VERSION "created by canmatrix"

NS_ :

BS_:

BU_:

BO_ 2164146432 LC: 8 Vector__XXX
 SG_ Running_Light_Command : 0|2@1+ (1,0) [0|3] "" Vector__XXX
 SG_ Alternate_Beam_Head_Light_Comman : 2|2@1+ (1,0) [0|3] "" Vector__XXX
 SG_ Low_Beam_Head_Light_Command : 4|2@1+ (1,0) [0|3] "" Vector__XXX
 SG_ High_Beam_Head_Light_Command : 6|2@1+ (1,0) [0|3] "" Vector__XXX
 SG_ Tractor_Front_Fog_Lights_Command : 8|2@1+ (1,0) [0|3] "" Vector__XXX
 SG_ Rotating_Beacon_Light_Command : 10|2@1+ (1,0) [0|3] "" Vector__XXX
 SG_ Right_Turn_Signal_Lights_Command : 12|2@1+ (1,0) [0|3] "" Vector__XXX
 SG_ Left_Turn_Signal_Lights_Command : 14|2@1+ (1,0) [0|3] "" Vector__XXX
 SG_ Back_Up_Light_and_Alarm_Horn_Com : 16|2@1+ (1,0) [0|3] "" Vector__XXX
 SG_ Center_Stop_Light_Command : 18|2@1+ (1,0) [0|3] "" Vector__XXX
 SG_ Right_Stop_Light_Command : 20|2@1+ (1,0) [0|3] "" Vector__XXX
 SG_ Left_Stop_Light_Command : 22|2@1+ (1,0) [0|3] "" Vector__XXX
 SG_ Implement_Clearance_Light_Comman : 24|2@1+ (1,0) [0|3] "" Vector__XXX
 SG_ Tractor_Clearance_Light_Command : 26|2@1+ (1,0) [0|3] "" Vector__XXX
 SG_ Implement_Marker_Light_Command : 28|2@1+ (1,0) [0|3] "" Vector__XXX
 SG_ Tractor_Marker_Light_Command : 30|2@1+ (1,0) [0|3] "" Vector__XXX
 SG_ Rear_Fog_Light_Command : 32|2@1+ (1,0) [0|3] "" Vector__XXX
 SG_ Tractor_Underside_Mounted_Work_L : 34|2@1+ (1,0) [0|3] "" Vector__XXX
 SG_ Tractor_Rear_Low_Mounted_Work_Li : 36|2@1+ (1,0) [0|3] "" Vector__XXX
 SG_ Tractor_Rear_High_Mounted_Work_L : 38|2@1+ (1,0) [0|3] "" Vector__XXX
 SG_ Tractor_Side_Low_Mounted_Work_Li : 40|2@1+ (1,0) [0|3] "" Vector__XXX
 SG_ Tractor_Side_High_Mounted_Work_L : 42|2@1+ (1,0) [0|3] "" Vector__XXX
 SG_ Tractor_Front_Low_Mounted_Work_L : 44|2@1+ (1,0) [0|3] "" Vector__XXX
 SG_ Tractor_Front_High_Mounted_Work_ : 46|2@1+ (1,0) [0|3] "" Vector__XXX
 SG_ Implement_OEM_Option_2_Light_Com : 48|2@1+ (1,0) [0|3] "" Vector__XXX
 SG_ Implement_OEM_Option_1_Light_Com : 50|2@1+ (1,0) [0|3] "" Vector__XXX
 SG_ Implement_Right_Facing_Work_Ligh : 52|2@1+ (1,0) [0|3] "" Vector__XXX
 SG_ Implement_Left_Facing_Work_Light : 54|2@1+ (1,0) [0|3] "" Vector__XXX
 SG_ Lighting_Data_Request_Command : 56|2@1+ (1,0) [0|3] "" Vector__XXX
 SG_ Implement_Right_Forward_Work_Lig : 58|2@1+ (1,0) [0|3] "" Vector__XXX
 SG_ Implement_Left_Forward_Work_Ligh : 60|2@1+ (1,0) [0|3] "" Vector__XXX
 SG_ Implement_Rear_Work_Light_Comman : 62|2@1+ (1,0) [0|3] "" Vector__XXX

BO_ 2164148736 ETC7: 8 Vector__XXX
 SG_ Transmission_Current_Range_Displ : 0|2@1+ (1,0) [0|3] "" Vector__XXX
 SG_ Transmission_Service_Indicator : 2|2@1+ (1,0) [0|3] "" Vector__XXX
 SG_ Transmission_Requested_Range_Dis0 : 4|2@1+ (1,0) [0|3] "" Vector__XXX
 SG_ Transmission_Requested_Range_Dis1 : 6|2@1+ (1,0) [0|3] "" Vector__XXX
 SG_ Transmission_Ready_for_Brake_Rel : 8|2@1+ (1,0) [0|3] "" Vector__XXX
 SG_ Active_Shift_Console_Indicator : 10|2@1+ (1,0) [0|3] "" Vector__XXX
 SG_ Transmission_Engine_Crank_Enable : 12|2@1+ (1,0) [0|3] "" Vector__XXX
 SG_ Transmission_Shift_Inhibit_Indic : 14|2@1+ (1,0) [0|3] "" Vector__XXX
 SG_ Transmission_Mode_4_Indicator : 16|2@1+ (1,0) [0|3] "" Vector__XXX
 SG_ Transmission_Mode_3_Indicator : 18|2@1+ (1,0) [0|3] "" Vector__XXX
 SG_ Transmission_Mode_2_Indicator : 20|2@1+ (1,0) [0|3] "" Vector__XXX
 SG_ Transmission_Mode_1_Indicator : 22|2@1+ (1,0) [0|3] "" Vector__XXX
 SG_ Transmission_Requested_Gear_Feed : 24|8@1+ (1,0) [0|255] "" Vector__XXX
 SG_ Transmission_Mode_5_Indicator : 32|2@1+ (1,0) [0|3] "" Vector__XXX
 SG_ Transmission_Mode_6_Indicator : 34|2@1+ (1,0) [0|3] "" Vector__XXX
 SG_ Transmission_Mode_7_Indicator : 36|2@1+ (1,0) [0|3] "" Vector__XXX
 SG_ Transmission_Mode_8_Indicator : 38|2@1+ (1,0) [0|3] "" Vector__XXX
 SG_ Transmission_Reverse_Gear_Shift_ : 40|2@1+ (1,0) [0|3] "" Vector__XXX

BO_ 2164148992 TCFG2: 8 Vector__XXX
 SG_ Transmission_Torque_Limit : 0|16@1+ (1,0) [0|65535] "" Vector__XXX

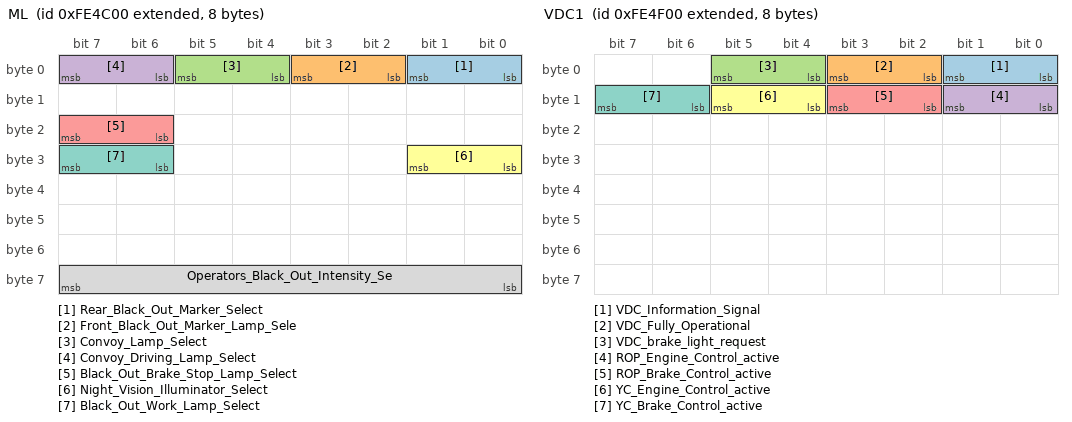
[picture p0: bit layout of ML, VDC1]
BO_ 2164149248 ML: 8 Vector__XXX
 SG_ Rear_Black_Out_Marker_Select : 0|2@1+ (1,0) [0|3] "" Vector__XXX
 SG_ Front_Black_Out_Marker_Lamp_Sele : 2|2@1+ (1,0) [0|3] "" Vector__XXX
 SG_ Convoy_Lamp_Select : 4|2@1+ (1,0) [0|3] "" Vector__XXX
 SG_ Convoy_Driving_Lamp_Select : 6|2@1+ (1,0) [0|3] "" Vector__XXX
 SG_ Black_Out_Brake_Stop_Lamp_Select : 22|2@1+ (1,0) [0|3] "" Vector__XXX
 SG_ Night_Vision_Illuminator_Select : 24|2@1+ (1,0) [0|3] "" Vector__XXX
 SG_ Black_Out_Work_Lamp_Select : 30|2@1+ (1,0) [0|3] "" Vector__XXX
 SG_ Operators_Black_Out_Intensity_Se : 56|8@1+ (1,0) [0|255] "" Vector__XXX

BO_ 2164149504 TAVG: 8 Vector__XXX
 SG_ Engine_Total_Average_Fuel_Rate : 0|16@1+ (1,0) [0|65535] "" Vector__XXX
 SG_ Engine_Total_Average_Fuel_Econom : 16|16@1+ (1,0) [0|65535] "" Vector__XXX

BO_ 2164149760 DC1: 8 Vector__XXX
 SG_ Position_of_doors : 0|4@1+ (1,0) [0|15] "" Vector__XXX
 SG_ Ramp___Wheel_Chair_Lift_Position : 4|2@1+ (1,0) [0|3] "" Vector__XXX
 SG_ Status_2_of_doors : 6|2@1+ (1,0) [0|3] "" Vector__XXX

BO_ 2164150016 VDC1: 8 Vector__XXX
 SG_ VDC_Information_Signal : 0|2@1+ (1,0) [0|3] "" Vector__XXX
 SG_ VDC_Fully_Operational : 2|2@1+ (1,0) [0|3] "" Vector__XXX
 SG_ VDC_brake_light_request : 4|2@1+ (1,0) [0|3] "" Vector__XXX
 SG_ ROP_Engine_Control_active : 8|2@1+ (1,0) [0|3] "" Vector__XXX
 SG_ ROP_Brake_Control_active : 10|2@1+ (1,0) [0|3] "" Vector__XXX
 SG_ YC_Engine_Control_active : 12|2@1+ (1,0) [0|3] "" Vector__XXX
 SG_ YC_Brake_Control_active : 14|2@1+ (1,0) [0|3] "" Vector__XXX

BO_ 2164150272 BT1: 8 Vector__XXX
 SG_ Battery_1_Temperature : 0|8@1+ (1,0) [0|255] "" Vector__XXX
 SG_ Battery_2_Temperature : 8|8@1+ (1,0) [0|255] "" Vector__XXX

BO_ 2164150528 ACC2: 8 Vector__XXX
 SG_ Requested_ACC_Distance_Mode : 5|3@1+ (1,0) [0|7] "" Vector__XXX

BO_ 2164150784 VEP3: 8 Vector__XXX
 SG_ Alternator_Current__High_Range_R : 0|16@1+ (1,0) [0|65535] "" Vector__XXX
 SG_ Net_Battery_Current__High_Range_ : 16|16@1+ (1,0) [0|65535] "" Vector__XXX

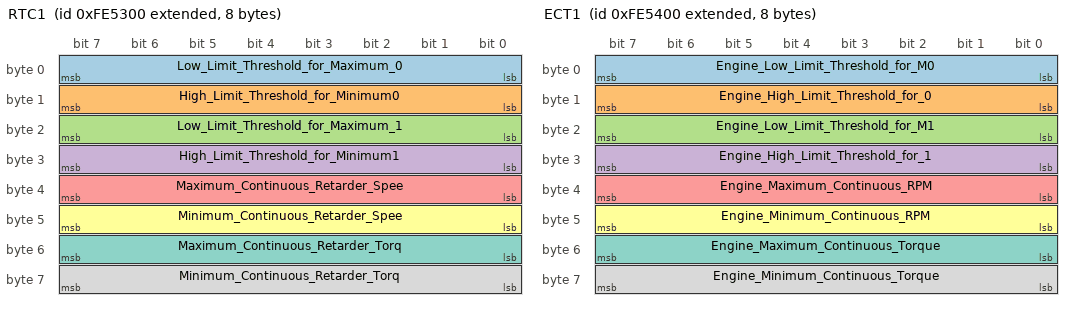
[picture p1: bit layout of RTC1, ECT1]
BO_ 2164151040 RTC1: 8 Vector__XXX
 SG_ Low_Limit_Threshold_for_Maximum_0 : 0|8@1+ (1,0) [0|255] "" Vector__XXX
 SG_ High_Limit_Threshold_for_Minimum0 : 8|8@1+ (1,0) [0|255] "" Vector__XXX
 SG_ Low_Limit_Threshold_for_Maximum_1 : 16|8@1+ (1,0) [0|255] "" Vector__XXX
 SG_ High_Limit_Threshold_for_Minimum1 : 24|8@1+ (1,0) [0|255] "" Vector__XXX
 SG_ Maximum_Continuous_Retarder_Spee : 32|8@1+ (1,0) [0|255] "" Vector__XXX
 SG_ Minimum_Continuous_Retarder_Spee : 40|8@1+ (1,0) [0|255] "" Vector__XXX
 SG_ Maximum_Continuous_Retarder_Torq : 48|8@1+ (1,0) [0|255] "" Vector__XXX
 SG_ Minimum_Continuous_Retarder_Torq : 56|8@1+ (1,0) [0|255] "" Vector__XXX

BO_ 2164151296 ECT1: 8 Vector__XXX
 SG_ Engine_Low_Limit_Threshold_for_M0 : 0|8@1+ (1,0) [0|255] "" Vector__XXX
 SG_ Engine_High_Limit_Threshold_for_0 : 8|8@1+ (1,0) [0|255] "" Vector__XXX
 SG_ Engine_Low_Limit_Threshold_for_M1 : 16|8@1+ (1,0) [0|255] "" Vector__XXX
 SG_ Engine_High_Limit_Threshold_for_1 : 24|8@1+ (1,0) [0|255] "" Vector__XXX
 SG_ Engine_Maximum_Continuous_RPM : 32|8@1+ (1,0) [0|255] "" Vector__XXX
 SG_ Engine_Minimum_Continuous_RPM : 40|8@1+ (1,0) [0|255] "" Vector__XXX
 SG_ Engine_Maximum_Continuous_Torque : 48|8@1+ (1,0) [0|255] "" Vector__XXX
 SG_ Engine_Minimum_Continuous_Torque : 56|8@1+ (1,0) [0|255] "" Vector__XXX

BO_ 2164151552 GFD: 8 Vector__XXX
 SG_ Specific_Heat_Ratio : 0|16@1+ (1,0) [0|65535] "" Vector__XXX

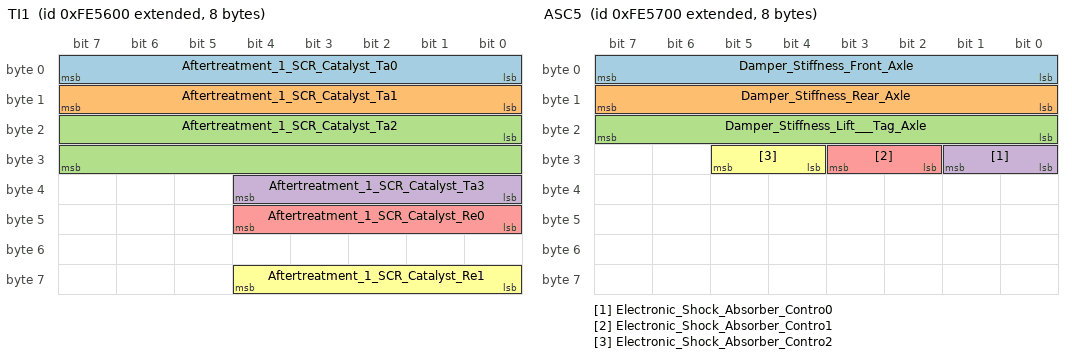
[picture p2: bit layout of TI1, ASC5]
BO_ 2164151808 TI1: 8 Vector__XXX
 SG_ Aftertreatment_1_SCR_Catalyst_Ta0 : 0|8@1+ (1,0) [0|255] "" Vector__XXX
 SG_ Aftertreatment_1_SCR_Catalyst_Ta1 : 8|8@1+ (1,0) [0|255] "" Vector__XXX
 SG_ Aftertreatment_1_SCR_Catalyst_Ta2 : 16|16@1+ (1,0) [0|65535] "" Vector__XXX
 SG_ Aftertreatment_1_SCR_Catalyst_Ta3 : 32|5@1+ (1,0) [0|31] "" Vector__XXX
 SG_ Aftertreatment_1_SCR_Catalyst_Re0 : 40|5@1+ (1,0) [0|31] "" Vector__XXX
 SG_ Aftertreatment_1_SCR_Catalyst_Re1 : 56|5@1+ (1,0) [0|31] "" Vector__XXX

BO_ 2164152064 ASC5: 8 Vector__XXX
 SG_ Damper_Stiffness_Front_Axle : 0|8@1+ (1,0) [0|255] "" Vector__XXX
 SG_ Damper_Stiffness_Rear_Axle : 8|8@1+ (1,0) [0|255] "" Vector__XXX
 SG_ Damper_Stiffness_Lift___Tag_Axle : 16|8@1+ (1,0) [0|255] "" Vector__XXX
 SG_ Electronic_Shock_Absorber_Contro0 : 24|2@1+ (1,0) [0|3] "" Vector__XXX
 SG_ Electronic_Shock_Absorber_Contro1 : 26|2@1+ (1,0) [0|3] "" Vector__XXX
 SG_ Electronic_Shock_Absorber_Contro2 : 28|2@1+ (1,0) [0|3] "" Vector__XXX

BO_ 2164152320 ASC4: 8 Vector__XXX
 SG_ Bellow_Pressure_Front_Axle_Left : 0|16@1+ (1,0) [0|65535] "" Vector__XXX
 SG_ Bellow_Pressure_Front_Axle_Right : 16|16@1+ (1,0) [0|65535] "" Vector__XXX
 SG_ Bellow_Pressure_Rear_Axle_Left : 32|16@1+ (1,0) [0|65535] "" Vector__XXX
 SG_ Bellow_Pressure_Rear_Axle_Right : 48|16@1+ (1,0) [0|65535] "" Vector__XXX

BO_ 2164152576 ASC3: 8 Vector__XXX
 SG_ Relative_Level_Front_Axle_Left : 0|16@1+ (1,0) [0|65535] "" Vector__XXX
 SG_ Relative_Level_Front_Axle_Right : 16|16@1+ (1,0) [0|65535] "" Vector__XXX
 SG_ Relative_Level_Rear_Axle_Left : 32|16@1+ (1,0) [0|65535] "" Vector__XXX
 SG_ Relative_Level_Rear_Axle_Right : 48|16@1+ (1,0) [0|65535] "" Vector__XXX

BO_ 2164152832 ASC1: 8 Vector__XXX
 SG_ Nominal_Level_Front_Axle : 0|4@1+ (1,0) [0|15] "" Vector__XXX
 SG_ Nominal_Level_Rear_Axle : 4|4@1+ (1,0) [0|15] "" Vector__XXX
 SG_ Below_Nominal_Level_Front_Axle : 8|2@1+ (1,0) [0|3] "" Vector__XXX
 SG_ Below_Nominal_Level_Rear_Axle : 10|2@1+ (1,0) [0|3] "" Vector__XXX
 SG_ Above_Nominal_Level_Front_Axle : 12|2@1+ (1,0) [0|3] "" Vector__XXX
 SG_ Above_Nominal_Level_Rear_Axle : 14|2@1+ (1,0) [0|3] "" Vector__XXX
 SG_ Lowering_Control_Mode_Front_Axle : 16|2@1+ (1,0) [0|3] "" Vector__XXX
 SG_ Lowering_Control_Mode_Rear_Axle : 18|2@1+ (1,0) [0|3] "" Vector__XXX
 SG_ Lifting_Control_Mode_Front_Axle : 20|2@1+ (1,0) [0|3] "" Vector__XXX
 SG_ Lifting_Control_Mode_Rear_Axle : 22|2@1+ (1,0) [0|3] "" Vector__XXX
 SG_ Kneeling_Information : 24|4@1+ (1,0) [0|15] "" Vector__XXX
 SG_ Level_Control_Mode : 28|4@1+ (1,0) [0|15] "" Vector__XXX
 SG_ Security_Device : 32|2@1+ (1,0) [0|3] "" Vector__XXX
 SG_ Vehicle_Motion_Inhibit : 34|2@1+ (1,0) [0|3] "" Vector__XXX
 SG_ Door_Release : 36|2@1+ (1,0) [0|3] "" Vector__XXX
 SG_ Lift_Axle_1_Position : 38|2@1+ (1,0) [0|3] "" Vector__XXX
 SG_ Front_Axle_in_Bumper_Range : 40|2@1+ (1,0) [0|3] "" Vector__XXX
 SG_ Rear_Axle_in_Bumper_Range : 42|2@1+ (1,0) [0|3] "" Vector__XXX
 SG_ Lift_Axle_2_Position : 46|2@1+ (1,0) [0|3] "" Vector__XXX
 SG_ Suspension_Remote_Control_1 : 48|2@1+ (1,0) [0|3] "" Vector__XXX
 SG_ Suspension_Remote_control_2 : 50|2@1+ (1,0) [0|3] "" Vector__XXX
 SG_ Suspension_Control_Refusal_Infor : 56|4@1+ (1,0) [0|15] "" Vector__XXX

BO_ 2164153088 FLI2: 8 Vector__XXX
 SG_ Lane_Tracking_Status_Right_Side : 2|2@1+ (1,0) [0|3] "" Vector__XXX
 SG_ Lane_Tracking_Status_Left_Side : 4|2@1+ (1,0) [0|3] "" Vector__XXX
 SG_ Lane_Departure_Indication_Enable : 6|2@1+ (1,0) [0|3] "" Vector__XXX

BO_ 2164155904 BM: 8 Vector__XXX
 SG_ Battery_Main_Switch_Hold_State : 0|2@1+ (1,0) [0|3] "" Vector__XXX

BO_ 2164156160 CCC: 8 Vector__XXX
 SG_ Auxiliary_Heater_Maximum_Output_ : 0|16@1+ (1,0) [0|65535] "" Vector__XXX

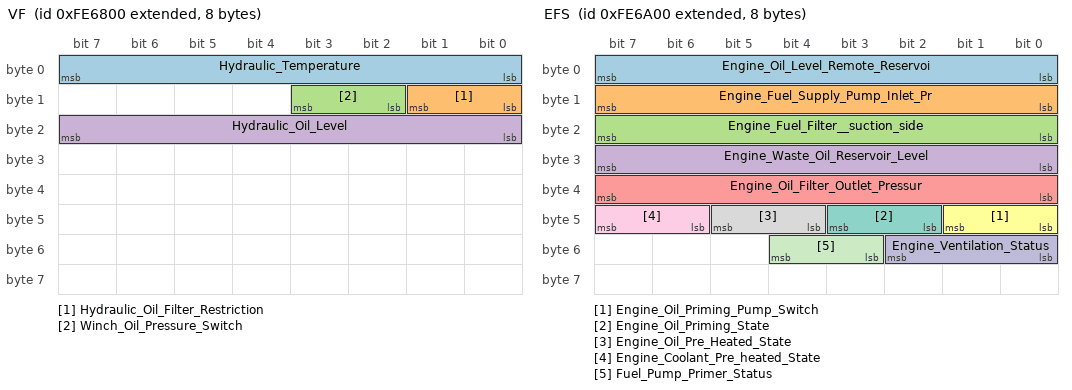
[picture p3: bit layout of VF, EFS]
BO_ 2164156416 VF: 8 Vector__XXX
 SG_ Hydraulic_Temperature : 0|8@1+ (1,0) [0|255] "" Vector__XXX
 SG_ Hydraulic_Oil_Filter_Restriction : 8|2@1+ (1,0) [0|3] "" Vector__XXX
 SG_ Winch_Oil_Pressure_Switch : 10|2@1+ (1,0) [0|3] "" Vector__XXX
 SG_ Hydraulic_Oil_Level : 16|8@1+ (1,0) [0|255] "" Vector__XXX

BO_ 2164156672 ET3: 8 Vector__XXX
 SG_ Engine_Intake_Manifold_1_Air_Tem : 0|16@1+ (1,0) [0|65535] "" Vector__XXX
 SG_ Engine_Coolant_Temperature__High : 16|16@1+ (1,0) [0|65535] "" Vector__XXX
 SG_ Engine_Intake_Valve_Actuation_Sy : 32|16@1+ (1,0) [0|65535] "" Vector__XXX
 SG_ Engine_Charge_Air_Cooler_Outlet_ : 48|16@1+ (1,0) [0|65535] "" Vector__XXX

BO_ 2164156928 EFS: 8 Vector__XXX
 SG_ Engine_Oil_Level_Remote_Reservoi : 0|8@1+ (1,0) [0|255] "" Vector__XXX
 SG_ Engine_Fuel_Supply_Pump_Inlet_Pr : 8|8@1+ (1,0) [0|255] "" Vector__XXX
 SG_ Engine_Fuel_Filter__suction_side : 16|8@1+ (1,0) [0|255] "" Vector__XXX
 SG_ Engine_Waste_Oil_Reservoir_Level : 24|8@1+ (1,0) [0|255] "" Vector__XXX
 SG_ Engine_Oil_Filter_Outlet_Pressur : 32|8@1+ (1,0) [0|255] "" Vector__XXX
 SG_ Engine_Oil_Priming_Pump_Switch : 40|2@1+ (1,0) [0|3] "" Vector__XXX
 SG_ Engine_Oil_Priming_State : 42|2@1+ (1,0) [0|3] "" Vector__XXX
 SG_ Engine_Oil_Pre_Heated_State : 44|2@1+ (1,0) [0|3] "" Vector__XXX
 SG_ Engine_Coolant_Pre_heated_State : 46|2@1+ (1,0) [0|3] "" Vector__XXX
 SG_ Engine_Ventilation_Status : 48|3@1+ (1,0) [0|7] "" Vector__XXX
 SG_ Fuel_Pump_Primer_Status : 51|2@1+ (1,0) [0|3] "" Vector__XXX

BO_ 2164157184 DI: 8 Vector__XXX
 SG_ Driver_1_identification : 0|13824@1+ (1,0) [0|2.745744098767810851571364370E+4161] "" Vector__XXX
 SG_ Driver_2_identification : 16|13824@1+ (1,0) [0|2.745744098767810851571364370E+4161] "" Vector__XXX

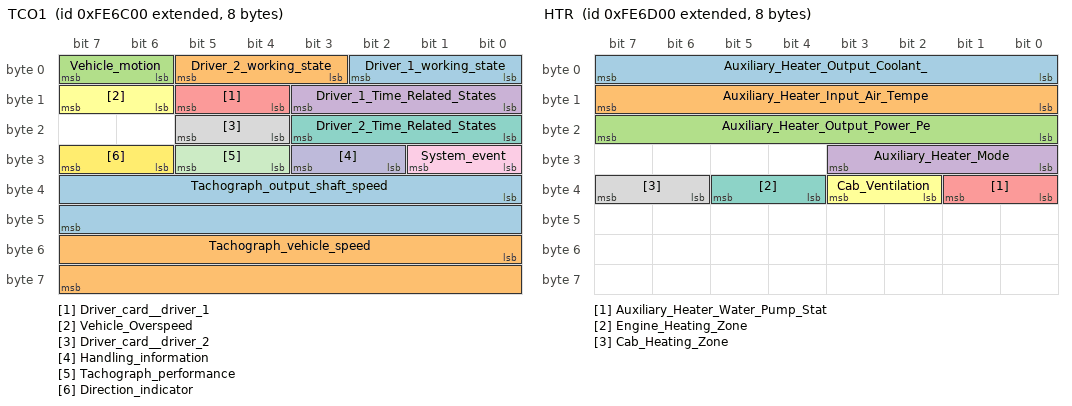
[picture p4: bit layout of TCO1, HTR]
BO_ 2164157440 TCO1: 8 Vector__XXX
 SG_ Driver_1_working_state : 0|3@1+ (1,0) [0|7] "" Vector__XXX
 SG_ Driver_2_working_state : 3|3@1+ (1,0) [0|7] "" Vector__XXX
 SG_ Vehicle_motion : 6|2@1+ (1,0) [0|3] "" Vector__XXX
 SG_ Driver_1_Time_Related_States : 8|4@1+ (1,0) [0|15] "" Vector__XXX
 SG_ Driver_card__driver_1 : 12|2@1+ (1,0) [0|3] "" Vector__XXX
 SG_ Vehicle_Overspeed : 14|2@1+ (1,0) [0|3] "" Vector__XXX
 SG_ Driver_2_Time_Related_States : 16|4@1+ (1,0) [0|15] "" Vector__XXX
 SG_ Driver_card__driver_2 : 20|2@1+ (1,0) [0|3] "" Vector__XXX
 SG_ System_event : 24|2@1+ (1,0) [0|3] "" Vector__XXX
 SG_ Handling_information : 26|2@1+ (1,0) [0|3] "" Vector__XXX
 SG_ Tachograph_performance : 28|2@1+ (1,0) [0|3] "" Vector__XXX
 SG_ Direction_indicator : 30|2@1+ (1,0) [0|3] "" Vector__XXX
 SG_ Tachograph_output_shaft_speed : 32|16@1+ (1,0) [0|65535] "" Vector__XXX
 SG_ Tachograph_vehicle_speed : 48|16@1+ (1,0) [0|65535] "" Vector__XXX

BO_ 2164157696 HTR: 8 Vector__XXX
 SG_ Auxiliary_Heater_Output_Coolant_ : 0|8@1+ (1,0) [0|255] "" Vector__XXX
 SG_ Auxiliary_Heater_Input_Air_Tempe : 8|8@1+ (1,0) [0|255] "" Vector__XXX
 SG_ Auxiliary_Heater_Output_Power_Pe : 16|8@1+ (1,0) [0|255] "" Vector__XXX
 SG_ Auxiliary_Heater_Mode : 24|4@1+ (1,0) [0|15] "" Vector__XXX
 SG_ Auxiliary_Heater_Water_Pump_Stat : 32|2@1+ (1,0) [0|3] "" Vector__XXX
 SG_ Cab_Ventilation : 34|2@1+ (1,0) [0|3] "" Vector__XXX
 SG_ Engine_Heating_Zone : 36|2@1+ (1,0) [0|3] "" Vector__XXX
 SG_ Cab_Heating_Zone : 38|2@1+ (1,0) [0|3] "" Vector__XXX

BO_ 2164157952 HRW: 8 Vector__XXX
 SG_ Front_Axle__Left_Wheel_Speed : 0|16@1+ (1,0) [0|65535] "" Vector__XXX
 SG_ Front_axle__right_wheel_speed : 16|16@1+ (1,0) [0|65535] "" Vector__XXX
 SG_ Rear_axle__left_wheel_speed : 32|16@1+ (1,0) [0|65535] "" Vector__XXX
 SG_ Rear_axle__right_wheel_speed : 48|16@1+ (1,0) [0|65535] "" Vector__XXX

BO_ 2164158208 ACC1: 8 Vector__XXX
 SG_ Speed_of_forward_vehicle : 0|8@1+ (1,0) [0|255] "" Vector__XXX
 SG_ Distance_to_forward_vehicle : 8|8@1+ (1,0) [0|255] "" Vector__XXX
 SG_ Adaptive_Cruise_Control_Set_Spee : 16|8@1+ (1,0) [0|255] "" Vector__XXX
 SG_ Adaptive_Cruise_Control_Mode : 24|3@1+ (1,0) [0|7] "" Vector__XXX
 SG_ Adaptive_cruise_control_set_dist : 27|3@1+ (1,0) [0|7] "" Vector__XXX
 SG_ Road_curvature : 32|16@1+ (1,0) [0|65535] "" Vector__XXX
 SG_ ACC_Target_Detected : 48|2@1+ (1,0) [0|3] "" Vector__XXX
 SG_ ACC_System_Shutoff_Warning : 50|2@1+ (1,0) [0|3] "" Vector__XXX
 SG_ ACC_Distance_Alert_Signal : 52|2@1+ (1,0) [0|3] "" Vector__XXX

BO_ 2164158464 CVW: 8 Vector__XXX
 SG_ Powered_Vehicle_Weight : 0|16@1+ (1,0) [0|65535] "" Vector__XXX
 SG_ Gross_Combination_Vehicle_Weight : 16|16@1+ (1,0) [0|65535] "" Vector__XXX

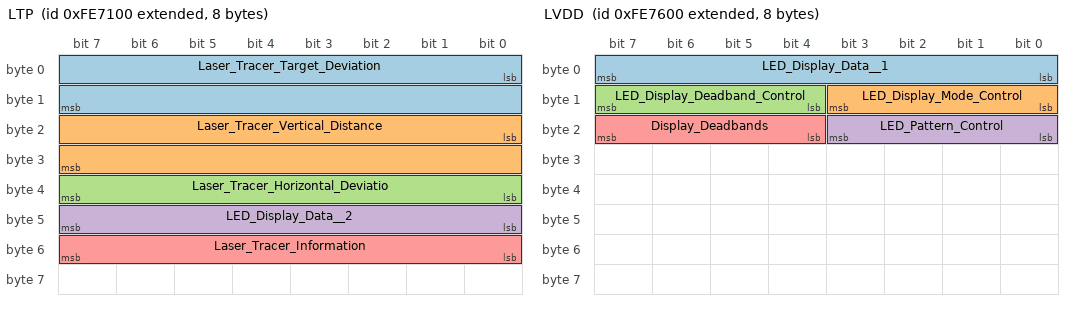
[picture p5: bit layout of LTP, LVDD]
BO_ 2164158720 LTP: 8 Vector__XXX
 SG_ Laser_Tracer_Target_Deviation : 0|16@1+ (1,0) [0|65535] "" Vector__XXX
 SG_ Laser_Tracer_Vertical_Distance : 16|16@1+ (1,0) [0|65535] "" Vector__XXX
 SG_ Laser_Tracer_Horizontal_Deviatio : 32|8@1+ (1,0) [0|255] "" Vector__XXX
 SG_ LED_Display_Data__2 : 40|8@1+ (1,0) [0|255] "" Vector__XXX
 SG_ Laser_Tracer_Information : 48|8@1+ (1,0) [0|255] "" Vector__XXX

BO_ 2164158976 LBC: 8 Vector__XXX
 SG_ Blade_Duration_and_Direction : 0|16@1+ (1,0) [0|65535] "" Vector__XXX
 SG_ Blade_Control_Mode : 16|8@1+ (1,0) [0|255] "" Vector__XXX

BO_ 2164159232 LMP: 8 Vector__XXX
 SG_ Mast_Position : 0|16@1+ (1,0) [0|65535] "" Vector__XXX

BO_ 2164159488 LSP: 8 Vector__XXX
 SG_ Modify_Leveling_System_Set_Point : 0|16@1+ (1,0) [0|65535] "" Vector__XXX
 SG_ Blade_Height_Set_Point___High_Re : 16|32@1+ (1,0) [0|4294967295] "" Vector__XXX

BO_ 2164159744 LVD: 8 Vector__XXX
 SG_ Laser_Strike_Vertical_Deviation : 0|16@1+ (1,0) [0|65535] "" Vector__XXX
 SG_ Laser_Receiver_Type : 16|8@1+ (1,0) [0|255] "" Vector__XXX
 SG_ Laser_Strike_Data_Latency : 24|16@1+ (1,0) [0|65535] "" Vector__XXX
 SG_ Absolute_Laser_Strike_Position : 40|16@1+ (1,0) [0|65535] "" Vector__XXX

BO_ 2164160000 LVDD: 8 Vector__XXX
 SG_ LED_Display_Data__1 : 0|8@1+ (1,0) [0|255] "" Vector__XXX
 SG_ LED_Display_Mode_Control : 8|4@1+ (1,0) [0|15] "" Vector__XXX
 SG_ LED_Display_Deadband_Control : 12|4@1+ (1,0) [0|15] "" Vector__XXX
 SG_ LED_Pattern_Control : 16|4@1+ (1,0) [0|15] "" Vector__XXX
 SG_ Display_Deadbands : 20|4@1+ (1,0) [0|15] "" Vector__XXX

BO_ 2164160256 AP: 8 Vector__XXX
 SG_ Auxiliary_Vacuum_Pressure_Readin : 0|16@1+ (1,0) [0|65535] "" Vector__XXX
 SG_ Auxiliary_Gage_Pressure_Reading_ : 16|16@1+ (1,0) [0|65535] "" Vector__XXX
 SG_ Auxiliary_Absolute_Pressure_Read : 32|16@1+ (1,0) [0|65535] "" Vector__XXX

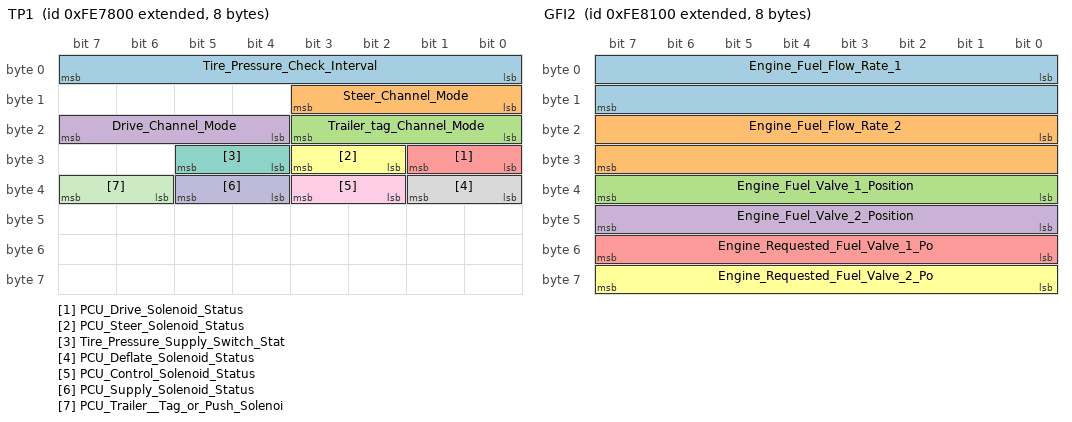
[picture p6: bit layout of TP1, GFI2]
BO_ 2164160512 TP1: 8 Vector__XXX
 SG_ Tire_Pressure_Check_Interval : 0|8@1+ (1,0) [0|255] "" Vector__XXX
 SG_ Steer_Channel_Mode : 8|4@1+ (1,0) [0|15] "" Vector__XXX
 SG_ Trailer_tag_Channel_Mode : 16|4@1+ (1,0) [0|15] "" Vector__XXX
 SG_ Drive_Channel_Mode : 20|4@1+ (1,0) [0|15] "" Vector__XXX
 SG_ PCU_Drive_Solenoid_Status : 24|2@1+ (1,0) [0|3] "" Vector__XXX
 SG_ PCU_Steer_Solenoid_Status : 26|2@1+ (1,0) [0|3] "" Vector__XXX
 SG_ Tire_Pressure_Supply_Switch_Stat : 28|2@1+ (1,0) [0|3] "" Vector__XXX
 SG_ PCU_Deflate_Solenoid_Status : 32|2@1+ (1,0) [0|3] "" Vector__XXX
 SG_ PCU_Control_Solenoid_Status : 34|2@1+ (1,0) [0|3] "" Vector__XXX
 SG_ PCU_Supply_Solenoid_Status : 36|2@1+ (1,0) [0|3] "" Vector__XXX
 SG_ PCU_Trailer__Tag_or_Push_Solenoi : 38|2@1+ (1,0) [0|3] "" Vector__XXX

BO_ 2164160768 TP2: 8 Vector__XXX
 SG_ Trailer__Tag_Or_Push_Channel_Tir : 0|16@1+ (1,0) [0|65535] "" Vector__XXX
 SG_ Drive_Channel_Tire_Pressure_Targ : 16|16@1+ (1,0) [0|65535] "" Vector__XXX
 SG_ Steer_Channel_Tire_Pressure_Targ : 32|16@1+ (1,0) [0|65535] "" Vector__XXX

BO_ 2164161024 TP3: 8 Vector__XXX
 SG_ Trailer__Tag_Or_Push_Channel_Tir : 0|16@1+ (1,0) [0|65535] "" Vector__XXX
 SG_ Drive_Channel_Tire_Pressure : 16|16@1+ (1,0) [0|65535] "" Vector__XXX
 SG_ Steer_Channel_Tire_Pressure : 32|16@1+ (1,0) [0|65535] "" Vector__XXX

BO_ 2164161280 CT1: 8 Vector__XXX
 SG_ Engine_Cylinder__1_Combustion_Ti : 0|16@1+ (1,0) [0|65535] "" Vector__XXX
 SG_ Engine_Cylinder__2_Combustion_Ti : 16|16@1+ (1,0) [0|65535] "" Vector__XXX
 SG_ Engine_Cylinder__3_Combustion_Ti : 32|16@1+ (1,0) [0|65535] "" Vector__XXX
 SG_ Engine_Cylinder__4_Combustion_Ti : 48|16@1+ (1,0) [0|65535] "" Vector__XXX

BO_ 2164161536 CT2: 8 Vector__XXX
 SG_ Engine_Cylinder__5_Combustion_Ti : 0|16@1+ (1,0) [0|65535] "" Vector__XXX
 SG_ Engine_Cylinder__6_Combustion_Ti : 16|16@1+ (1,0) [0|65535] "" Vector__XXX
 SG_ Engine_Cylinder__7_Combustion_Ti : 32|16@1+ (1,0) [0|65535] "" Vector__XXX
 SG_ Engine_Cylinder__8_Combustion_Ti : 48|16@1+ (1,0) [0|65535] "" Vector__XXX

BO_ 2164161792 CT3: 8 Vector__XXX
 SG_ Engine_Cylinder__9_Combustion_Ti : 0|16@1+ (1,0) [0|65535] "" Vector__XXX
 SG_ Engine_Cylinder__10_Combustion_T : 16|16@1+ (1,0) [0|65535] "" Vector__XXX
 SG_ Engine_Cylinder__11_Combustion_T : 32|16@1+ (1,0) [0|65535] "" Vector__XXX
 SG_ Engine_Cylinder__12_Combustion_T : 48|16@1+ (1,0) [0|65535] "" Vector__XXX

BO_ 2164162048 CT4: 8 Vector__XXX
 SG_ Engine_Cylinder__13_Combustion_T : 0|16@1+ (1,0) [0|65535] "" Vector__XXX
 SG_ Engine_Cylinder__14_Combustion_T : 16|16@1+ (1,0) [0|65535] "" Vector__XXX
 SG_ Engine_Cylinder__15_Combustion_T : 32|16@1+ (1,0) [0|65535] "" Vector__XXX
 SG_ Engine_Cylinder__16_Combustion_T : 48|16@1+ (1,0) [0|65535] "" Vector__XXX

BO_ 2164162304 CT5: 8 Vector__XXX
 SG_ Engine_Cylinder__17_Combustion_T : 0|16@1+ (1,0) [0|65535] "" Vector__XXX
 SG_ Engine_Cylinder__18_Combustion_T : 16|16@1+ (1,0) [0|65535] "" Vector__XXX
 SG_ Engine_Cylinder__19_Combustion_T : 32|16@1+ (1,0) [0|65535] "" Vector__XXX
 SG_ Engine_Cylinder__20_Combustion_T : 48|16@1+ (1,0) [0|65535] "" Vector__XXX

BO_ 2164162560 CT6: 8 Vector__XXX
 SG_ Engine_Desired_Combustion_Time : 0|16@1+ (1,0) [0|65535] "" Vector__XXX
 SG_ Engine_Average_Combustion_Time : 16|16@1+ (1,0) [0|65535] "" Vector__XXX

BO_ 2164162816 GFI2: 8 Vector__XXX
 SG_ Engine_Fuel_Flow_Rate_1 : 0|16@1+ (1,0) [0|65535] "" Vector__XXX
 SG_ Engine_Fuel_Flow_Rate_2 : 16|16@1+ (1,0) [0|65535] "" Vector__XXX
 SG_ Engine_Fuel_Valve_1_Position : 32|8@1+ (1,0) [0|255] "" Vector__XXX
 SG_ Engine_Fuel_Valve_2_Position : 40|8@1+ (1,0) [0|255] "" Vector__XXX
 SG_ Engine_Requested_Fuel_Valve_1_Po : 48|8@1+ (1,0) [0|255] "" Vector__XXX
 SG_ Engine_Requested_Fuel_Valve_2_Po : 56|8@1+ (1,0) [0|255] "" Vector__XXX

BO_ 2164163072 IT1: 8 Vector__XXX
 SG_ Engine_Cylinder__1_Ignition_Timi : 0|16@1+ (1,0) [0|65535] "" Vector__XXX
 SG_ Engine_Cylinder__2_Ignition_Timi : 16|16@1+ (1,0) [0|65535] "" Vector__XXX
 SG_ Engine_Cylinder__3_Ignition_Timi : 32|16@1+ (1,0) [0|65535] "" Vector__XXX
 SG_ Engine_Cylinder__4_Ignition_Timi : 48|16@1+ (1,0) [0|65535] "" Vector__XXX

BO_ 2164163328 IT2: 8 Vector__XXX
 SG_ Engine_Cylinder__5_Ignition_Timi : 0|16@1+ (1,0) [0|65535] "" Vector__XXX
 SG_ Engine_Cylinder__6_Ignition_Timi : 16|16@1+ (1,0) [0|65535] "" Vector__XXX
 SG_ Engine_Cylinder__7_Ignition_Timi : 32|16@1+ (1,0) [0|65535] "" Vector__XXX
 SG_ Engine_Cylinder__8_Ignition_Timi : 48|16@1+ (1,0) [0|65535] "" Vector__XXX

BO_ 2164163584 IT3: 8 Vector__XXX
 SG_ Engine_Cylinder__9_Ignition_Timi : 0|16@1+ (1,0) [0|65535] "" Vector__XXX
 SG_ Engine_Cylinder__10_Ignition_Tim : 16|16@1+ (1,0) [0|65535] "" Vector__XXX
 SG_ Engine_Cylinder__11_Ignition_Tim : 32|16@1+ (1,0) [0|65535] "" Vector__XXX
 SG_ Engine_Cylinder__12_Ignition_Tim : 48|16@1+ (1,0) [0|65535] "" Vector__XXX

BO_ 2164163840 IT4: 8 Vector__XXX
 SG_ Engine_Cylinder__13_Ignition_Tim : 0|16@1+ (1,0) [0|65535] "" Vector__XXX
 SG_ Engine_Cylinder__14_Ignition_Tim : 16|16@1+ (1,0) [0|65535] "" Vector__XXX
 SG_ Engine_Cylinder__15_Ignition_Tim : 32|16@1+ (1,0) [0|65535] "" Vector__XXX
 SG_ Engine_Cylinder__16_Ignition_Tim : 48|16@1+ (1,0) [0|65535] "" Vector__XXX

BO_ 2164164096 IT5: 8 Vector__XXX
 SG_ Engine_Cylinder__17_Ignition_Tim : 0|16@1+ (1,0) [0|65535] "" Vector__XXX
 SG_ Engine_Cylinder__18_Ignition_Tim : 16|16@1+ (1,0) [0|65535] "" Vector__XXX
 SG_ Engine_Cylinder__19_Ignition_Tim : 32|16@1+ (1,0) [0|65535] "" Vector__XXX
 SG_ Engine_Cylinder__20_Ignition_Tim : 48|16@1+ (1,0) [0|65535] "" Vector__XXX

BO_ 2164164352 IT6: 8 Vector__XXX
 SG_ Engine_Desired_Ignition_Timing__0 : 0|16@1+ (1,0) [0|65535] "" Vector__XXX
 SG_ Engine_Desired_Ignition_Timing__1 : 16|16@1+ (1,0) [0|65535] "" Vector__XXX
 SG_ Engine_Desired_Ignition_Timing__2 : 32|16@1+ (1,0) [0|65535] "" Vector__XXX
 SG_ Engine_Actual_Ignition_Timing : 48|16@1+ (1,0) [0|65535] "" Vector__XXX

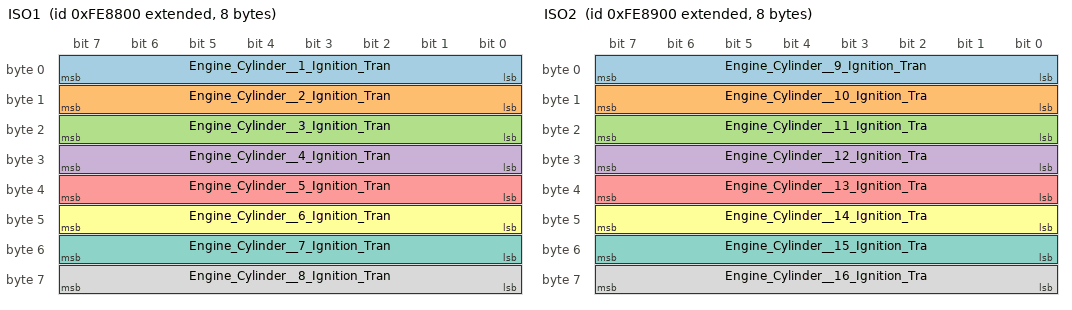
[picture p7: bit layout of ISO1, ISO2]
BO_ 2164164608 ISO1: 8 Vector__XXX
 SG_ Engine_Cylinder__1_Ignition_Tran : 0|8@1+ (1,0) [0|255] "" Vector__XXX
 SG_ Engine_Cylinder__2_Ignition_Tran : 8|8@1+ (1,0) [0|255] "" Vector__XXX
 SG_ Engine_Cylinder__3_Ignition_Tran : 16|8@1+ (1,0) [0|255] "" Vector__XXX
 SG_ Engine_Cylinder__4_Ignition_Tran : 24|8@1+ (1,0) [0|255] "" Vector__XXX
 SG_ Engine_Cylinder__5_Ignition_Tran : 32|8@1+ (1,0) [0|255] "" Vector__XXX
 SG_ Engine_Cylinder__6_Ignition_Tran : 40|8@1+ (1,0) [0|255] "" Vector__XXX
 SG_ Engine_Cylinder__7_Ignition_Tran : 48|8@1+ (1,0) [0|255] "" Vector__XXX
 SG_ Engine_Cylinder__8_Ignition_Tran : 56|8@1+ (1,0) [0|255] "" Vector__XXX

BO_ 2164164864 ISO2: 8 Vector__XXX
 SG_ Engine_Cylinder__9_Ignition_Tran : 0|8@1+ (1,0) [0|255] "" Vector__XXX
 SG_ Engine_Cylinder__10_Ignition_Tra : 8|8@1+ (1,0) [0|255] "" Vector__XXX
 SG_ Engine_Cylinder__11_Ignition_Tra : 16|8@1+ (1,0) [0|255] "" Vector__XXX
 SG_ Engine_Cylinder__12_Ignition_Tra : 24|8@1+ (1,0) [0|255] "" Vector__XXX
 SG_ Engine_Cylinder__13_Ignition_Tra : 32|8@1+ (1,0) [0|255] "" Vector__XXX
 SG_ Engine_Cylinder__14_Ignition_Tra : 40|8@1+ (1,0) [0|255] "" Vector__XXX
 SG_ Engine_Cylinder__15_Ignition_Tra : 48|8@1+ (1,0) [0|255] "" Vector__XXX
 SG_ Engine_Cylinder__16_Ignition_Tra : 56|8@1+ (1,0) [0|255] "" Vector__XXX

BO_ 2164165120 ISO3: 8 Vector__XXX
 SG_ Engine_Cylinder__17_Ignition_Tra : 0|8@1+ (1,0) [0|255] "" Vector__XXX
 SG_ Engine_Cylinder__18_Ignition_Tra : 8|8@1+ (1,0) [0|255] "" Vector__XXX
 SG_ Engine_Cylinder__19_Ignition_Tra : 16|8@1+ (1,0) [0|255] "" Vector__XXX
 SG_ Engine_Cylinder__20_Ignition_Tra : 24|8@1+ (1,0) [0|255] "" Vector__XXX

BO_ 2164165376 GFP: 8 Vector__XXX
 SG_ Engine_Fuel_Valve_1_Inlet_Absolu : 0|16@1+ (1,0) [0|65535] "" Vector__XXX
 SG_ Engine_Fuel_Valve_Differential_P : 16|16@1+ (1,0) [0|65535] "" Vector__XXX
 SG_ Engine_Air_to_Fuel_Differential_ : 32|16@1+ (1,0) [0|65535] "" Vector__XXX
 SG_ Engine_Fuel_Valve_1_Outlet_Abso : 48|16@1+ (1,0) [0|65535] "" Vector__XXX

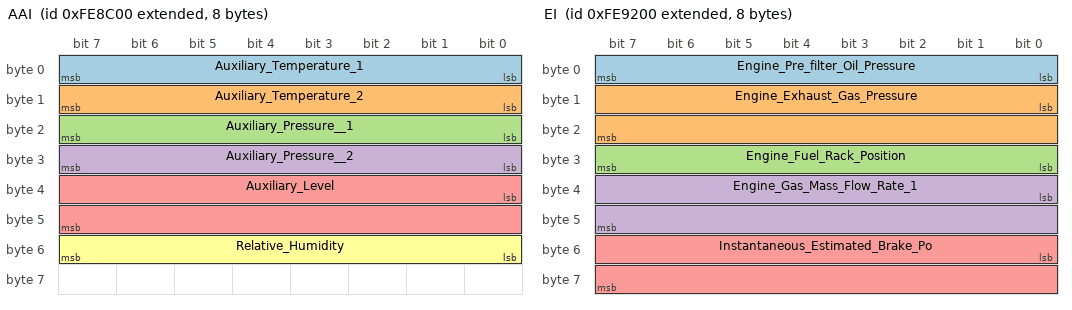
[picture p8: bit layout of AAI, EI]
BO_ 2164165632 AAI: 8 Vector__XXX
 SG_ Auxiliary_Temperature_1 : 0|8@1+ (1,0) [0|255] "" Vector__XXX
 SG_ Auxiliary_Temperature_2 : 8|8@1+ (1,0) [0|255] "" Vector__XXX
 SG_ Auxiliary_Pressure__1 : 16|8@1+ (1,0) [0|255] "" Vector__XXX
 SG_ Auxiliary_Pressure__2 : 24|8@1+ (1,0) [0|255] "" Vector__XXX
 SG_ Auxiliary_Level : 32|16@1+ (1,0) [0|65535] "" Vector__XXX
 SG_ Relative_Humidity : 48|8@1+ (1,0) [0|255] "" Vector__XXX

BO_ 2164165888 VEP2: 8 Vector__XXX
 SG_ Battery_Potential___Power_Input_ : 0|16@1+ (1,0) [0|65535] "" Vector__XXX
 SG_ ECU_Power_Output_Supply_Voltage_0 : 16|16@1+ (1,0) [0|65535] "" Vector__XXX
 SG_ ECU_Power_Output_Supply_Voltage_1 : 32|16@1+ (1,0) [0|65535] "" Vector__XXX
 SG_ ECU_Power_Output_Supply_Voltage_2 : 48|16@1+ (1,0) [0|65535] "" Vector__XXX

BO_ 2164166144 S2: 8 Vector__XXX
 SG_ Service_Component_Identification : 0|8@1+ (1,0) [0|255] "" Vector__XXX
 SG_ Time_Since_Last_Service : 8|16@1+ (1,0) [0|65535] "" Vector__XXX

BO_ 2164166400 SP2: 8 Vector__XXX
 SG_ Engine_External_Shutdown_Air_Sup : 0|16@1+ (1,0) [0|65535] "" Vector__XXX

BO_ 2164166656 ETH: 8 Vector__XXX
 SG_ Number_of_Engine_Torque_History_ : 0|8@1+ (1,0) [0|255] "" Vector__XXX
 SG_ Engine_Power : 8|16@1+ (1,0) [0|65535] "" Vector__XXX
 SG_ Engine_Peak_Torque_1 : 24|16@1+ (1,0) [0|65535] "" Vector__XXX
 SG_ Engine_Peak_Torque_2 : 40|16@1+ (1,0) [0|65535] "" Vector__XXX
 SG_ Calibration_Record_Start_Month : 56|8@1+ (1,0) [0|255] "" Vector__XXX
 SG_ Calibration_Record_Start_Day : 64|8@1+ (1,0) [0|255] "" Vector__XXX
 SG_ Calibration_Record_Start_Year : 72|8@1+ (1,0) [0|255] "" Vector__XXX
 SG_ Calibration_Record_Duration_Time : 80|32@1+ (1,0) [0|4294967295] "" Vector__XXX
 SG_ Torque_Limiting_Feature_Status : 112|2@1+ (1,0) [0|3] "" Vector__XXX
 SG_ Engine_Torque_Limit_Feature : 114|3@1+ (1,0) [0|7] "" Vector__XXX
 SG_ Transmission_Gear_Ratio_1 : 120|16@1+ (1,0) [0|65535] "" Vector__XXX
 SG_ Engine_Torque_Limit_1__Transmiss : 136|16@1+ (1,0) [0|65535] "" Vector__XXX
 SG_ Transmission_Gear_Ratio_2 : 152|16@1+ (1,0) [0|65535] "" Vector__XXX
 SG_ Engine_Torque_Limit_2__Transmiss : 168|16@1+ (1,0) [0|65535] "" Vector__XXX
 SG_ Transmission_Gear_Ratio_3 : 184|16@1+ (1,0) [0|65535] "" Vector__XXX
 SG_ Engine_Torque_Limit_3__Transmiss : 200|16@1+ (1,0) [0|65535] "" Vector__XXX
 SG_ Engine_Torque_Limit_4__Transmiss : 216|16@1+ (1,0) [0|65535] "" Vector__XXX
 SG_ Engine_Torque_Limit_5__Switch : 232|16@1+ (1,0) [0|65535] "" Vector__XXX
 SG_ Engine_Torque_Limit_6__Axle_Inpu : 248|16@1+ (1,0) [0|65535] "" Vector__XXX

BO_ 2164166912 FL: 8 Vector__XXX
 SG_ Engine_Fuel_Leakage_1 : 0|2@1+ (1,0) [0|3] "" Vector__XXX
 SG_ Engine_Fuel_Leakage_2 : 2|2@1+ (1,0) [0|3] "" Vector__XXX

BO_ 2164167168 EI: 8 Vector__XXX
 SG_ Engine_Pre_filter_Oil_Pressure : 0|8@1+ (1,0) [0|255] "" Vector__XXX
 SG_ Engine_Exhaust_Gas_Pressure : 8|16@1+ (1,0) [0|65535] "" Vector__XXX
 SG_ Engine_Fuel_Rack_Position : 24|8@1+ (1,0) [0|255] "" Vector__XXX
 SG_ Engine_Gas_Mass_Flow_Rate_1 : 32|16@1+ (1,0) [0|65535] "" Vector__XXX
 SG_ Instantaneous_Estimated_Brake_Po : 48|16@1+ (1,0) [0|65535] "" Vector__XXX

BO_ 2164167424 EES: 8 Vector__XXX
 SG_ Electrical_Load : 0|16@1+ (1,0) [0|65535] "" Vector__XXX
 SG_ Safety_Wire_Status : 16|2@1+ (1,0) [0|3] "" Vector__XXX

BO_ 2164167680 EAC: 8 Vector__XXX
 SG_ Engine_Auxiliary_Coolant_Pressur : 0|8@1+ (1,0) [0|255] "" Vector__XXX
 SG_ Engine_Auxiliary_Coolant_Tempera : 8|8@1+ (1,0) [0|255] "" Vector__XXX
 SG_ Sea_Water_Pump_Outlet_Pressure : 16|8@1+ (1,0) [0|255] "" Vector__XXX

BO_ 2164167936 RBI: 8 Vector__XXX
 SG_ Engine_Operation_Time_Since_Rebu : 0|32@1+ (1,0) [0|4294967295] "" Vector__XXX

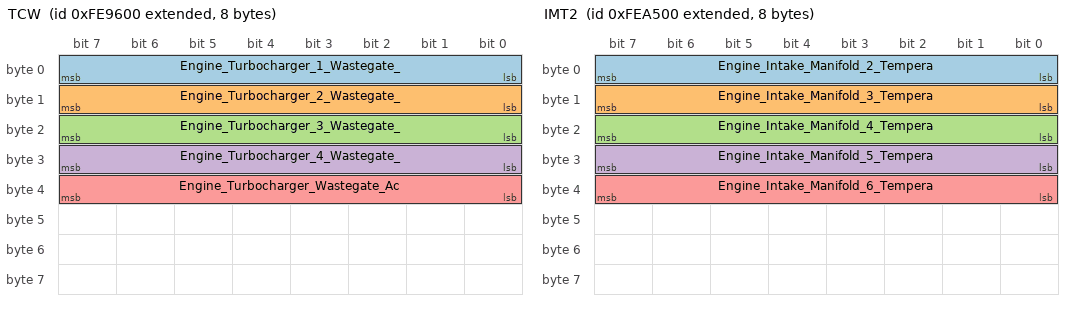
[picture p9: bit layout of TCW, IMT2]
BO_ 2164168192 TCW: 8 Vector__XXX
 SG_ Engine_Turbocharger_1_Wastegate_ : 0|8@1+ (1,0) [0|255] "" Vector__XXX
 SG_ Engine_Turbocharger_2_Wastegate_ : 8|8@1+ (1,0) [0|255] "" Vector__XXX
 SG_ Engine_Turbocharger_3_Wastegate_ : 16|8@1+ (1,0) [0|255] "" Vector__XXX
 SG_ Engine_Turbocharger_4_Wastegate_ : 24|8@1+ (1,0) [0|255] "" Vector__XXX
 SG_ Engine_Turbocharger_Wastegate_Ac : 32|8@1+ (1,0) [0|255] "" Vector__XXX

BO_ 2164168448 TCI5: 8 Vector__XXX
 SG_ Engine_Turbocharger_1_Turbine_Ou : 0|16@1+ (1,0) [0|65535] "" Vector__XXX
 SG_ Engine_Turbocharger_2_Turbine_Ou : 16|16@1+ (1,0) [0|65535] "" Vector__XXX
 SG_ Engine_Turbocharger_3_Turbine_Ou : 32|16@1+ (1,0) [0|65535] "" Vector__XXX
 SG_ Engine_Turbocharger_4_Turbine_Ou : 48|16@1+ (1,0) [0|65535] "" Vector__XXX

BO_ 2164168704 TCI4: 8 Vector__XXX
 SG_ Engine_Turbocharger_1_Turbine_In : 0|16@1+ (1,0) [0|65535] "" Vector__XXX
 SG_ Engine_Turbocharger_2_Turbine_In : 16|16@1+ (1,0) [0|65535] "" Vector__XXX
 SG_ Engine_Turbocharger_3_Turbine_In : 32|16@1+ (1,0) [0|65535] "" Vector__XXX
 SG_ Engine_Turbocharger_4_Turbine_In : 48|16@1+ (1,0) [0|65535] "" Vector__XXX

BO_ 2164168960 TCI3: 8 Vector__XXX
 SG_ Engine_Turbocharger_1_Compressor : 0|16@1+ (1,0) [0|65535] "" Vector__XXX
 SG_ Engine_Turbocharger_2_Compressor : 16|16@1+ (1,0) [0|65535] "" Vector__XXX
 SG_ Engine_Turbocharger_3_Compressor : 32|16@1+ (1,0) [0|65535] "" Vector__XXX
 SG_ Engine_Turbocharger_4_Compressor : 48|16@1+ (1,0) [0|65535] "" Vector__XXX

BO_ 2164169216 TCI2: 8 Vector__XXX
 SG_ Engine_Turbocharger_1_Compressor : 0|16@1+ (1,0) [0|65535] "" Vector__XXX
 SG_ Engine_Turbocharger_2_Compressor : 16|16@1+ (1,0) [0|65535] "" Vector__XXX
 SG_ Engine_Turbocharger_3_Compressor : 32|16@1+ (1,0) [0|65535] "" Vector__XXX
 SG_ Engine_Turbocharger_4_Compressor : 48|16@1+ (1,0) [0|65535] "" Vector__XXX

BO_ 2164169472 TCI1: 8 Vector__XXX
 SG_ Engine_Turbocharger_Lube_Oil_Pre : 0|8@1+ (1,0) [0|255] "" Vector__XXX
 SG_ Engine_Turbocharger_2_Speed : 8|16@1+ (1,0) [0|65535] "" Vector__XXX
 SG_ Engine_Turbocharger_3_Speed : 24|16@1+ (1,0) [0|65535] "" Vector__XXX
 SG_ Engine_Turbocharger_4_Speed : 40|16@1+ (1,0) [0|65535] "" Vector__XXX

BO_ 2164169728 MBT3: 8 Vector__XXX
 SG_ Engine_Main_Bearing_9_Temperatur : 0|16@1+ (1,0) [0|65535] "" Vector__XXX
 SG_ Engine_Main_Bearing_10_Temperatu : 16|16@1+ (1,0) [0|65535] "" Vector__XXX
 SG_ Engine_Main_Bearing_11_Temperatu : 32|16@1+ (1,0) [0|65535] "" Vector__XXX

BO_ 2164169984 MBT2: 8 Vector__XXX
 SG_ Engine_Main_Bearing_5_Temperatur : 0|16@1+ (1,0) [0|65535] "" Vector__XXX
 SG_ Engine_Main_Bearing_6_Temperatur : 16|16@1+ (1,0) [0|65535] "" Vector__XXX
 SG_ Engine_Main_Bearing_7_Temperatur : 32|16@1+ (1,0) [0|65535] "" Vector__XXX
 SG_ Engine_Main_Bearing_8_Temperatur : 48|16@1+ (1,0) [0|65535] "" Vector__XXX

BO_ 2164170240 MBT1: 8 Vector__XXX
 SG_ Engine_Main_Bearing_1_Temperatur : 0|16@1+ (1,0) [0|65535] "" Vector__XXX
 SG_ Engine_Main_Bearing_2_Temperatur : 16|16@1+ (1,0) [0|65535] "" Vector__XXX
 SG_ Engine_Main_Bearing_3_Temperatur : 32|16@1+ (1,0) [0|65535] "" Vector__XXX
 SG_ Engine_Main_Bearing_4_Temperatur : 48|16@1+ (1,0) [0|65535] "" Vector__XXX

BO_ 2164170496 EPT5: 8 Vector__XXX
 SG_ Engine_Exhaust_Gas_Port_17_Tempe : 0|16@1+ (1,0) [0|65535] "" Vector__XXX
 SG_ Engine_Exhaust_Gas_Port_18_Tempe : 16|16@1+ (1,0) [0|65535] "" Vector__XXX
 SG_ Engine_Exhaust_Gas_Port_19_Tempe : 32|16@1+ (1,0) [0|65535] "" Vector__XXX
 SG_ Engine_Exhaust_Gas_Port_20_Tempe : 48|16@1+ (1,0) [0|65535] "" Vector__XXX

BO_ 2164170752 EPT4: 8 Vector__XXX
 SG_ Engine_Exhaust_Gas_Port_13_Tempe : 0|16@1+ (1,0) [0|65535] "" Vector__XXX
 SG_ Engine_Exhaust_Gas_Port_14_Tempe : 16|16@1+ (1,0) [0|65535] "" Vector__XXX
 SG_ Engine_Exhaust_Gas_Port_15_Tempe : 32|16@1+ (1,0) [0|65535] "" Vector__XXX
 SG_ Engine_Exhaust_Gas_Port_16_Tempe : 48|16@1+ (1,0) [0|65535] "" Vector__XXX

BO_ 2164171008 EPT3: 8 Vector__XXX
 SG_ Engine_Exhaust_Gas_Port_9_Temper : 0|16@1+ (1,0) [0|65535] "" Vector__XXX
 SG_ Engine_Exhaust_Gas_Port_10_Tempe : 16|16@1+ (1,0) [0|65535] "" Vector__XXX
 SG_ Engine_Exhaust_Gas_Port_11_Tempe : 32|16@1+ (1,0) [0|65535] "" Vector__XXX
 SG_ Engine_Exhaust_Gas_Port_12_Tempe : 48|16@1+ (1,0) [0|65535] "" Vector__XXX

BO_ 2164171264 EPT2: 8 Vector__XXX
 SG_ Engine_Exhaust_Gas_Port_5_Temper : 0|16@1+ (1,0) [0|65535] "" Vector__XXX
 SG_ Engine_Exhaust_Gas_Port_6_Temper : 16|16@1+ (1,0) [0|65535] "" Vector__XXX
 SG_ Engine_Exhaust_Gas_Port_7_Temper : 32|16@1+ (1,0) [0|65535] "" Vector__XXX
 SG_ Engine_Exhaust_Gas_Port_8_Temper : 48|16@1+ (1,0) [0|65535] "" Vector__XXX

BO_ 2164171520 EPT1: 8 Vector__XXX
 SG_ Engine_Exhaust_Gas_Port_1_Temper : 0|16@1+ (1,0) [0|65535] "" Vector__XXX
 SG_ Engine_Exhaust_Gas_Port_2_Temper : 16|16@1+ (1,0) [0|65535] "" Vector__XXX
 SG_ Engine_Exhaust_Gas_Port_3_Temper : 32|16@1+ (1,0) [0|65535] "" Vector__XXX
 SG_ Engine_Exhaust_Gas_Port_4_Temper : 48|16@1+ (1,0) [0|65535] "" Vector__XXX

BO_ 2164171776 ET2: 8 Vector__XXX
 SG_ Engine_Oil_Temperature_2 : 0|16@1+ (1,0) [0|65535] "" Vector__XXX
 SG_ Engine_ECU_Temperature : 16|16@1+ (1,0) [0|65535] "" Vector__XXX
 SG_ Engine_Exhaust_Gas_Recirculation0 : 32|16@1+ (1,0) [0|65535] "" Vector__XXX
 SG_ Engine_Exhaust_Gas_Recirculation1 : 48|16@1+ (1,0) [0|65535] "" Vector__XXX

BO_ 2164172032 IMT2: 8 Vector__XXX
 SG_ Engine_Intake_Manifold_2_Tempera : 0|8@1+ (1,0) [0|255] "" Vector__XXX
 SG_ Engine_Intake_Manifold_3_Tempera : 8|8@1+ (1,0) [0|255] "" Vector__XXX
 SG_ Engine_Intake_Manifold_4_Tempera : 16|8@1+ (1,0) [0|255] "" Vector__XXX
 SG_ Engine_Intake_Manifold_5_Tempera : 24|8@1+ (1,0) [0|255] "" Vector__XXX
 SG_ Engine_Intake_Manifold_6_Tempera : 32|8@1+ (1,0) [0|255] "" Vector__XXX

BO_ 2164172288 IMT1: 8 Vector__XXX
 SG_ Engine_Turbocharger_1_Boost_Pres : 0|16@1+ (1,0) [0|65535] "" Vector__XXX
 SG_ Engine_Turbocharger_2_Boost_Pres : 16|16@1+ (1,0) [0|65535] "" Vector__XXX
 SG_ Engine_Turbocharger_3_Boost_Pres : 32|16@1+ (1,0) [0|65535] "" Vector__XXX
 SG_ Engine_Turbocharger_4_Boost_Pres : 48|16@1+ (1,0) [0|65535] "" Vector__XXX

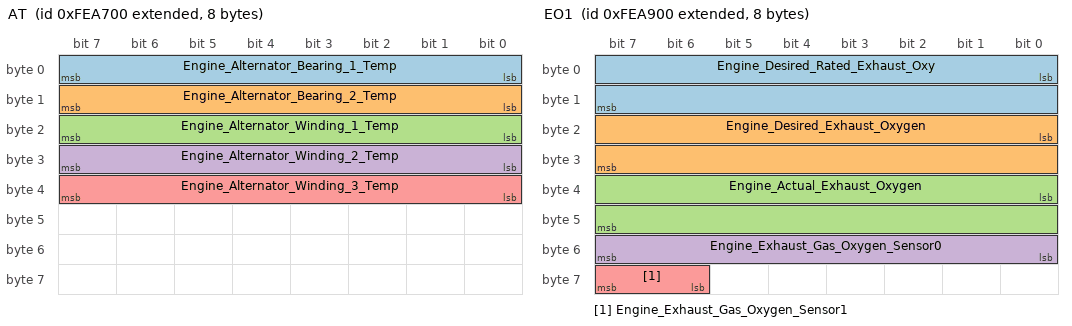
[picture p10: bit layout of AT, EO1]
BO_ 2164172544 AT: 8 Vector__XXX
 SG_ Engine_Alternator_Bearing_1_Temp : 0|8@1+ (1,0) [0|255] "" Vector__XXX
 SG_ Engine_Alternator_Bearing_2_Temp : 8|8@1+ (1,0) [0|255] "" Vector__XXX
 SG_ Engine_Alternator_Winding_1_Temp : 16|8@1+ (1,0) [0|255] "" Vector__XXX
 SG_ Engine_Alternator_Winding_2_Temp : 24|8@1+ (1,0) [0|255] "" Vector__XXX
 SG_ Engine_Alternator_Winding_3_Temp : 32|8@1+ (1,0) [0|255] "" Vector__XXX

BO_ 2164172800 AC: 8 Vector__XXX
 SG_ Articulation_Angle : 0|8@1+ (1,0) [0|255] "" Vector__XXX

BO_ 2164173056 EO1: 8 Vector__XXX
 SG_ Engine_Desired_Rated_Exhaust_Oxy : 0|16@1+ (1,0) [0|65535] "" Vector__XXX
 SG_ Engine_Desired_Exhaust_Oxygen : 16|16@1+ (1,0) [0|65535] "" Vector__XXX
 SG_ Engine_Actual_Exhaust_Oxygen : 32|16@1+ (1,0) [0|65535] "" Vector__XXX
 SG_ Engine_Exhaust_Gas_Oxygen_Sensor0 : 48|8@1+ (1,0) [0|255] "" Vector__XXX
 SG_ Engine_Exhaust_Gas_Oxygen_Sensor1 : 62|2@1+ (1,0) [0|3] "" Vector__XXX

BO_ 2164173312 AF2: 8 Vector__XXX
 SG_ Engine_Gaseous_Fuel_Correction_F : 0|8@1+ (1,0) [0|255] "" Vector__XXX
 SG_ Engine_Desired_Absolute_Intake_M : 8|16@1+ (1,0) [0|65535] "" Vector__XXX
 SG_ Engine_Turbocharger_Wastegate_Va : 24|8@1+ (1,0) [0|255] "" Vector__XXX
 SG_ Engine_Gas_Mass_Flow_Sensor_Fuel : 32|8@1+ (1,0) [0|255] "" Vector__XXX

BO_ 2164173568 ETC6: 8 Vector__XXX
 SG_ Recommended_Gear : 0|8@1+ (1,0) [0|255] "" Vector__XXX
 SG_ Highest_Possible_Gear : 8|8@1+ (1,0) [0|255] "" Vector__XXX
 SG_ Lowest_Possible_Gear : 16|8@1+ (1,0) [0|255] "" Vector__XXX
 SG_ Clutch_Life_Remaining : 24|8@1+ (1,0) [0|255] "" Vector__XXX

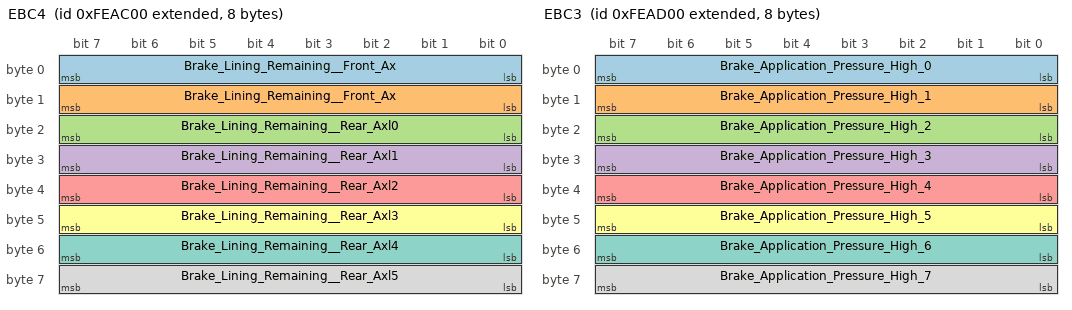
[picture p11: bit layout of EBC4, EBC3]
BO_ 2164173824 EBC4: 8 Vector__XXX
 SG_ Brake_Lining_Remaining__Front_Ax : 0|8@1+ (1,0) [0|255] "" Vector__XXX
 SG_ Brake_Lining_Remaining__Front_Ax : 8|8@1+ (1,0) [0|255] "" Vector__XXX
 SG_ Brake_Lining_Remaining__Rear_Axl0 : 16|8@1+ (1,0) [0|255] "" Vector__XXX
 SG_ Brake_Lining_Remaining__Rear_Axl1 : 24|8@1+ (1,0) [0|255] "" Vector__XXX
 SG_ Brake_Lining_Remaining__Rear_Axl2 : 32|8@1+ (1,0) [0|255] "" Vector__XXX
 SG_ Brake_Lining_Remaining__Rear_Axl3 : 40|8@1+ (1,0) [0|255] "" Vector__XXX
 SG_ Brake_Lining_Remaining__Rear_Axl4 : 48|8@1+ (1,0) [0|255] "" Vector__XXX
 SG_ Brake_Lining_Remaining__Rear_Axl5 : 56|8@1+ (1,0) [0|255] "" Vector__XXX

BO_ 2164174080 EBC3: 8 Vector__XXX
 SG_ Brake_Application_Pressure_High_0 : 0|8@1+ (1,0) [0|255] "" Vector__XXX
 SG_ Brake_Application_Pressure_High_1 : 8|8@1+ (1,0) [0|255] "" Vector__XXX
 SG_ Brake_Application_Pressure_High_2 : 16|8@1+ (1,0) [0|255] "" Vector__XXX
 SG_ Brake_Application_Pressure_High_3 : 24|8@1+ (1,0) [0|255] "" Vector__XXX
 SG_ Brake_Application_Pressure_High_4 : 32|8@1+ (1,0) [0|255] "" Vector__XXX
 SG_ Brake_Application_Pressure_High_5 : 40|8@1+ (1,0) [0|255] "" Vector__XXX
 SG_ Brake_Application_Pressure_High_6 : 48|8@1+ (1,0) [0|255] "" Vector__XXX
 SG_ Brake_Application_Pressure_High_7 : 56|8@1+ (1,0) [0|255] "" Vector__XXX

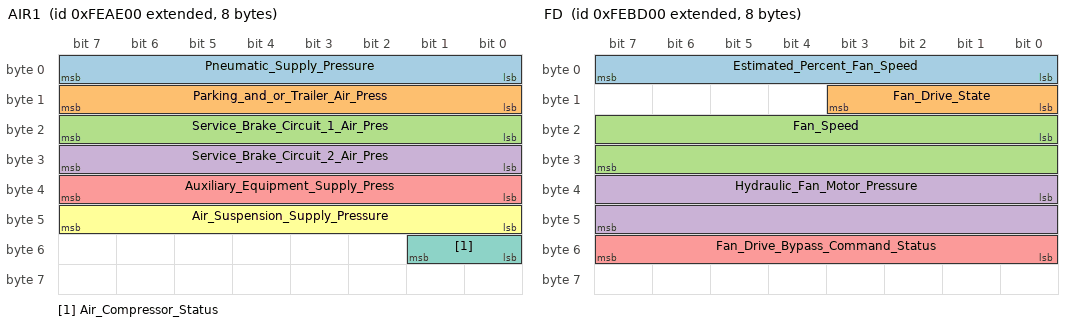
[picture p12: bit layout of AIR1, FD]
BO_ 2164174336 AIR1: 8 Vector__XXX
 SG_ Pneumatic_Supply_Pressure : 0|8@1+ (1,0) [0|255] "" Vector__XXX
 SG_ Parking_and_or_Trailer_Air_Press : 8|8@1+ (1,0) [0|255] "" Vector__XXX
 SG_ Service_Brake_Circuit_1_Air_Pres : 16|8@1+ (1,0) [0|255] "" Vector__XXX
 SG_ Service_Brake_Circuit_2_Air_Pres : 24|8@1+ (1,0) [0|255] "" Vector__XXX
 SG_ Auxiliary_Equipment_Supply_Press : 32|8@1+ (1,0) [0|255] "" Vector__XXX
 SG_ Air_Suspension_Supply_Pressure : 40|8@1+ (1,0) [0|255] "" Vector__XXX
 SG_ Air_Compressor_Status : 48|2@1+ (1,0) [0|3] "" Vector__XXX

BO_ 2164174592 GFC: 8 Vector__XXX
 SG_ Trip_Fuel__Gaseous_ : 0|32@1+ (1,0) [0|4294967295] "" Vector__XXX
 SG_ Total_Fuel_Used__Gaseous_ : 32|32@1+ (1,0) [0|4294967295] "" Vector__XXX

BO_ 2164174848 TTI2: 20 Vector__XXX
 SG_ Trip_Cruise_Time : 0|32@1+ (1,0) [0|4294967295] "" Vector__XXX
 SG_ Trip_PTO_Governor_Time : 32|32@1+ (1,0) [0|4294967295] "" Vector__XXX
 SG_ Trip_Engine_Running_Time : 64|32@1+ (1,0) [0|4294967295] "" Vector__XXX
 SG_ Trip_Idle_Time : 96|32@1+ (1,0) [0|4294967295] "" Vector__XXX
 SG_ Trip_Air_Compressor_On_Time : 128|32@1+ (1,0) [0|4294967295] "" Vector__XXX

BO_ 2164175104 EH: 8 Vector__XXX
 SG_ Total_ECU_Distance : 0|32@1+ (1,0) [0|4294967295] "" Vector__XXX
 SG_ Total_ECU_Run_Time : 32|32@1+ (1,0) [0|4294967295] "" Vector__XXX

BO_ 2164175360 GFI1: 8 Vector__XXX
 SG_ Total_Engine_PTO_Governor_Fuel_U : 0|32@1+ (1,0) [0|4294967295] "" Vector__XXX
 SG_ Trip_Average_Fuel_Rate__Gaseous_ : 32|16@1+ (1,0) [0|65535] "" Vector__XXX
 SG_ Engine_Fuel_Specific_Gravity : 48|16@1+ (1,0) [0|65535] "" Vector__XXX

BO_ 2164175616 LFI: 8 Vector__XXX
 SG_ Total_Engine_PTO_Governor_Fuel_U : 0|32@1+ (1,0) [0|4294967295] "" Vector__XXX
 SG_ Trip_Average_Fuel_Rate : 32|16@1+ (1,0) [0|65535] "" Vector__XXX

BO_ 2164175872 TTI1: 16 Vector__XXX
 SG_ Trip_Time_in_VSL : 0|32@1+ (1,0) [0|4294967295] "" Vector__XXX
 SG_ Trip_Time_in_Top_Gear : 32|32@1+ (1,0) [0|4294967295] "" Vector__XXX
 SG_ Trip_Time_in_Gear_Down : 64|32@1+ (1,0) [0|4294967295] "" Vector__XXX
 SG_ Trip_Time_in_Derate_by_Engine : 96|32@1+ (1,0) [0|4294967295] "" Vector__XXX

BO_ 2164176128 TSI: 8 Vector__XXX
 SG_ Trip_Number_of_Hot_Shutdowns : 0|16@1+ (1,0) [0|65535] "" Vector__XXX
 SG_ Trip_Number_of_Idle_Shutdowns : 16|16@1+ (1,0) [0|65535] "" Vector__XXX
 SG_ Trip_Number_of_Idle_Shutdown_Ove : 32|16@1+ (1,0) [0|65535] "" Vector__XXX
 SG_ Trip_Sudden_Decelerations : 48|16@1+ (1,0) [0|65535] "" Vector__XXX

BO_ 2164176384 TVI: 8 Vector__XXX
 SG_ Trip_Maximum_Vehicle_Speed : 0|16@1+ (1,0) [0|65535] "" Vector__XXX
 SG_ Trip_Cruise_Distance : 16|32@1+ (1,0) [0|4294967295] "" Vector__XXX

BO_ 2164176640 LF: 10 Vector__XXX
 SG_ Trip_Maximum_Engine_Speed : 0|16@1+ (1,0) [0|65535] "" Vector__XXX
 SG_ Trip_Average_Engine_Speed : 16|16@1+ (1,0) [0|65535] "" Vector__XXX
 SG_ Trip_Drive_Average_Load_Factor : 32|8@1+ (1,0) [0|255] "" Vector__XXX
 SG_ Total_Drive_Average_Load_Factor : 40|8@1+ (1,0) [0|255] "" Vector__XXX
 SG_ Total_Engine_Cruise_Time : 48|32@1+ (1,0) [0|4294967295] "" Vector__XXX

BO_ 2164176896 GTFI: 22 Vector__XXX
 SG_ Trip_Drive_Fuel_Used__Gaseous_ : 0|32@1+ (1,0) [0|4294967295] "" Vector__XXX
 SG_ Trip_PTO_Governor_Moving_Fuel_Us : 32|32@1+ (1,0) [0|4294967295] "" Vector__XXX
 SG_ Trip_PTO_Governor_Non_moving_Fue : 64|32@1+ (1,0) [0|4294967295] "" Vector__XXX
 SG_ Trip_Vehicle_Idle_Fuel_Used__Gas : 96|32@1+ (1,0) [0|4294967295] "" Vector__XXX
 SG_ Trip_Cruise_Fuel_Used__Gaseous_ : 128|32@1+ (1,0) [0|4294967295] "" Vector__XXX
 SG_ Trip_Drive_Fuel_Economy__Gaseous : 160|16@1+ (1,0) [0|65535] "" Vector__XXX

BO_ 2164177152 LTFI: 22 Vector__XXX
 SG_ Trip_Drive_Fuel_Used : 0|32@1+ (1,0) [0|4294967295] "" Vector__XXX
 SG_ Trip_PTO_Governor_Moving_Fuel_Us : 32|32@1+ (1,0) [0|4294967295] "" Vector__XXX
 SG_ Trip_PTO_Governor_Non_moving_Fue : 64|32@1+ (1,0) [0|4294967295] "" Vector__XXX
 SG_ Trip_Vehicle_Idle_Fuel_Used : 96|32@1+ (1,0) [0|4294967295] "" Vector__XXX
 SG_ Trip_Cruise_Fuel_Used : 128|32@1+ (1,0) [0|4294967295] "" Vector__XXX
 SG_ Trip_Drive_Fuel_Economy : 160|16@1+ (1,0) [0|65535] "" Vector__XXX

BO_ 2164177408 TDI: 12 Vector__XXX
 SG_ Trip_Distance_on_VSL : 0|32@1+ (1,0) [0|4294967295] "" Vector__XXX
 SG_ Trip_Gear_Down_Distance : 32|32@1+ (1,0) [0|4294967295] "" Vector__XXX
 SG_ Trip_Distance_in_Top_Gear : 64|32@1+ (1,0) [0|4294967295] "" Vector__XXX

BO_ 2164177664 TFI: 16 Vector__XXX
 SG_ Trip_Fan_On_Time : 0|32@1+ (1,0) [0|4294967295] "" Vector__XXX
 SG_ Trip_Fan_On_Time_Due_to_the_Engi : 32|32@1+ (1,0) [0|4294967295] "" Vector__XXX
 SG_ Trip_Fan_On_Time_Due_to_a_Manual : 64|32@1+ (1,0) [0|4294967295] "" Vector__XXX
 SG_ Trip_Fan_On_Time_Due_to_the_A_C_ : 96|32@1+ (1,0) [0|4294967295] "" Vector__XXX

BO_ 2164177920 CBI: 16 Vector__XXX
 SG_ Total_Compression_Brake_Distance : 0|32@1+ (1,0) [0|4294967295] "" Vector__XXX
 SG_ Trip_Compression_Brake_Distance : 32|32@1+ (1,0) [0|4294967295] "" Vector__XXX
 SG_ Trip_Service_Brake_Distance : 64|32@1+ (1,0) [0|4294967295] "" Vector__XXX
 SG_ Trip_Service_Brake_Applications : 96|32@1+ (1,0) [0|4294967295] "" Vector__XXX

BO_ 2164178176 FD: 8 Vector__XXX
 SG_ Estimated_Percent_Fan_Speed : 0|8@1+ (1,0) [0|255] "" Vector__XXX
 SG_ Fan_Drive_State : 8|4@1+ (1,0) [0|15] "" Vector__XXX
 SG_ Fan_Speed : 16|16@1+ (1,0) [0|65535] "" Vector__XXX
 SG_ Hydraulic_Fan_Motor_Pressure : 32|16@1+ (1,0) [0|65535] "" Vector__XXX
 SG_ Fan_Drive_Bypass_Command_Status : 48|8@1+ (1,0) [0|255] "" Vector__XXX

BO_ 2164178432 EEC4: 8 Vector__XXX
 SG_ Engine_Rated_Power : 0|16@1+ (1,0) [0|65535] "" Vector__XXX
 SG_ Engine_Rated_Speed : 16|16@1+ (1,0) [0|65535] "" Vector__XXX
 SG_ Engine_Rotation_Direction : 32|2@1+ (1,0) [0|3] "" Vector__XXX
 SG_ Crank_Attempt_Count_on_Present_S : 40|8@1+ (1,0) [0|255] "" Vector__XXX

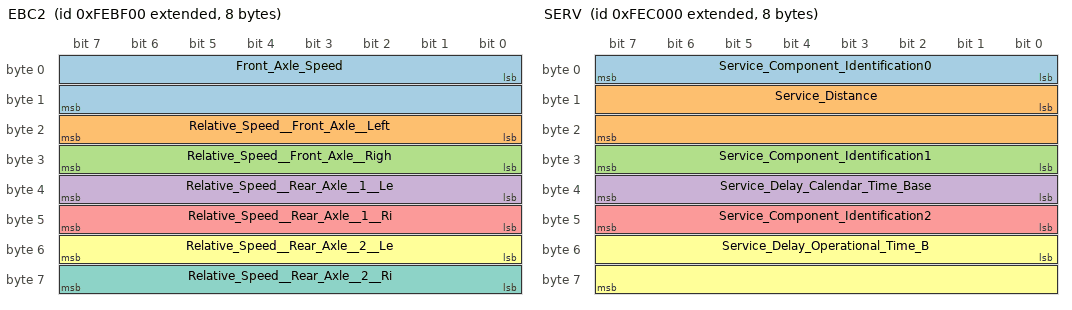
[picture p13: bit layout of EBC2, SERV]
BO_ 2164178688 EBC2: 8 Vector__XXX
 SG_ Front_Axle_Speed : 0|16@1+ (1,0) [0|65535] "" Vector__XXX
 SG_ Relative_Speed__Front_Axle__Left : 16|8@1+ (1,0) [0|255] "" Vector__XXX
 SG_ Relative_Speed__Front_Axle__Righ : 24|8@1+ (1,0) [0|255] "" Vector__XXX
 SG_ Relative_Speed__Rear_Axle__1__Le : 32|8@1+ (1,0) [0|255] "" Vector__XXX
 SG_ Relative_Speed__Rear_Axle__1__Ri : 40|8@1+ (1,0) [0|255] "" Vector__XXX
 SG_ Relative_Speed__Rear_Axle__2__Le : 48|8@1+ (1,0) [0|255] "" Vector__XXX
 SG_ Relative_Speed__Rear_Axle__2__Ri : 56|8@1+ (1,0) [0|255] "" Vector__XXX

BO_ 2164178944 SERV: 8 Vector__XXX
 SG_ Service_Component_Identification0 : 0|8@1+ (1,0) [0|255] "" Vector__XXX
 SG_ Service_Distance : 8|16@1+ (1,0) [0|65535] "" Vector__XXX
 SG_ Service_Component_Identification1 : 24|8@1+ (1,0) [0|255] "" Vector__XXX
 SG_ Service_Delay_Calendar_Time_Base : 32|8@1+ (1,0) [0|255] "" Vector__XXX
 SG_ Service_Component_Identification2 : 40|8@1+ (1,0) [0|255] "" Vector__XXX
 SG_ Service_Delay_Operational_Time_B : 48|16@1+ (1,0) [0|65535] "" Vector__XXX

BO_ 2164179200 VDHR: 8 Vector__XXX
 SG_ High_Resolution_Total_Vehicle_Di : 0|32@1+ (1,0) [0|4294967295] "" Vector__XXX
 SG_ High_Resolution_Trip_Distance : 32|32@1+ (1,0) [0|4294967295] "" Vector__XXX

BO_ 2164179456 ERC2: 8 Vector__XXX
 SG_ Transmission_Output_Retarder : 0|2@1+ (1,0) [0|3] "" Vector__XXX

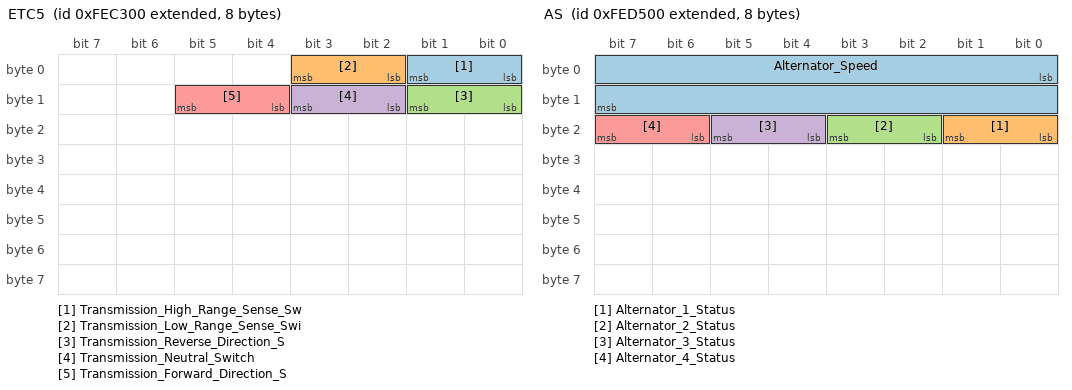
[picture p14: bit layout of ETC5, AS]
BO_ 2164179712 ETC5: 8 Vector__XXX
 SG_ Transmission_High_Range_Sense_Sw : 0|2@1+ (1,0) [0|3] "" Vector__XXX
 SG_ Transmission_Low_Range_Sense_Swi : 2|2@1+ (1,0) [0|3] "" Vector__XXX
 SG_ Transmission_Reverse_Direction_S : 8|2@1+ (1,0) [0|3] "" Vector__XXX
 SG_ Transmission_Neutral_Switch : 10|2@1+ (1,0) [0|3] "" Vector__XXX
 SG_ Transmission_Forward_Direction_S : 12|2@1+ (1,0) [0|3] "" Vector__XXX

BO_ 2164180224 ETC4: 8 Vector__XXX
 SG_ Transmission_Synchronizer_Clutch : 0|8@1+ (1,0) [0|255] "" Vector__XXX
 SG_ Transmission_Synchronizer_Brake_ : 8|8@1+ (1,0) [0|255] "" Vector__XXX

BO_ 2164180736 ETC3: 8 Vector__XXX
 SG_ Transmission_Shift_Finger_Gear_P : 0|8@1+ (1,0) [0|255] "" Vector__XXX
 SG_ Transmission_Shift_Finger_Rail_P : 8|8@1+ (1,0) [0|255] "" Vector__XXX
 SG_ Transmission_Shift_Finger_Neutra : 16|2@1+ (1,0) [0|3] "" Vector__XXX
 SG_ Transmission_Shift_Finger_Engage : 18|2@1+ (1,0) [0|3] "" Vector__XXX
 SG_ Transmission_Shift_Finger_Center : 20|2@1+ (1,0) [0|3] "" Vector__XXX
 SG_ Transmission_Shift_Finger_Rail_A0 : 24|2@1+ (1,0) [0|3] "" Vector__XXX
 SG_ Transmission_Shift_Finger_Gear_A0 : 26|2@1+ (1,0) [0|3] "" Vector__XXX
 SG_ Transmission_Shift_Finger_Rail_A1 : 28|2@1+ (1,0) [0|3] "" Vector__XXX
 SG_ Transmission_Shift_Finger_Gear_A1 : 30|2@1+ (1,0) [0|3] "" Vector__XXX
 SG_ Transmission_Range_High_Actuator : 32|2@1+ (1,0) [0|3] "" Vector__XXX
 SG_ Transmission_Range_Low_Actuator : 34|2@1+ (1,0) [0|3] "" Vector__XXX
 SG_ Transmission_Splitter_Direct_Act : 36|2@1+ (1,0) [0|3] "" Vector__XXX
 SG_ Transmission_Splitter_Indirect_A : 38|2@1+ (1,0) [0|3] "" Vector__XXX
 SG_ Transmission_Clutch_Actuator : 40|2@1+ (1,0) [0|3] "" Vector__XXX
 SG_ Transmission_Lockup_Clutch_Actua : 42|2@1+ (1,0) [0|3] "" Vector__XXX
 SG_ Transmission_Defuel_Actuator : 44|2@1+ (1,0) [0|3] "" Vector__XXX
 SG_ Transmission_Inertia_Brake_Actua : 46|2@1+ (1,0) [0|3] "" Vector__XXX

BO_ 2164184320 AS: 8 Vector__XXX
 SG_ Alternator_Speed : 0|16@1+ (1,0) [0|65535] "" Vector__XXX
 SG_ Alternator_1_Status : 16|2@1+ (1,0) [0|3] "" Vector__XXX
 SG_ Alternator_2_Status : 18|2@1+ (1,0) [0|3] "" Vector__XXX
 SG_ Alternator_3_Status : 20|2@1+ (1,0) [0|3] "" Vector__XXX
 SG_ Alternator_4_Status : 22|2@1+ (1,0) [0|3] "" Vector__XXX

BO_ 2164185344 AUXIO1: 8 Vector__XXX
 SG_ Auxiliary_I_O__04 : 0|2@1+ (1,0) [0|3] "" Vector__XXX
 SG_ Auxiliary_I_O__03 : 2|2@1+ (1,0) [0|3] "" Vector__XXX
 SG_ Auxiliary_I_O__02 : 4|2@1+ (1,0) [0|3] "" Vector__XXX
 SG_ Auxiliary_I_O__01 : 6|2@1+ (1,0) [0|3] "" Vector__XXX
 SG_ Auxiliary_I_O__08 : 8|2@1+ (1,0) [0|3] "" Vector__XXX
 SG_ Auxiliary_I_O__07 : 10|2@1+ (1,0) [0|3] "" Vector__XXX
 SG_ Auxiliary_I_O__06 : 12|2@1+ (1,0) [0|3] "" Vector__XXX
 SG_ Auxiliary_I_O__05 : 14|2@1+ (1,0) [0|3] "" Vector__XXX
 SG_ Auxiliary_I_O__12 : 16|2@1+ (1,0) [0|3] "" Vector__XXX
 SG_ Auxiliary_I_O__11 : 18|2@1+ (1,0) [0|3] "" Vector__XXX
 SG_ Auxiliary_I_O__10 : 20|2@1+ (1,0) [0|3] "" Vector__XXX
 SG_ Auxiliary_I_O__09 : 22|2@1+ (1,0) [0|3] "" Vector__XXX
 SG_ Auxiliary_I_O__16 : 24|2@1+ (1,0) [0|3] "" Vector__XXX
 SG_ Auxiliary_I_O__15 : 26|2@1+ (1,0) [0|3] "" Vector__XXX
 SG_ Auxiliary_I_O__14 : 28|2@1+ (1,0) [0|3] "" Vector__XXX
 SG_ Auxiliary_I_O__13 : 30|2@1+ (1,0) [0|3] "" Vector__XXX
 SG_ Auxiliary_I_O_Channel__1 : 32|16@1+ (1,0) [0|65535] "" Vector__XXX
 SG_ Auxiliary_I_O_Channel__2 : 48|16@1+ (1,0) [0|65535] "" Vector__XXX

BO_ 2164185600 SOFT: 8 Vector__XXX
 SG_ Number_of_Software_Identificatio : 0|8@1+ (1,0) [0|255] "" Vector__XXX
 SG_ Software_Identification : 8|1600@1+ (1,0) [0|4.446241647709404462001681407E+481] "" Vector__XXX

BO_ 2164185856 EFL_P2: 8 Vector__XXX
 SG_ Engine_Injection_Control_Pressur : 0|16@1+ (1,0) [0|65535] "" Vector__XXX
 SG_ Engine_Injector_Metering_Rail_1_ : 16|16@1+ (1,0) [0|65535] "" Vector__XXX
 SG_ Engine_Injector_Timing_Rail_1_Pr : 32|16@1+ (1,0) [0|65535] "" Vector__XXX
 SG_ Engine_Injector_Metering_Rail_2_ : 48|16@1+ (1,0) [0|65535] "" Vector__XXX

BO_ 2164186112 IO: 8 Vector__XXX
 SG_ Engine_Total_Idle_Fuel_Used : 0|32@1+ (1,0) [0|4294967295] "" Vector__XXX
 SG_ Engine_Total_Idle_Hours : 32|32@1+ (1,0) [0|4294967295] "" Vector__XXX

BO_ 2164186368 TC: 8 Vector__XXX
 SG_ Engine_Turbocharger_Lube_Oil_Pre : 0|8@1+ (1,0) [0|255] "" Vector__XXX
 SG_ Engine_Turbocharger_1_Speed : 8|16@1+ (1,0) [0|65535] "" Vector__XXX
 SG_ Engine_Turbocharger_Oil_Level_Sw : 30|2@1+ (1,0) [0|3] "" Vector__XXX

BO_ 2164186624 AIR2: 8 Vector__XXX
 SG_ Engine_Air_Start_Pressure : 0|8@1+ (1,0) [0|255] "" Vector__XXX

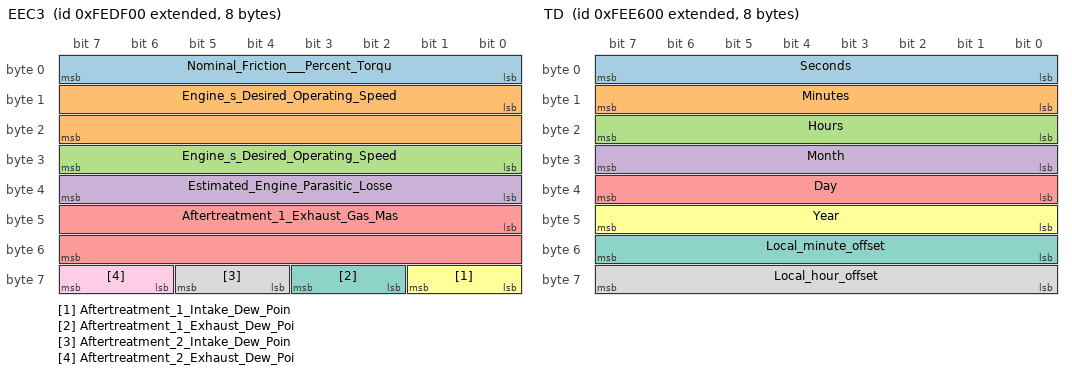
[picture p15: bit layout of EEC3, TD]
BO_ 2164186880 EEC3: 8 Vector__XXX
 SG_ Nominal_Friction___Percent_Torqu : 0|8@1+ (1,0) [0|255] "" Vector__XXX
 SG_ Engine_s_Desired_Operating_Speed : 8|16@1+ (1,0) [0|65535] "" Vector__XXX
 SG_ Engine_s_Desired_Operating_Speed : 24|8@1+ (1,0) [0|255] "" Vector__XXX
 SG_ Estimated_Engine_Parasitic_Losse : 32|8@1+ (1,0) [0|255] "" Vector__XXX
 SG_ Aftertreatment_1_Exhaust_Gas_Mas : 40|16@1+ (1,0) [0|65535] "" Vector__XXX
 SG_ Aftertreatment_1_Intake_Dew_Poin : 56|2@1+ (1,0) [0|3] "" Vector__XXX
 SG_ Aftertreatment_1_Exhaust_Dew_Poi : 58|2@1+ (1,0) [0|3] "" Vector__XXX
 SG_ Aftertreatment_2_Intake_Dew_Poin : 60|2@1+ (1,0) [0|3] "" Vector__XXX
 SG_ Aftertreatment_2_Exhaust_Dew_Poi : 62|2@1+ (1,0) [0|3] "" Vector__XXX

BO_ 2164187136 VD: 8 Vector__XXX
 SG_ Trip_Distance : 0|32@1+ (1,0) [0|4294967295] "" Vector__XXX
 SG_ Total_Vehicle_Distance : 32|32@1+ (1,0) [0|4294967295] "" Vector__XXX

BO_ 2164187392 RC: 19 Vector__XXX
 SG_ Retarder_Type : 0|4@1+ (1,0) [0|15] "" Vector__XXX
 SG_ Retarder_Location : 4|4@1+ (1,0) [0|15] "" Vector__XXX
 SG_ Retarder_Control_Method__Retarde : 8|8@1+ (1,0) [0|255] "" Vector__XXX
 SG_ Retarder_Speed_At_Idle__Point_1_ : 16|16@1+ (1,0) [0|65535] "" Vector__XXX
 SG_ Percent_Torque_At_Idle__Point_1_ : 32|8@1+ (1,0) [0|255] "" Vector__XXX
 SG_ Maximum_Retarder_Speed__Point_2_ : 40|16@1+ (1,0) [0|65535] "" Vector__XXX
 SG_ Percent_Torque_At_Maximum_Speed_ : 56|8@1+ (1,0) [0|255] "" Vector__XXX
 SG_ Retarder_Speed_At_Point_3__Retar : 64|16@1+ (1,0) [0|65535] "" Vector__XXX
 SG_ Percent_Torque_At_Point_3__Retar : 80|8@1+ (1,0) [0|255] "" Vector__XXX
 SG_ Retarder_Speed_At_Point_4__Retar : 88|16@1+ (1,0) [0|65535] "" Vector__XXX
 SG_ Percent_Torque_At_Point_4__Retar : 104|8@1+ (1,0) [0|255] "" Vector__XXX
 SG_ Retarder_Speed_At_Peak_Torque__P : 112|16@1+ (1,0) [0|65535] "" Vector__XXX
 SG_ Reference_Retarder_Torque__Retar : 128|16@1+ (1,0) [0|65535] "" Vector__XXX
 SG_ Percent_Torque_At_Peak_Torque__P : 144|8@1+ (1,0) [0|255] "" Vector__XXX

BO_ 2164187648 TCFG: 8 Vector__XXX
 SG_ Number_of_Reverse_Gear_Ratios : 0|8@1+ (1,0) [0|255] "" Vector__XXX
 SG_ Number_of_Forward_Gear_Ratios : 8|8@1+ (1,0) [0|255] "" Vector__XXX
 SG_ Transmission_Gear_Ratio : 16|16@1+ (1,0) [0|65535] "" Vector__XXX

BO_ 2164187904 EC1: 39 Vector__XXX
 SG_ Engine_Speed_At_Idle__Point_1__E : 0|16@1+ (1,0) [0|65535] "" Vector__XXX
 SG_ Engine_Percent_Torque_At_Idle__P : 16|8@1+ (1,0) [0|255] "" Vector__XXX
 SG_ Engine_Speed_At_Point_2__Engine_ : 24|16@1+ (1,0) [0|65535] "" Vector__XXX
 SG_ Engine_Percent_Torque_At_Point_2 : 40|8@1+ (1,0) [0|255] "" Vector__XXX
 SG_ Engine_Speed_At_Point_3__Engine_ : 48|16@1+ (1,0) [0|65535] "" Vector__XXX
 SG_ Engine_Percent_Torque_At_Point_3 : 64|8@1+ (1,0) [0|255] "" Vector__XXX
 SG_ Engine_Speed_At_Point_4__Engine_ : 72|16@1+ (1,0) [0|65535] "" Vector__XXX
 SG_ Engine_Percent_Torque_At_Point_4 : 88|8@1+ (1,0) [0|255] "" Vector__XXX
 SG_ Engine_Speed_At_Point_5__Engine_ : 96|16@1+ (1,0) [0|65535] "" Vector__XXX
 SG_ Engine_Percent_Torque_At_Point_5 : 112|8@1+ (1,0) [0|255] "" Vector__XXX
 SG_ Engine_Speed_At_High_Idle__Point : 120|16@1+ (1,0) [0|65535] "" Vector__XXX
 SG_ Engine_Gain__Kp__Of_The_Endspeed : 136|16@1+ (1,0) [0|65535] "" Vector__XXX
 SG_ Engine_Reference_Torque__Engine_ : 152|16@1+ (1,0) [0|65535] "" Vector__XXX
 SG_ Engine_Maximum_Momentary_Overrid0 : 168|16@1+ (1,0) [0|65535] "" Vector__XXX
 SG_ Engine_Maximum_Momentary_Overrid1 : 184|8@1+ (1,0) [0|255] "" Vector__XXX
 SG_ Engine_Requested_Speed_Control_R0 : 192|8@1+ (1,0) [0|255] "" Vector__XXX
 SG_ Engine_Requested_Speed_Control_R1 : 200|8@1+ (1,0) [0|255] "" Vector__XXX
 SG_ Engine_Requested_Torque_Control_0 : 208|8@1+ (1,0) [0|255] "" Vector__XXX
 SG_ Engine_Requested_Torque_Control_1 : 216|8@1+ (1,0) [0|255] "" Vector__XXX
 SG_ Engine_Extended_Range_Requested_ : 224|16@1+ (1,0) [0|65535] "" Vector__XXX
 SG_ Engine_Moment_of_Inertia : 240|16@1+ (1,0) [0|65535] "" Vector__XXX
 SG_ Engine_Default_Torque_Limit : 256|16@1+ (1,0) [0|65535] "" Vector__XXX
 SG_ Support_Variable_Rate_TSC1_Messa : 272|8@1+ (1,0) [0|255] "" Vector__XXX
 SG_ Support_TSC1_Control_Purpose_Gro0 : 280|8@1+ (1,0) [0|255] "" Vector__XXX
 SG_ Support_TSC1_Control_Purpose_Gro1 : 288|8@1+ (1,0) [0|255] "" Vector__XXX
 SG_ Support_TSC1_Control_Purpose_Gro2 : 296|8@1+ (1,0) [0|255] "" Vector__XXX
 SG_ Support_TSC1_Control_Purpose_Gro3 : 304|8@1+ (1,0) [0|255] "" Vector__XXX

BO_ 2164188160 SHUTDN: 8 Vector__XXX
 SG_ Engine_Idle_Shutdown_has_Shutdow : 0|2@1+ (1,0) [0|3] "" Vector__XXX
 SG_ Engine_Idle_Shutdown_Driver_Aler : 2|2@1+ (1,0) [0|3] "" Vector__XXX
 SG_ Engine_Idle_Shutdown_Timer_Overr : 4|2@1+ (1,0) [0|3] "" Vector__XXX
 SG_ Engine_Idle_Shutdown_Timer_State : 6|2@1+ (1,0) [0|3] "" Vector__XXX
 SG_ Engine_Idle_Shutdown_Timer_Funct : 14|2@1+ (1,0) [0|3] "" Vector__XXX
 SG_ A_C_High_Pressure_Fan_Switch : 16|2@1+ (1,0) [0|3] "" Vector__XXX
 SG_ Refrigerant_Low_Pressure_Switch : 18|2@1+ (1,0) [0|3] "" Vector__XXX
 SG_ Refrigerant_High_Pressure_Switch : 20|2@1+ (1,0) [0|3] "" Vector__XXX
 SG_ Engine_Wait_to_Start_Lamp : 24|2@1+ (1,0) [0|3] "" Vector__XXX
 SG_ Engine_Protection_System_has_Shu : 32|2@1+ (1,0) [0|3] "" Vector__XXX
 SG_ Engine_Protection_System_Approac : 34|2@1+ (1,0) [0|3] "" Vector__XXX
 SG_ Engine_Protection_System_Timer_O : 36|2@1+ (1,0) [0|3] "" Vector__XXX
 SG_ Engine_Protection_System_Timer_S : 38|2@1+ (1,0) [0|3] "" Vector__XXX
 SG_ Engine_Protection_System_Configu : 46|2@1+ (1,0) [0|3] "" Vector__XXX
 SG_ Engine_Alarm_Acknowledge : 48|2@1+ (1,0) [0|3] "" Vector__XXX
 SG_ Engine_Alarm_Output_Command_Stat : 50|2@1+ (1,0) [0|3] "" Vector__XXX
 SG_ Engine_Air_Shutoff_Command_Statu : 52|2@1+ (1,0) [0|3] "" Vector__XXX
 SG_ Engine_Overspeed_Test : 54|2@1+ (1,0) [0|3] "" Vector__XXX
 SG_ Engine_Air_Shutoff_Status : 56|2@1+ (1,0) [0|3] "" Vector__XXX

BO_ 2164188416 HOURS: 8 Vector__XXX
 SG_ Engine_Total_Hours_of_Operation : 0|32@1+ (1,0) [0|4294967295] "" Vector__XXX
 SG_ Engine_Total_Revolutions : 32|32@1+ (1,0) [0|4294967295] "" Vector__XXX

BO_ 2164188672 TD: 8 Vector__XXX
 SG_ Seconds : 0|8@1+ (1,0) [0|255] "" Vector__XXX
 SG_ Minutes : 8|8@1+ (1,0) [0|255] "" Vector__XXX
 SG_ Hours : 16|8@1+ (1,0) [0|255] "" Vector__XXX
 SG_ Month : 24|8@1+ (1,0) [0|255] "" Vector__XXX
 SG_ Day : 32|8@1+ (1,0) [0|255] "" Vector__XXX
 SG_ Year : 40|8@1+ (1,0) [0|255] "" Vector__XXX
 SG_ Local_minute_offset : 48|8@1+ (1,0) [0|255] "" Vector__XXX
 SG_ Local_hour_offset : 56|8@1+ (1,0) [0|255] "" Vector__XXX

BO_ 2164188928 VH: 8 Vector__XXX
 SG_ Total_Vehicle_Hours : 0|32@1+ (1,0) [0|4294967295] "" Vector__XXX
 SG_ Total_Power_Takeoff_Hours : 32|32@1+ (1,0) [0|4294967295] "" Vector__XXX

BO_ 2164189184 VDS: 8 Vector__XXX
 SG_ Compass_Bearing : 0|16@1+ (1,0) [0|65535] "" Vector__XXX
 SG_ Navigation_Based_Vehicle_Speed : 16|16@1+ (1,0) [0|65535] "" Vector__XXX
 SG_ Pitch : 32|16@1+ (1,0) [0|65535] "" Vector__XXX
 SG_ Altitude : 48|16@1+ (1,0) [0|65535] "" Vector__XXX

BO_ 2164189440 LFC: 8 Vector__XXX
 SG_ Engine_Trip_Fuel : 0|32@1+ (1,0) [0|4294967295] "" Vector__XXX
 SG_ Engine_Total_Fuel_Used : 32|32@1+ (1,0) [0|4294967295] "" Vector__XXX

BO_ 2164189696 VW: 8 Vector__XXX
 SG_ Axle_Location : 0|8@1+ (1,0) [0|255] "" Vector__XXX
 SG_ Axle_Weight : 8|16@1+ (1,0) [0|65535] "" Vector__XXX
 SG_ Trailer_Weight : 24|16@1+ (1,0) [0|65535] "" Vector__XXX
 SG_ Cargo_Weight : 40|16@1+ (1,0) [0|65535] "" Vector__XXX

BO_ 2164189952 CI: 8 Vector__XXX
 SG_ Make : 0|40@1+ (1,0) [0|1099511627775] "" Vector__XXX
 SG_ Model : 0|1600@1+ (1,0) [0|4.446241647709404462001681407E+481] "" Vector__XXX
 SG_ Serial_Number : 0|1600@1+ (1,0) [0|4.446241647709404462001681407E+481] "" Vector__XXX
 SG_ Unit_Number__Power_Unit_ : 0|1600@1+ (1,0) [0|4.446241647709404462001681407E+481] "" Vector__XXX

BO_ 2164190208 VI: 8 Vector__XXX
 SG_ Vehicle_Identification_Number : 0|1600@1+ (1,0) [0|4.446241647709404462001681407E+481] "" Vector__XXX

BO_ 2164190464 CCSS: 8 Vector__XXX
 SG_ Maximum_Vehicle_Speed_Limit : 0|8@1+ (1,0) [0|255] "" Vector__XXX
 SG_ Cruise_Control_High_Set_Limit_Sp : 8|8@1+ (1,0) [0|255] "" Vector__XXX
 SG_ Cruise_Control_Low_Set_Limit_Spe : 16|8@1+ (1,0) [0|255] "" Vector__XXX

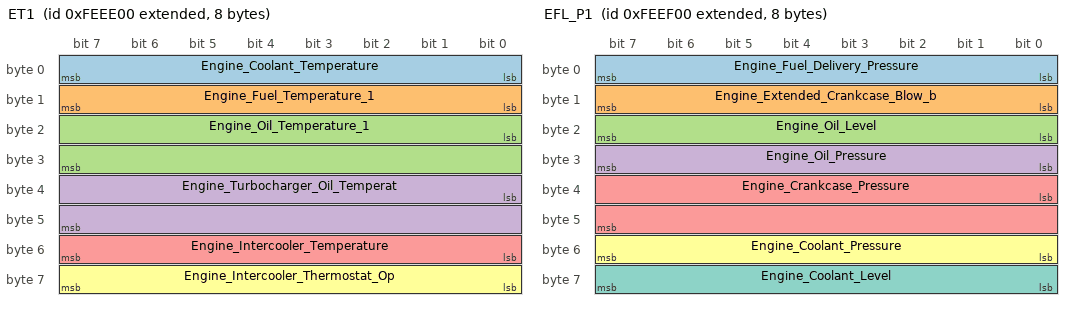
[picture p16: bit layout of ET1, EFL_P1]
BO_ 2164190720 ET1: 8 Vector__XXX
 SG_ Engine_Coolant_Temperature : 0|8@1+ (1,0) [0|255] "" Vector__XXX
 SG_ Engine_Fuel_Temperature_1 : 8|8@1+ (1,0) [0|255] "" Vector__XXX
 SG_ Engine_Oil_Temperature_1 : 16|16@1+ (1,0) [0|65535] "" Vector__XXX
 SG_ Engine_Turbocharger_Oil_Temperat : 32|16@1+ (1,0) [0|65535] "" Vector__XXX
 SG_ Engine_Intercooler_Temperature : 48|8@1+ (1,0) [0|255] "" Vector__XXX
 SG_ Engine_Intercooler_Thermostat_Op : 56|8@1+ (1,0) [0|255] "" Vector__XXX

BO_ 2164190976 EFL_P1: 8 Vector__XXX
 SG_ Engine_Fuel_Delivery_Pressure : 0|8@1+ (1,0) [0|255] "" Vector__XXX
 SG_ Engine_Extended_Crankcase_Blow_b : 8|8@1+ (1,0) [0|255] "" Vector__XXX
 SG_ Engine_Oil_Level : 16|8@1+ (1,0) [0|255] "" Vector__XXX
 SG_ Engine_Oil_Pressure : 24|8@1+ (1,0) [0|255] "" Vector__XXX
 SG_ Engine_Crankcase_Pressure : 32|16@1+ (1,0) [0|65535] "" Vector__XXX
 SG_ Engine_Coolant_Pressure : 48|8@1+ (1,0) [0|255] "" Vector__XXX
 SG_ Engine_Coolant_Level : 56|8@1+ (1,0) [0|255] "" Vector__XXX

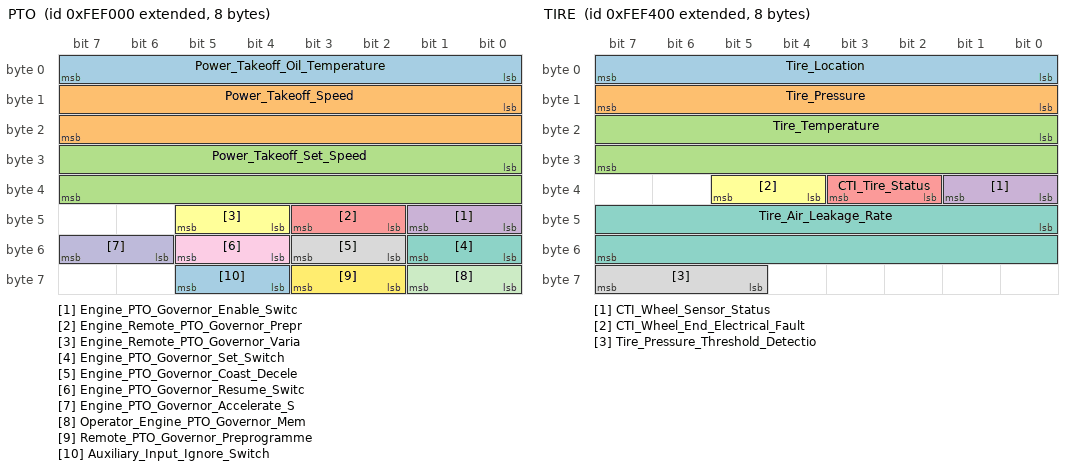
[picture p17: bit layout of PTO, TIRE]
BO_ 2164191232 PTO: 8 Vector__XXX
 SG_ Power_Takeoff_Oil_Temperature : 0|8@1+ (1,0) [0|255] "" Vector__XXX
 SG_ Power_Takeoff_Speed : 8|16@1+ (1,0) [0|65535] "" Vector__XXX
 SG_ Power_Takeoff_Set_Speed : 24|16@1+ (1,0) [0|65535] "" Vector__XXX
 SG_ Engine_PTO_Governor_Enable_Switc : 40|2@1+ (1,0) [0|3] "" Vector__XXX
 SG_ Engine_Remote_PTO_Governor_Prepr : 42|2@1+ (1,0) [0|3] "" Vector__XXX
 SG_ Engine_Remote_PTO_Governor_Varia : 44|2@1+ (1,0) [0|3] "" Vector__XXX
 SG_ Engine_PTO_Governor_Set_Switch : 48|2@1+ (1,0) [0|3] "" Vector__XXX
 SG_ Engine_PTO_Governor_Coast_Decele : 50|2@1+ (1,0) [0|3] "" Vector__XXX
 SG_ Engine_PTO_Governor_Resume_Switc : 52|2@1+ (1,0) [0|3] "" Vector__XXX
 SG_ Engine_PTO_Governor_Accelerate_S : 54|2@1+ (1,0) [0|3] "" Vector__XXX
 SG_ Operator_Engine_PTO_Governor_Mem : 56|2@1+ (1,0) [0|3] "" Vector__XXX
 SG_ Remote_PTO_Governor_Preprogramme : 58|2@1+ (1,0) [0|3] "" Vector__XXX
 SG_ Auxiliary_Input_Ignore_Switch : 60|2@1+ (1,0) [0|3] "" Vector__XXX

BO_ 2164191488 CCVS: 8 Vector__XXX
 SG_ Two_Speed_Axle_Switch : 0|2@1+ (1,0) [0|3] "" Vector__XXX
 SG_ Parking_Brake_Switch : 2|2@1+ (1,0) [0|3] "" Vector__XXX
 SG_ Cruise_Control_Pause_Switch : 4|2@1+ (1,0) [0|3] "" Vector__XXX
 SG_ Park_Brake_Release_Inhibit_Reque : 6|2@1+ (1,0) [0|3] "" Vector__XXX
 SG_ Wheel_Based_Vehicle_Speed : 8|16@1+ (1,0) [0|65535] "" Vector__XXX
 SG_ Cruise_Control_Active : 24|2@1+ (1,0) [0|3] "" Vector__XXX
 SG_ Cruise_Control_Enable_Switch : 26|2@1+ (1,0) [0|3] "" Vector__XXX
 SG_ Brake_Switch : 28|2@1+ (1,0) [0|3] "" Vector__XXX
 SG_ Clutch_Switch : 30|2@1+ (1,0) [0|3] "" Vector__XXX
 SG_ Cruise_Control_Set_Switch : 32|2@1+ (1,0) [0|3] "" Vector__XXX
 SG_ Cruise_Control_Coast__Decelerate : 34|2@1+ (1,0) [0|3] "" Vector__XXX
 SG_ Cruise_Control_Resume_Switch : 36|2@1+ (1,0) [0|3] "" Vector__XXX
 SG_ Cruise_Control_Accelerate_Switch : 38|2@1+ (1,0) [0|3] "" Vector__XXX
 SG_ Cruise_Control_Set_Speed : 40|8@1+ (1,0) [0|255] "" Vector__XXX
 SG_ PTO_Governor_State : 48|5@1+ (1,0) [0|31] "" Vector__XXX
 SG_ Cruise_Control_States : 53|3@1+ (1,0) [0|7] "" Vector__XXX
 SG_ Engine_Idle_Increment_Switch : 56|2@1+ (1,0) [0|3] "" Vector__XXX
 SG_ Engine_Idle_Decrement_Switch : 58|2@1+ (1,0) [0|3] "" Vector__XXX
 SG_ Engine_Test_Mode_Switch : 60|2@1+ (1,0) [0|3] "" Vector__XXX
 SG_ Engine_Shutdown_Override_Switch : 62|2@1+ (1,0) [0|3] "" Vector__XXX

BO_ 2164191744 LFE: 8 Vector__XXX
 SG_ Engine_Fuel_Rate : 0|16@1+ (1,0) [0|65535] "" Vector__XXX
 SG_ Engine_Instantaneous_Fuel_Econom : 16|16@1+ (1,0) [0|65535] "" Vector__XXX
 SG_ Engine_Average_Fuel_Economy : 32|16@1+ (1,0) [0|65535] "" Vector__XXX
 SG_ Engine_Throttle_Position : 48|8@1+ (1,0) [0|255] "" Vector__XXX
 SG_ Engine_Throttle_2_Position : 56|8@1+ (1,0) [0|255] "" Vector__XXX

BO_ 2164192000 VP: 8 Vector__XXX
 SG_ Latitude : 0|32@1+ (1,0) [0|4294967295] "" Vector__XXX
 SG_ Longitude : 32|32@1+ (1,0) [0|4294967295] "" Vector__XXX

BO_ 2164192256 TIRE: 8 Vector__XXX
 SG_ Tire_Location : 0|8@1+ (1,0) [0|255] "" Vector__XXX
 SG_ Tire_Pressure : 8|8@1+ (1,0) [0|255] "" Vector__XXX
 SG_ Tire_Temperature : 16|16@1+ (1,0) [0|65535] "" Vector__XXX
 SG_ CTI_Wheel_Sensor_Status : 32|2@1+ (1,0) [0|3] "" Vector__XXX
 SG_ CTI_Tire_Status : 34|2@1+ (1,0) [0|3] "" Vector__XXX
 SG_ CTI_Wheel_End_Electrical_Fault : 36|2@1+ (1,0) [0|3] "" Vector__XXX
 SG_ Tire_Air_Leakage_Rate : 40|16@1+ (1,0) [0|65535] "" Vector__XXX
 SG_ Tire_Pressure_Threshold_Detectio : 61|3@1+ (1,0) [0|7] "" Vector__XXX

BO_ 2164192512 AMB: 8 Vector__XXX
 SG_ Barometric_Pressure : 0|8@1+ (1,0) [0|255] "" Vector__XXX
 SG_ Cab_Interior_Temperature : 8|16@1+ (1,0) [0|65535] "" Vector__XXX
 SG_ Ambient_Air_Temperature : 24|16@1+ (1,0) [0|65535] "" Vector__XXX
 SG_ Engine_Air_Inlet_Temperature : 40|8@1+ (1,0) [0|255] "" Vector__XXX
 SG_ Road_Surface_Temperature : 48|16@1+ (1,0) [0|65535] "" Vector__XXX

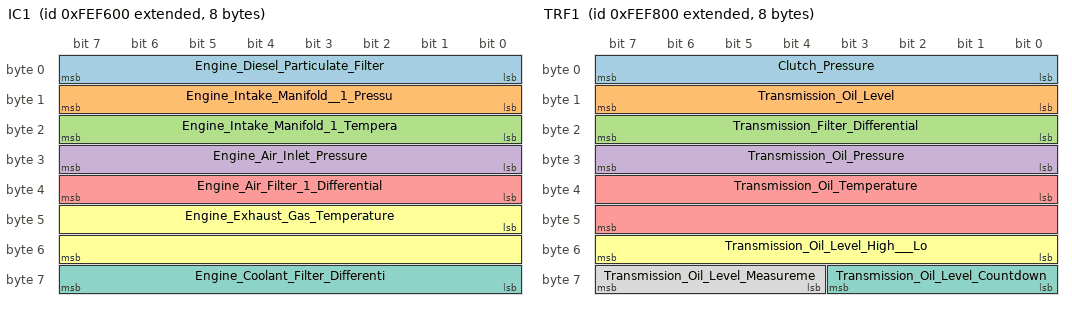
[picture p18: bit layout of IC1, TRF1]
BO_ 2164192768 IC1: 8 Vector__XXX
 SG_ Engine_Diesel_Particulate_Filter : 0|8@1+ (1,0) [0|255] "" Vector__XXX
 SG_ Engine_Intake_Manifold__1_Pressu : 8|8@1+ (1,0) [0|255] "" Vector__XXX
 SG_ Engine_Intake_Manifold_1_Tempera : 16|8@1+ (1,0) [0|255] "" Vector__XXX
 SG_ Engine_Air_Inlet_Pressure : 24|8@1+ (1,0) [0|255] "" Vector__XXX
 SG_ Engine_Air_Filter_1_Differential : 32|8@1+ (1,0) [0|255] "" Vector__XXX
 SG_ Engine_Exhaust_Gas_Temperature : 40|16@1+ (1,0) [0|65535] "" Vector__XXX
 SG_ Engine_Coolant_Filter_Differenti : 56|8@1+ (1,0) [0|255] "" Vector__XXX

BO_ 2164193024 VEP1: 8 Vector__XXX
 SG_ Net_Battery_Current : 0|8@1+ (1,0) [0|255] "" Vector__XXX
 SG_ Alternator_Current : 8|8@1+ (1,0) [0|255] "" Vector__XXX
 SG_ Charging_System_Potential__Volta : 16|16@1+ (1,0) [0|65535] "" Vector__XXX
 SG_ Battery_Potential___Power_Input_ : 32|16@1+ (1,0) [0|65535] "" Vector__XXX
 SG_ Keyswitch_Battery_Potential : 48|16@1+ (1,0) [0|65535] "" Vector__XXX

BO_ 2164193280 TRF1: 8 Vector__XXX
 SG_ Clutch_Pressure : 0|8@1+ (1,0) [0|255] "" Vector__XXX
 SG_ Transmission_Oil_Level : 8|8@1+ (1,0) [0|255] "" Vector__XXX
 SG_ Transmission_Filter_Differential : 16|8@1+ (1,0) [0|255] "" Vector__XXX
 SG_ Transmission_Oil_Pressure : 24|8@1+ (1,0) [0|255] "" Vector__XXX
 SG_ Transmission_Oil_Temperature : 32|16@1+ (1,0) [0|65535] "" Vector__XXX
 SG_ Transmission_Oil_Level_High___Lo : 48|8@1+ (1,0) [0|255] "" Vector__XXX
 SG_ Transmission_Oil_Level_Countdown : 56|4@1+ (1,0) [0|15] "" Vector__XXX
 SG_ Transmission_Oil_Level_Measureme : 60|4@1+ (1,0) [0|15] "" Vector__XXX

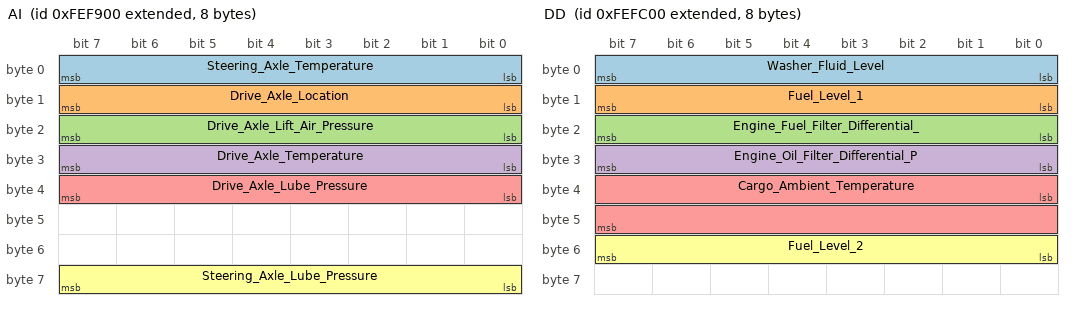
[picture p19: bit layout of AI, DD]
BO_ 2164193536 AI: 8 Vector__XXX
 SG_ Steering_Axle_Temperature : 0|8@1+ (1,0) [0|255] "" Vector__XXX
 SG_ Drive_Axle_Location : 8|8@1+ (1,0) [0|255] "" Vector__XXX
 SG_ Drive_Axle_Lift_Air_Pressure : 16|8@1+ (1,0) [0|255] "" Vector__XXX
 SG_ Drive_Axle_Temperature : 24|8@1+ (1,0) [0|255] "" Vector__XXX
 SG_ Drive_Axle_Lube_Pressure : 32|8@1+ (1,0) [0|255] "" Vector__XXX
 SG_ Steering_Axle_Lube_Pressure : 56|8@1+ (1,0) [0|255] "" Vector__XXX

BO_ 2164193792 B: 8 Vector__XXX
 SG_ Brake_Application_Pressure : 0|8@1+ (1,0) [0|255] "" Vector__XXX
 SG_ Brake_Primary_Pressure : 8|8@1+ (1,0) [0|255] "" Vector__XXX
 SG_ Brake_Secondary_Pressure : 16|8@1+ (1,0) [0|255] "" Vector__XXX
 SG_ Parking_Brake_Actuator : 24|2@1+ (1,0) [0|3] "" Vector__XXX
 SG_ Parking_Brake_Red_Warning_Signal : 26|2@1+ (1,0) [0|3] "" Vector__XXX
 SG_ Park_Brake_Release_Inhibit_Statu : 28|2@1+ (1,0) [0|3] "" Vector__XXX

BO_ 2164194048 RF: 8 Vector__XXX
 SG_ Hydraulic_Retarder_Pressure : 0|8@1+ (1,0) [0|255] "" Vector__XXX
 SG_ Hydraulic_Retarder_Oil_Temperatu : 8|8@1+ (1,0) [0|255] "" Vector__XXX

BO_ 2164194304 DD: 8 Vector__XXX
 SG_ Washer_Fluid_Level : 0|8@1+ (1,0) [0|255] "" Vector__XXX
 SG_ Fuel_Level_1 : 8|8@1+ (1,0) [0|255] "" Vector__XXX
 SG_ Engine_Fuel_Filter_Differential_ : 16|8@1+ (1,0) [0|255] "" Vector__XXX
 SG_ Engine_Oil_Filter_Differential_P : 24|8@1+ (1,0) [0|255] "" Vector__XXX
 SG_ Cargo_Ambient_Temperature : 32|16@1+ (1,0) [0|65535] "" Vector__XXX
 SG_ Fuel_Level_2 : 48|8@1+ (1,0) [0|255] "" Vector__XXX

BO_ 2164194560 A1: 8 Vector__XXX
 SG_ Engine_Blower_Bypass_Valve_Posit : 0|8@1+ (1,0) [0|255] "" Vector__XXX
 SG_ Engine_Gas_Supply_Pressure : 8|16@1+ (1,0) [0|65535] "" Vector__XXX

BO_ 2164194816 AWPP: 8 Vector__XXX
 SG_ Auxiliary_Pump_Pressure : 0|8@1+ (1,0) [0|255] "" Vector__XXX

BO_ 2164195072 WFI: 8 Vector__XXX
 SG_ Water_In_Fuel_Indicator : 0|2@1+ (1,0) [0|3] "" Vector__XXX

BA_DEF_ BO_ "VFrameFormat" ENUM "StandardCAN","ExtendedCAN","StandardCAN_FD","ExtendedCAN_FD","J1939PG";
BA_DEF_ SG_ "SPN" INT 0 524287;
BA_DEF_ SG_ "SystemSignalLongSymbol" STRING;
BA_ "VFrameFormat" BO_ 2164146432 4;
BA_ "VFrameFormat" BO_ 2164148736 4;
BA_ "VFrameFormat" BO_ 2164148992 4;
BA_ "VFrameFormat" BO_ 2164149248 4;
BA_ "VFrameFormat" BO_ 2164149504 4;
BA_ "VFrameFormat" BO_ 2164149760 4;
BA_ "VFrameFormat" BO_ 2164150016 4;
BA_ "VFrameFormat" BO_ 2164150272 4;
BA_ "VFrameFormat" BO_ 2164150528 4;
BA_ "VFrameFormat" BO_ 2164150784 4;
BA_ "VFrameFormat" BO_ 2164151040 4;
BA_ "VFrameFormat" BO_ 2164151296 4;
BA_ "VFrameFormat" BO_ 2164151552 4;
BA_ "VFrameFormat" BO_ 2164151808 4;
BA_ "VFrameFormat" BO_ 2164152064 4;
BA_ "VFrameFormat" BO_ 2164152320 4;
BA_ "VFrameFormat" BO_ 2164152576 4;
BA_ "VFrameFormat" BO_ 2164152832 4;
BA_ "VFrameFormat" BO_ 2164153088 4;
BA_ "VFrameFormat" BO_ 2164155904 4;
BA_ "VFrameFormat" BO_ 2164156160 4;
BA_ "VFrameFormat" BO_ 2164156416 4;
BA_ "VFrameFormat" BO_ 2164156672 4;
BA_ "VFrameFormat" BO_ 2164156928 4;
BA_ "VFrameFormat" BO_ 2164157184 4;
BA_ "VFrameFormat" BO_ 2164157440 4;
BA_ "VFrameFormat" BO_ 2164157696 4;
BA_ "VFrameFormat" BO_ 2164157952 4;
BA_ "VFrameFormat" BO_ 2164158208 4;
BA_ "VFrameFormat" BO_ 2164158464 4;
BA_ "VFrameFormat" BO_ 2164158720 4;
BA_ "VFrameFormat" BO_ 2164158976 4;
BA_ "VFrameFormat" BO_ 2164159232 4;
BA_ "VFrameFormat" BO_ 2164159488 4;
BA_ "VFrameFormat" BO_ 2164159744 4;
BA_ "VFrameFormat" BO_ 2164160000 4;
BA_ "VFrameFormat" BO_ 2164160256 4;
BA_ "VFrameFormat" BO_ 2164160512 4;
BA_ "VFrameFormat" BO_ 2164160768 4;
BA_ "VFrameFormat" BO_ 2164161024 4;
BA_ "VFrameFormat" BO_ 2164161280 4;
BA_ "VFrameFormat" BO_ 2164161536 4;
BA_ "VFrameFormat" BO_ 2164161792 4;
BA_ "VFrameFormat" BO_ 2164162048 4;
BA_ "VFrameFormat" BO_ 2164162304 4;
BA_ "VFrameFormat" BO_ 2164162560 4;
BA_ "VFrameFormat" BO_ 2164162816 4;
BA_ "VFrameFormat" BO_ 2164163072 4;
BA_ "VFrameFormat" BO_ 2164163328 4;
BA_ "VFrameFormat" BO_ 2164163584 4;
BA_ "VFrameFormat" BO_ 2164163840 4;
BA_ "VFrameFormat" BO_ 2164164096 4;
BA_ "VFrameFormat" BO_ 2164164352 4;
BA_ "VFrameFormat" BO_ 2164164608 4;
BA_ "VFrameFormat" BO_ 2164164864 4;
BA_ "VFrameFormat" BO_ 2164165120 4;
BA_ "VFrameFormat" BO_ 2164165376 4;
BA_ "VFrameFormat" BO_ 2164165632 4;
BA_ "VFrameFormat" BO_ 2164165888 4;
BA_ "VFrameFormat" BO_ 2164166144 4;
BA_ "VFrameFormat" BO_ 2164166400 4;
BA_ "VFrameFormat" BO_ 2164166656 4;
BA_ "VFrameFormat" BO_ 2164166912 4;
BA_ "VFrameFormat" BO_ 2164167168 4;
BA_ "VFrameFormat" BO_ 2164167424 4;
BA_ "VFrameFormat" BO_ 2164167680 4;
BA_ "VFrameFormat" BO_ 2164167936 4;
BA_ "VFrameFormat" BO_ 2164168192 4;
BA_ "VFrameFormat" BO_ 2164168448 4;
BA_ "VFrameFormat" BO_ 2164168704 4;
BA_ "VFrameFormat" BO_ 2164168960 4;
BA_ "VFrameFormat" BO_ 2164169216 4;
BA_ "VFrameFormat" BO_ 2164169472 4;
BA_ "VFrameFormat" BO_ 2164169728 4;
BA_ "VFrameFormat" BO_ 2164169984 4;
BA_ "VFrameFormat" BO_ 2164170240 4;
BA_ "VFrameFormat" BO_ 2164170496 4;
BA_ "VFrameFormat" BO_ 2164170752 4;
BA_ "VFrameFormat" BO_ 2164171008 4;
BA_ "VFrameFormat" BO_ 2164171264 4;
BA_ "VFrameFormat" BO_ 2164171520 4;
BA_ "VFrameFormat" BO_ 2164171776 4;
BA_ "VFrameFormat" BO_ 2164172032 4;
BA_ "VFrameFormat" BO_ 2164172288 4;
BA_ "VFrameFormat" BO_ 2164172544 4;
BA_ "VFrameFormat" BO_ 2164172800 4;
BA_ "VFrameFormat" BO_ 2164173056 4;
BA_ "VFrameFormat" BO_ 2164173312 4;
BA_ "VFrameFormat" BO_ 2164173568 4;
BA_ "VFrameFormat" BO_ 2164173824 4;
BA_ "VFrameFormat" BO_ 2164174080 4;
BA_ "VFrameFormat" BO_ 2164174336 4;
BA_ "VFrameFormat" BO_ 2164174592 4;
BA_ "VFrameFormat" BO_ 2164174848 4;
BA_ "VFrameFormat" BO_ 2164175104 4;
BA_ "VFrameFormat" BO_ 2164175360 4;
BA_ "VFrameFormat" BO_ 2164175616 4;
BA_ "VFrameFormat" BO_ 2164175872 4;
BA_ "VFrameFormat" BO_ 2164176128 4;
BA_ "VFrameFormat" BO_ 2164176384 4;
BA_ "VFrameFormat" BO_ 2164176640 4;
BA_ "VFrameFormat" BO_ 2164176896 4;
BA_ "VFrameFormat" BO_ 2164177152 4;
BA_ "VFrameFormat" BO_ 2164177408 4;
BA_ "VFrameFormat" BO_ 2164177664 4;
BA_ "VFrameFormat" BO_ 2164177920 4;
BA_ "VFrameFormat" BO_ 2164178176 4;
BA_ "VFrameFormat" BO_ 2164178432 4;
BA_ "VFrameFormat" BO_ 2164178688 4;
BA_ "VFrameFormat" BO_ 2164178944 4;
BA_ "VFrameFormat" BO_ 2164179200 4;
BA_ "VFrameFormat" BO_ 2164179456 4;
BA_ "VFrameFormat" BO_ 2164179712 4;
BA_ "VFrameFormat" BO_ 2164180224 4;
BA_ "VFrameFormat" BO_ 2164180736 4;
BA_ "VFrameFormat" BO_ 2164184320 4;
BA_ "VFrameFormat" BO_ 2164185344 4;
BA_ "VFrameFormat" BO_ 2164185600 4;
BA_ "VFrameFormat" BO_ 2164185856 4;
BA_ "VFrameFormat" BO_ 2164186112 4;
BA_ "VFrameFormat" BO_ 2164186368 4;
BA_ "VFrameFormat" BO_ 2164186624 4;
BA_ "VFrameFormat" BO_ 2164186880 4;
BA_ "VFrameFormat" BO_ 2164187136 4;
BA_ "VFrameFormat" BO_ 2164187392 4;
BA_ "VFrameFormat" BO_ 2164187648 4;
BA_ "VFrameFormat" BO_ 2164187904 4;
BA_ "VFrameFormat" BO_ 2164188160 4;
BA_ "VFrameFormat" BO_ 2164188416 4;
BA_ "VFrameFormat" BO_ 2164188672 4;
BA_ "VFrameFormat" BO_ 2164188928 4;
BA_ "VFrameFormat" BO_ 2164189184 4;
BA_ "VFrameFormat" BO_ 2164189440 4;
BA_ "VFrameFormat" BO_ 2164189696 4;
BA_ "VFrameFormat" BO_ 2164189952 4;
BA_ "VFrameFormat" BO_ 2164190208 4;
BA_ "VFrameFormat" BO_ 2164190464 4;
BA_ "VFrameFormat" BO_ 2164190720 4;
BA_ "VFrameFormat" BO_ 2164190976 4;
BA_ "VFrameFormat" BO_ 2164191232 4;
BA_ "VFrameFormat" BO_ 2164191488 4;
BA_ "VFrameFormat" BO_ 2164191744 4;
BA_ "VFrameFormat" BO_ 2164192000 4;
BA_ "VFrameFormat" BO_ 2164192256 4;
BA_ "VFrameFormat" BO_ 2164192512 4;
BA_ "VFrameFormat" BO_ 2164192768 4;
BA_ "VFrameFormat" BO_ 2164193024 4;
BA_ "VFrameFormat" BO_ 2164193280 4;
BA_ "VFrameFormat" BO_ 2164193536 4;
BA_ "VFrameFormat" BO_ 2164193792 4;
BA_ "VFrameFormat" BO_ 2164194048 4;
BA_ "VFrameFormat" BO_ 2164194304 4;
BA_ "VFrameFormat" BO_ 2164194560 4;
BA_ "VFrameFormat" BO_ 2164194816 4;
BA_ "VFrameFormat" BO_ 2164195072 4;
BA_ "SPN" SG_ 2164146432 Running_Light_Command 2403;
BA_ "SPN" SG_ 2164146432 Alternate_Beam_Head_Light_Comman 2351;
BA_ "SystemSignalLongSymbol" SG_ 2164146432 Alternate_Beam_Head_Light_Comman "Alternate Beam Head Light Command";
BA_ "SPN" SG_ 2164146432 Low_Beam_Head_Light_Command 2349;
BA_ "SPN" SG_ 2164146432 High_Beam_Head_Light_Command 2347;
BA_ "SPN" SG_ 2164146432 Tractor_Front_Fog_Lights_Command 2387;
BA_ "SPN" SG_ 2164146432 Rotating_Beacon_Light_Command 2385;
BA_ "SPN" SG_ 2164146432 Right_Turn_Signal_Lights_Command 2369;
BA_ "SPN" SG_ 2164146432 Left_Turn_Signal_Lights_Command 2367;
BA_ "SPN" SG_ 2164146432 Back_Up_Light_and_Alarm_Horn_Com 2391;
BA_ "SystemSignalLongSymbol" SG_ 2164146432 Back_Up_Light_and_Alarm_Horn_Com "Back Up Light and Alarm Horn Command";
BA_ "SPN" SG_ 2164146432 Center_Stop_Light_Command 2375;
BA_ "SPN" SG_ 2164146432 Right_Stop_Light_Command 2373;
BA_ "SPN" SG_ 2164146432 Left_Stop_Light_Command 2371;
BA_ "SPN" SG_ 2164146432 Implement_Clearance_Light_Comman 2383;
BA_ "SystemSignalLongSymbol" SG_ 2164146432 Implement_Clearance_Light_Comman "Implement Clearance Light Command";
BA_ "SPN" SG_ 2164146432 Tractor_Clearance_Light_Command 2381;
BA_ "SPN" SG_ 2164146432 Implement_Marker_Light_Command 2379;
BA_ "SPN" SG_ 2164146432 Tractor_Marker_Light_Command 2377;
BA_ "SPN" SG_ 2164146432 Rear_Fog_Light_Command 2389;
BA_ "SPN" SG_ 2164146432 Tractor_Underside_Mounted_Work_L 2357;
BA_ "SystemSignalLongSymbol" SG_ 2164146432 Tractor_Underside_Mounted_Work_L "Tractor Underside Mounted Work Lights Command";
BA_ "SPN" SG_ 2164146432 Tractor_Rear_Low_Mounted_Work_Li 2359;
BA_ "SystemSignalLongSymbol" SG_ 2164146432 Tractor_Rear_Low_Mounted_Work_Li "Tractor Rear Low Mounted Work Lights Command";
BA_ "SPN" SG_ 2164146432 Tractor_Rear_High_Mounted_Work_L 2361;
BA_ "SystemSignalLongSymbol" SG_ 2164146432 Tractor_Rear_High_Mounted_Work_L "Tractor Rear High Mounted Work Lights Command";
BA_ "SPN" SG_ 2164146432 Tractor_Side_Low_Mounted_Work_Li 2363;
BA_ "SystemSignalLongSymbol" SG_ 2164146432 Tractor_Side_Low_Mounted_Work_Li "Tractor Side Low Mounted Work Lights Command";
BA_ "SPN" SG_ 2164146432 Tractor_Side_High_Mounted_Work_L 2365;
BA_ "SystemSignalLongSymbol" SG_ 2164146432 Tractor_Side_High_Mounted_Work_L "Tractor Side High Mounted Work Lights Command";
BA_ "SPN" SG_ 2164146432 Tractor_Front_Low_Mounted_Work_L 2353;
BA_ "SystemSignalLongSymbol" SG_ 2164146432 Tractor_Front_Low_Mounted_Work_L "Tractor Front Low Mounted Work Lights Command";
BA_ "SPN" SG_ 2164146432 Tractor_Front_High_Mounted_Work_ 2355;
BA_ "SystemSignalLongSymbol" SG_ 2164146432 Tractor_Front_High_Mounted_Work_ "Tractor Front High Mounted Work Lights Command";
BA_ "SPN" SG_ 2164146432 Implement_OEM_Option_2_Light_Com 2397;
BA_ "SystemSignalLongSymbol" SG_ 2164146432 Implement_OEM_Option_2_Light_Com "Implement OEM Option 2 Light Command";
BA_ "SPN" SG_ 2164146432 Implement_OEM_Option_1_Light_Com 2395;
BA_ "SystemSignalLongSymbol" SG_ 2164146432 Implement_OEM_Option_1_Light_Com "Implement OEM Option 1 Light Command";
BA_ "SPN" SG_ 2164146432 Implement_Right_Facing_Work_Ligh 2406;
BA_ "SystemSignalLongSymbol" SG_ 2164146432 Implement_Right_Facing_Work_Ligh "Implement Right Facing Work Light Command";
BA_ "SPN" SG_ 2164146432 Implement_Left_Facing_Work_Light 2597;
BA_ "SystemSignalLongSymbol" SG_ 2164146432 Implement_Left_Facing_Work_Light "Implement Left Facing Work Light Command";
BA_ "SPN" SG_ 2164146432 Lighting_Data_Request_Command 2393;
BA_ "SPN" SG_ 2164146432 Implement_Right_Forward_Work_Lig 2401;
BA_ "SystemSignalLongSymbol" SG_ 2164146432 Implement_Right_Forward_Work_Lig "Implement Right Forward Work Light Command";
BA_ "SPN" SG_ 2164146432 Implement_Left_Forward_Work_Ligh 2399;
BA_ "SystemSignalLongSymbol" SG_ 2164146432 Implement_Left_Forward_Work_Ligh "Implement Left Forward Work Light Command";
BA_ "SPN" SG_ 2164146432 Implement_Rear_Work_Light_Comman 2405;
BA_ "SystemSignalLongSymbol" SG_ 2164146432 Implement_Rear_Work_Light_Comman "Implement Rear Work Light Command";
BA_ "SPN" SG_ 2164148736 Transmission_Current_Range_Displ 4176;
BA_ "SystemSignalLongSymbol" SG_ 2164148736 Transmission_Current_Range_Displ "Transmission Current Range Display Blank State";
BA_ "SPN" SG_ 2164148736 Transmission_Service_Indicator 4178;
BA_ "SPN" SG_ 2164148736 Transmission_Requested_Range_Dis0 1850;
BA_ "SystemSignalLongSymbol" SG_ 2164148736 Transmission_Requested_Range_Dis0 "Transmission Requested Range Display Blank State";
BA_ "SPN" SG_ 2164148736 Transmission_Requested_Range_Dis1 1849;
BA_ "SystemSignalLongSymbol" SG_ 2164148736 Transmission_Requested_Range_Dis1 "Transmission Requested Range Display Flash State";
BA_ "SPN" SG_ 2164148736 Transmission_Ready_for_Brake_Rel 3086;
BA_ "SystemSignalLongSymbol" SG_ 2164148736 Transmission_Ready_for_Brake_Rel "Transmission Ready for Brake Release";
BA_ "SPN" SG_ 2164148736 Active_Shift_Console_Indicator 2945;
BA_ "SPN" SG_ 2164148736 Transmission_Engine_Crank_Enable 2900;
BA_ "SPN" SG_ 2164148736 Transmission_Shift_Inhibit_Indic 1851;
BA_ "SystemSignalLongSymbol" SG_ 2164148736 Transmission_Shift_Inhibit_Indic "Transmission Shift Inhibit Indicator";
BA_ "SPN" SG_ 2164148736 Transmission_Mode_4_Indicator 2539;
BA_ "SPN" SG_ 2164148736 Transmission_Mode_3_Indicator 2538;
BA_ "SPN" SG_ 2164148736 Transmission_Mode_2_Indicator 2537;
BA_ "SPN" SG_ 2164148736 Transmission_Mode_1_Indicator 2536;
BA_ "SPN" SG_ 2164148736 Transmission_Requested_Gear_Feed 3289;
BA_ "SystemSignalLongSymbol" SG_ 2164148736 Transmission_Requested_Gear_Feed "Transmission Requested Gear Feedback";
BA_ "SPN" SG_ 2164148736 Transmission_Mode_5_Indicator 4250;
BA_ "SPN" SG_ 2164148736 Transmission_Mode_6_Indicator 4251;
BA_ "SPN" SG_ 2164148736 Transmission_Mode_7_Indicator 4252;
BA_ "SPN" SG_ 2164148736 Transmission_Mode_8_Indicator 4253;
BA_ "SPN" SG_ 2164148736 Transmission_Reverse_Gear_Shift_ 4261;
BA_ "SystemSignalLongSymbol" SG_ 2164148736 Transmission_Reverse_Gear_Shift_ "Transmission Reverse Gear Shift Inhibit Status";
BA_ "SPN" SG_ 2164148992 Transmission_Torque_Limit 1845;
BA_ "SPN" SG_ 2164149248 Rear_Black_Out_Marker_Select 1840;
BA_ "SPN" SG_ 2164149248 Front_Black_Out_Marker_Lamp_Sele 1839;
BA_ "SystemSignalLongSymbol" SG_ 2164149248 Front_Black_Out_Marker_Lamp_Sele "Front Black Out Marker Lamp Select";
BA_ "SPN" SG_ 2164149248 Convoy_Lamp_Select 1838;
BA_ "SPN" SG_ 2164149248 Convoy_Driving_Lamp_Select 1837;
BA_ "SPN" SG_ 2164149248 Black_Out_Brake_Stop_Lamp_Select 1841;
BA_ "SPN" SG_ 2164149248 Night_Vision_Illuminator_Select 1843;
BA_ "SPN" SG_ 2164149248 Black_Out_Work_Lamp_Select 1842;
BA_ "SPN" SG_ 2164149248 Operators_Black_Out_Intensity_Se 1844;
BA_ "SystemSignalLongSymbol" SG_ 2164149248 Operators_Black_Out_Intensity_Se "Operators Black Out Intensity Selection";
BA_ "SPN" SG_ 2164149504 Engine_Total_Average_Fuel_Rate 1834;
BA_ "SPN" SG_ 2164149504 Engine_Total_Average_Fuel_Econom 1835;
BA_ "SystemSignalLongSymbol" SG_ 2164149504 Engine_Total_Average_Fuel_Econom "Engine Total Average Fuel Economy";
BA_ "SPN" SG_ 2164149760 Position_of_doors 1821;
BA_ "SPN" SG_ 2164149760 Ramp___Wheel_Chair_Lift_Position 1820;
BA_ "SPN" SG_ 2164149760 Status_2_of_doors 3411;
BA_ "SPN" SG_ 2164150016 VDC_Information_Signal 1813;
BA_ "SPN" SG_ 2164150016 VDC_Fully_Operational 1814;
BA_ "SPN" SG_ 2164150016 VDC_brake_light_request 1815;
BA_ "SPN" SG_ 2164150016 ROP_Engine_Control_active 1816;
BA_ "SPN" SG_ 2164150016 ROP_Brake_Control_active 1818;
BA_ "SPN" SG_ 2164150016 YC_Engine_Control_active 1817;
BA_ "SPN" SG_ 2164150016 YC_Brake_Control_active 1819;
BA_ "SPN" SG_ 2164150272 Battery_1_Temperature 1800;
BA_ "SPN" SG_ 2164150272 Battery_2_Temperature 1801;
BA_ "SPN" SG_ 2164150528 Requested_ACC_Distance_Mode 1799;
BA_ "SPN" SG_ 2164150784 Alternator_Current__High_Range_R 1795;
BA_ "SystemSignalLongSymbol" SG_ 2164150784 Alternator_Current__High_Range_R "Alternator Current (High Range/Resolution)";
BA_ "SPN" SG_ 2164150784 Net_Battery_Current__High_Range_ 2579;
BA_ "SystemSignalLongSymbol" SG_ 2164150784 Net_Battery_Current__High_Range_ "Net Battery Current (High Range/Resolution)";
BA_ "SPN" SG_ 2164151040 Low_Limit_Threshold_for_Maximum_0 1776;
BA_ "SystemSignalLongSymbol" SG_ 2164151040 Low_Limit_Threshold_for_Maximum_0 "Low Limit Threshold for Maximum RPM from Retarder";
BA_ "SPN" SG_ 2164151040 High_Limit_Threshold_for_Minimum0 1777;
BA_ "SystemSignalLongSymbol" SG_ 2164151040 High_Limit_Threshold_for_Minimum0 "High Limit Threshold for Minimum Continuous RPM from Retarder";
BA_ "SPN" SG_ 2164151040 Low_Limit_Threshold_for_Maximum_1 1778;
BA_ "SystemSignalLongSymbol" SG_ 2164151040 Low_Limit_Threshold_for_Maximum_1 "Low Limit Threshold for Maximum Torque from Retarder";
BA_ "SPN" SG_ 2164151040 High_Limit_Threshold_for_Minimum1 1779;
BA_ "SystemSignalLongSymbol" SG_ 2164151040 High_Limit_Threshold_for_Minimum1 "High Limit Threshold for Minimum Continuous Torque from Retarder";
BA_ "SPN" SG_ 2164151040 Maximum_Continuous_Retarder_Spee 1780;
BA_ "SystemSignalLongSymbol" SG_ 2164151040 Maximum_Continuous_Retarder_Spee "Maximum Continuous Retarder Speed ";
BA_ "SPN" SG_ 2164151040 Minimum_Continuous_Retarder_Spee 1781;
BA_ "SystemSignalLongSymbol" SG_ 2164151040 Minimum_Continuous_Retarder_Spee "Minimum Continuous Retarder Speed";
BA_ "SPN" SG_ 2164151040 Maximum_Continuous_Retarder_Torq 1782;
BA_ "SystemSignalLongSymbol" SG_ 2164151040 Maximum_Continuous_Retarder_Torq "Maximum Continuous Retarder Torque";
BA_ "SPN" SG_ 2164151040 Minimum_Continuous_Retarder_Torq 1783;
BA_ "SystemSignalLongSymbol" SG_ 2164151040 Minimum_Continuous_Retarder_Torq "Minimum Continuous Retarder Torque";
BA_ "SPN" SG_ 2164151296 Engine_Low_Limit_Threshold_for_M0 1768;
BA_ "SystemSignalLongSymbol" SG_ 2164151296 Engine_Low_Limit_Threshold_for_M0 "Engine Low Limit Threshold for Maximum RPM from Engine";
BA_ "SPN" SG_ 2164151296 Engine_High_Limit_Threshold_for_0 1769;
BA_ "SystemSignalLongSymbol" SG_ 2164151296 Engine_High_Limit_Threshold_for_0 "Engine High Limit Threshold for Minimum Continuous Engine RPM";
BA_ "SPN" SG_ 2164151296 Engine_Low_Limit_Threshold_for_M1 1770;
BA_ "SystemSignalLongSymbol" SG_ 2164151296 Engine_Low_Limit_Threshold_for_M1 "Engine Low Limit Threshold for Maximum Torque from Engine";
BA_ "SPN" SG_ 2164151296 Engine_High_Limit_Threshold_for_1 1771;
BA_ "SystemSignalLongSymbol" SG_ 2164151296 Engine_High_Limit_Threshold_for_1 "Engine High Limit Threshold for Minimum Continuous Torque from Engine";
BA_ "SPN" SG_ 2164151296 Engine_Maximum_Continuous_RPM 1772;
BA_ "SPN" SG_ 2164151296 Engine_Minimum_Continuous_RPM 1773;
BA_ "SPN" SG_ 2164151296 Engine_Maximum_Continuous_Torque 1774;
BA_ "SPN" SG_ 2164151296 Engine_Minimum_Continuous_Torque 1775;
BA_ "SPN" SG_ 2164151552 Specific_Heat_Ratio 1767;
BA_ "SPN" SG_ 2164151808 Aftertreatment_1_SCR_Catalyst_Ta0 1761;
BA_ "SystemSignalLongSymbol" SG_ 2164151808 Aftertreatment_1_SCR_Catalyst_Ta0 "Aftertreatment 1 SCR Catalyst Tank Level";
BA_ "SPN" SG_ 2164151808 Aftertreatment_1_SCR_Catalyst_Ta1 3031;
BA_ "SystemSignalLongSymbol" SG_ 2164151808 Aftertreatment_1_SCR_Catalyst_Ta1 "Aftertreatment 1 SCR Catalyst Tank Temperature";
BA_ "SPN" SG_ 2164151808 Aftertreatment_1_SCR_Catalyst_Ta2 3517;
BA_ "SystemSignalLongSymbol" SG_ 2164151808 Aftertreatment_1_SCR_Catalyst_Ta2 "Aftertreatment 1 SCR Catalyst Tank Level 2";
BA_ "SPN" SG_ 2164151808 Aftertreatment_1_SCR_Catalyst_Ta3 3532;
BA_ "SystemSignalLongSymbol" SG_ 2164151808 Aftertreatment_1_SCR_Catalyst_Ta3 "Aftertreatment 1 SCR Catalyst Tank Level Preliminary FMI";
BA_ "SPN" SG_ 2164151808 Aftertreatment_1_SCR_Catalyst_Re0 4365;
BA_ "SystemSignalLongSymbol" SG_ 2164151808 Aftertreatment_1_SCR_Catalyst_Re0 "Aftertreatment 1 SCR Catalyst Reagent Tank 1 Temperature Preliminary FMI";
BA_ "SPN" SG_ 2164151808 Aftertreatment_1_SCR_Catalyst_Re1 4366;
BA_ "SystemSignalLongSymbol" SG_ 2164151808 Aftertreatment_1_SCR_Catalyst_Re1 "Aftertreatment 1 SCR Catalyst Reagent Tank 1 Heater Preliminary FMI";
BA_ "SPN" SG_ 2164152064 Damper_Stiffness_Front_Axle 1729;
BA_ "SPN" SG_ 2164152064 Damper_Stiffness_Rear_Axle 1730;
BA_ "SPN" SG_ 2164152064 Damper_Stiffness_Lift___Tag_Axle 1731;
BA_ "SPN" SG_ 2164152064 Electronic_Shock_Absorber_Contro0 1833;
BA_ "SystemSignalLongSymbol" SG_ 2164152064 Electronic_Shock_Absorber_Contro0 "Electronic Shock Absorber Control Mode -  Front Axle";
BA_ "SPN" SG_ 2164152064 Electronic_Shock_Absorber_Contro1 1832;
BA_ "SystemSignalLongSymbol" SG_ 2164152064 Electronic_Shock_Absorber_Contro1 "Electronic Shock Absorber Control Mode - Rear Axle";
BA_ "SPN" SG_ 2164152064 Electronic_Shock_Absorber_Contro2 1831;
BA_ "SystemSignalLongSymbol" SG_ 2164152064 Electronic_Shock_Absorber_Contro2 "Electronic Shock Absorber Control Mode - Lift/Tag Axle";
BA_ "SPN" SG_ 2164152320 Bellow_Pressure_Front_Axle_Left 1725;
BA_ "SPN" SG_ 2164152320 Bellow_Pressure_Front_Axle_Right 1726;
BA_ "SPN" SG_ 2164152320 Bellow_Pressure_Rear_Axle_Left 1727;
BA_ "SPN" SG_ 2164152320 Bellow_Pressure_Rear_Axle_Right 1728;
BA_ "SPN" SG_ 2164152576 Relative_Level_Front_Axle_Left 1721;
BA_ "SPN" SG_ 2164152576 Relative_Level_Front_Axle_Right 1722;
BA_ "SPN" SG_ 2164152576 Relative_Level_Rear_Axle_Left 1724;
BA_ "SPN" SG_ 2164152576 Relative_Level_Rear_Axle_Right 1723;
BA_ "SPN" SG_ 2164152832 Nominal_Level_Front_Axle 1734;
BA_ "SPN" SG_ 2164152832 Nominal_Level_Rear_Axle 1733;
BA_ "SPN" SG_ 2164152832 Below_Nominal_Level_Front_Axle 1738;
BA_ "SPN" SG_ 2164152832 Below_Nominal_Level_Rear_Axle 1754;
BA_ "SPN" SG_ 2164152832 Above_Nominal_Level_Front_Axle 1737;
BA_ "SPN" SG_ 2164152832 Above_Nominal_Level_Rear_Axle 1736;
BA_ "SPN" SG_ 2164152832 Lowering_Control_Mode_Front_Axle 1740;
BA_ "SPN" SG_ 2164152832 Lowering_Control_Mode_Rear_Axle 1755;
BA_ "SPN" SG_ 2164152832 Lifting_Control_Mode_Front_Axle 1739;
BA_ "SPN" SG_ 2164152832 Lifting_Control_Mode_Rear_Axle 1756;
BA_ "SPN" SG_ 2164152832 Kneeling_Information 1742;
BA_ "SPN" SG_ 2164152832 Level_Control_Mode 1741;
BA_ "SPN" SG_ 2164152832 Security_Device 1746;
BA_ "SPN" SG_ 2164152832 Vehicle_Motion_Inhibit 1745;
BA_ "SPN" SG_ 2164152832 Door_Release 1744;
BA_ "SPN" SG_ 2164152832 Lift_Axle_1_Position 1743;
BA_ "SPN" SG_ 2164152832 Front_Axle_in_Bumper_Range 1824;
BA_ "SPN" SG_ 2164152832 Rear_Axle_in_Bumper_Range 1823;
BA_ "SPN" SG_ 2164152832 Lift_Axle_2_Position 1822;
BA_ "SPN" SG_ 2164152832 Suspension_Remote_Control_1 1826;
BA_ "SPN" SG_ 2164152832 Suspension_Remote_control_2 1825;
BA_ "SPN" SG_ 2164152832 Suspension_Control_Refusal_Infor 1827;
BA_ "SystemSignalLongSymbol" SG_ 2164152832 Suspension_Control_Refusal_Infor "Suspension Control Refusal Information";
BA_ "SPN" SG_ 2164153088 Lane_Tracking_Status_Right_Side 1711;
BA_ "SPN" SG_ 2164153088 Lane_Tracking_Status_Left_Side 1710;
BA_ "SPN" SG_ 2164153088 Lane_Departure_Indication_Enable 1702;
BA_ "SystemSignalLongSymbol" SG_ 2164153088 Lane_Departure_Indication_Enable "Lane Departure Indication Enable Status";
BA_ "SPN" SG_ 2164155904 Battery_Main_Switch_Hold_State 1681;
BA_ "SPN" SG_ 2164156160 Auxiliary_Heater_Maximum_Output_ 1690;
BA_ "SystemSignalLongSymbol" SG_ 2164156160 Auxiliary_Heater_Maximum_Output_ "Auxiliary Heater Maximum Output Power";
BA_ "SPN" SG_ 2164156416 Hydraulic_Temperature 1638;
BA_ "SPN" SG_ 2164156416 Hydraulic_Oil_Filter_Restriction 1713;
BA_ "SystemSignalLongSymbol" SG_ 2164156416 Hydraulic_Oil_Filter_Restriction "Hydraulic Oil Filter Restriction Switch";
BA_ "SPN" SG_ 2164156416 Winch_Oil_Pressure_Switch 1857;
BA_ "SPN" SG_ 2164156416 Hydraulic_Oil_Level 2602;
BA_ "SPN" SG_ 2164156672 Engine_Intake_Manifold_1_Air_Tem 1636;
BA_ "SystemSignalLongSymbol" SG_ 2164156672 Engine_Intake_Manifold_1_Air_Tem "Engine Intake Manifold 1 Air Temperature (High Resolution)";
BA_ "SPN" SG_ 2164156672 Engine_Coolant_Temperature__High 1637;
BA_ "SystemSignalLongSymbol" SG_ 2164156672 Engine_Coolant_Temperature__High "Engine Coolant Temperature (High Resolution)";
BA_ "SPN" SG_ 2164156672 Engine_Intake_Valve_Actuation_Sy 2986;
BA_ "SystemSignalLongSymbol" SG_ 2164156672 Engine_Intake_Valve_Actuation_Sy "Engine Intake Valve Actuation System Oil Temperature";
BA_ "SPN" SG_ 2164156672 Engine_Charge_Air_Cooler_Outlet_ 2630;
BA_ "SystemSignalLongSymbol" SG_ 2164156672 Engine_Charge_Air_Cooler_Outlet_ "Engine Charge Air Cooler Outlet Temperature";
BA_ "SPN" SG_ 2164156928 Engine_Oil_Level_Remote_Reservoi 1380;
BA_ "SystemSignalLongSymbol" SG_ 2164156928 Engine_Oil_Level_Remote_Reservoi "Engine Oil Level Remote Reservoir";
BA_ "SPN" SG_ 2164156928 Engine_Fuel_Supply_Pump_Inlet_Pr 1381;
BA_ "SystemSignalLongSymbol" SG_ 2164156928 Engine_Fuel_Supply_Pump_Inlet_Pr "Engine Fuel Supply Pump Inlet Pressure";
BA_ "SPN" SG_ 2164156928 Engine_Fuel_Filter__suction_side 1382;
BA_ "SystemSignalLongSymbol" SG_ 2164156928 Engine_Fuel_Filter__suction_side "Engine Fuel Filter (suction side) Differential Pressure";
BA_ "SPN" SG_ 2164156928 Engine_Waste_Oil_Reservoir_Level 3548;
BA_ "SPN" SG_ 2164156928 Engine_Oil_Filter_Outlet_Pressur 3549;
BA_ "SystemSignalLongSymbol" SG_ 2164156928 Engine_Oil_Filter_Outlet_Pressur "Engine Oil-Filter Outlet Pressure";
BA_ "SPN" SG_ 2164156928 Engine_Oil_Priming_Pump_Switch 3550;
BA_ "SPN" SG_ 2164156928 Engine_Oil_Priming_State 3551;
BA_ "SPN" SG_ 2164156928 Engine_Oil_Pre_Heated_State 3552;
BA_ "SPN" SG_ 2164156928 Engine_Coolant_Pre_heated_State 3553;
BA_ "SPN" SG_ 2164156928 Engine_Ventilation_Status 3554;
BA_ "SPN" SG_ 2164156928 Fuel_Pump_Primer_Status 4083;
BA_ "SPN" SG_ 2164157184 Driver_1_identification 1625;
BA_ "SPN" SG_ 2164157184 Driver_2_identification 1626;
BA_ "SPN" SG_ 2164157440 Driver_1_working_state 1612;
BA_ "SPN" SG_ 2164157440 Driver_2_working_state 1613;
BA_ "SPN" SG_ 2164157440 Vehicle_motion 1611;
BA_ "SPN" SG_ 2164157440 Driver_1_Time_Related_States 1617;
BA_ "SPN" SG_ 2164157440 Driver_card__driver_1 1615;
BA_ "SPN" SG_ 2164157440 Vehicle_Overspeed 1614;
BA_ "SPN" SG_ 2164157440 Driver_2_Time_Related_States 1618;
BA_ "SPN" SG_ 2164157440 Driver_card__driver_2 1616;
BA_ "SPN" SG_ 2164157440 System_event 1622;
BA_ "SPN" SG_ 2164157440 Handling_information 1621;
BA_ "SPN" SG_ 2164157440 Tachograph_performance 1620;
BA_ "SPN" SG_ 2164157440 Direction_indicator 1619;
BA_ "SPN" SG_ 2164157440 Tachograph_output_shaft_speed 1623;
BA_ "SPN" SG_ 2164157440 Tachograph_vehicle_speed 1624;
BA_ "SPN" SG_ 2164157696 Auxiliary_Heater_Output_Coolant_ 1687;
BA_ "SystemSignalLongSymbol" SG_ 2164157696 Auxiliary_Heater_Output_Coolant_ "Auxiliary Heater Output Coolant Temperature";
BA_ "SPN" SG_ 2164157696 Auxiliary_Heater_Input_Air_Tempe 1688;
BA_ "SystemSignalLongSymbol" SG_ 2164157696 Auxiliary_Heater_Input_Air_Tempe "Auxiliary Heater Input Air Temperature";
BA_ "SPN" SG_ 2164157696 Auxiliary_Heater_Output_Power_Pe 1689;
BA_ "SystemSignalLongSymbol" SG_ 2164157696 Auxiliary_Heater_Output_Power_Pe "Auxiliary Heater Output Power Percent";
BA_ "SPN" SG_ 2164157696 Auxiliary_Heater_Mode 1677;
BA_ "SPN" SG_ 2164157696 Auxiliary_Heater_Water_Pump_Stat 1676;
BA_ "SystemSignalLongSymbol" SG_ 2164157696 Auxiliary_Heater_Water_Pump_Stat "Auxiliary Heater Water Pump Status";
BA_ "SPN" SG_ 2164157696 Cab_Ventilation 1678;
BA_ "SPN" SG_ 2164157696 Engine_Heating_Zone 1679;
BA_ "SPN" SG_ 2164157696 Cab_Heating_Zone 1680;
BA_ "SPN" SG_ 2164157952 Front_Axle__Left_Wheel_Speed 1592;
BA_ "SPN" SG_ 2164157952 Front_axle__right_wheel_speed 1593;
BA_ "SPN" SG_ 2164157952 Rear_axle__left_wheel_speed 1594;
BA_ "SPN" SG_ 2164157952 Rear_axle__right_wheel_speed 1595;
BA_ "SPN" SG_ 2164158208 Speed_of_forward_vehicle 1586;
BA_ "SPN" SG_ 2164158208 Distance_to_forward_vehicle 1587;
BA_ "SPN" SG_ 2164158208 Adaptive_Cruise_Control_Set_Spee 1588;
BA_ "SystemSignalLongSymbol" SG_ 2164158208 Adaptive_Cruise_Control_Set_Spee "Adaptive Cruise Control Set Speed";
BA_ "SPN" SG_ 2164158208 Adaptive_Cruise_Control_Mode 1590;
BA_ "SPN" SG_ 2164158208 Adaptive_cruise_control_set_dist 1589;
BA_ "SystemSignalLongSymbol" SG_ 2164158208 Adaptive_cruise_control_set_dist "Adaptive cruise control set distance mode";
BA_ "SPN" SG_ 2164158208 Road_curvature 1591;
BA_ "SPN" SG_ 2164158208 ACC_Target_Detected 1798;
BA_ "SPN" SG_ 2164158208 ACC_System_Shutoff_Warning 1797;
BA_ "SPN" SG_ 2164158208 ACC_Distance_Alert_Signal 1796;
BA_ "SPN" SG_ 2164158464 Powered_Vehicle_Weight 1585;
BA_ "SPN" SG_ 2164158464 Gross_Combination_Vehicle_Weight 1760;
BA_ "SPN" SG_ 2164158720 Laser_Tracer_Target_Deviation 1579;
BA_ "SPN" SG_ 2164158720 Laser_Tracer_Vertical_Distance 1580;
BA_ "SPN" SG_ 2164158720 Laser_Tracer_Horizontal_Deviatio 1581;
BA_ "SystemSignalLongSymbol" SG_ 2164158720 Laser_Tracer_Horizontal_Deviatio "Laser Tracer Horizontal Deviation";
BA_ "SPN" SG_ 2164158720 LED_Display_Data__2 1582;
BA_ "SPN" SG_ 2164158720 Laser_Tracer_Information 1583;
BA_ "SPN" SG_ 2164158976 Blade_Duration_and_Direction 1577;
BA_ "SPN" SG_ 2164158976 Blade_Control_Mode 1578;
BA_ "SPN" SG_ 2164159232 Mast_Position 1576;
BA_ "SPN" SG_ 2164159488 Modify_Leveling_System_Set_Point 1575;
BA_ "SPN" SG_ 2164159488 Blade_Height_Set_Point___High_Re 1759;
BA_ "SystemSignalLongSymbol" SG_ 2164159488 Blade_Height_Set_Point___High_Re "Blade Height Set Point - High Resolution";
BA_ "SPN" SG_ 2164159744 Laser_Strike_Vertical_Deviation 1574;
BA_ "SPN" SG_ 2164159744 Laser_Receiver_Type 2576;
BA_ "SPN" SG_ 2164159744 Laser_Strike_Data_Latency 2793;
BA_ "SPN" SG_ 2164159744 Absolute_Laser_Strike_Position 2794;
BA_ "SPN" SG_ 2164160000 LED_Display_Data__1 1573;
BA_ "SPN" SG_ 2164160000 LED_Display_Mode_Control 1805;
BA_ "SPN" SG_ 2164160000 LED_Display_Deadband_Control 1806;
BA_ "SPN" SG_ 2164160000 LED_Pattern_Control 2578;
BA_ "SPN" SG_ 2164160000 Display_Deadbands 2577;
BA_ "SPN" SG_ 2164160256 Auxiliary_Vacuum_Pressure_Readin 136;
BA_ "SystemSignalLongSymbol" SG_ 2164160256 Auxiliary_Vacuum_Pressure_Readin "Auxiliary Vacuum Pressure Reading";
BA_ "SPN" SG_ 2164160256 Auxiliary_Gage_Pressure_Reading_ 137;
BA_ "SystemSignalLongSymbol" SG_ 2164160256 Auxiliary_Gage_Pressure_Reading_ "Auxiliary Gage Pressure Reading 1";
BA_ "SPN" SG_ 2164160256 Auxiliary_Absolute_Pressure_Read 138;
BA_ "SystemSignalLongSymbol" SG_ 2164160256 Auxiliary_Absolute_Pressure_Read "Auxiliary Absolute Pressure Reading";
BA_ "SPN" SG_ 2164160512 Tire_Pressure_Check_Interval 39;
BA_ "SPN" SG_ 2164160512 Steer_Channel_Mode 1466;
BA_ "SPN" SG_ 2164160512 Trailer_tag_Channel_Mode 1467;
BA_ "SPN" SG_ 2164160512 Drive_Channel_Mode 1468;
BA_ "SPN" SG_ 2164160512 PCU_Drive_Solenoid_Status 1469;
BA_ "SPN" SG_ 2164160512 PCU_Steer_Solenoid_Status 1470;
BA_ "SPN" SG_ 2164160512 Tire_Pressure_Supply_Switch_Stat 1471;
BA_ "SystemSignalLongSymbol" SG_ 2164160512 Tire_Pressure_Supply_Switch_Stat "Tire Pressure Supply Switch Status";
BA_ "SPN" SG_ 2164160512 PCU_Deflate_Solenoid_Status 1472;
BA_ "SPN" SG_ 2164160512 PCU_Control_Solenoid_Status 1473;
BA_ "SPN" SG_ 2164160512 PCU_Supply_Solenoid_Status 1474;
BA_ "SPN" SG_ 2164160512 PCU_Trailer__Tag_or_Push_Solenoi 1475;
BA_ "SystemSignalLongSymbol" SG_ 2164160512 PCU_Trailer__Tag_or_Push_Solenoi "PCU Trailer, Tag or Push Solenoid Status";
BA_ "SPN" SG_ 2164160768 Trailer__Tag_Or_Push_Channel_Tir 141;
BA_ "SystemSignalLongSymbol" SG_ 2164160768 Trailer__Tag_Or_Push_Channel_Tir "Trailer, Tag Or Push Channel Tire Pressure Target";
BA_ "SPN" SG_ 2164160768 Drive_Channel_Tire_Pressure_Targ 142;
BA_ "SystemSignalLongSymbol" SG_ 2164160768 Drive_Channel_Tire_Pressure_Targ "Drive Channel Tire Pressure Target";
BA_ "SPN" SG_ 2164160768 Steer_Channel_Tire_Pressure_Targ 143;
BA_ "SystemSignalLongSymbol" SG_ 2164160768 Steer_Channel_Tire_Pressure_Targ "Steer Channel Tire Pressure Target";
BA_ "SPN" SG_ 2164161024 Trailer__Tag_Or_Push_Channel_Tir 144;
BA_ "SystemSignalLongSymbol" SG_ 2164161024 Trailer__Tag_Or_Push_Channel_Tir "Trailer, Tag Or Push Channel Tire Pressure";
BA_ "SPN" SG_ 2164161024 Drive_Channel_Tire_Pressure 145;
BA_ "SPN" SG_ 2164161024 Steer_Channel_Tire_Pressure 146;
BA_ "SPN" SG_ 2164161280 Engine_Cylinder__1_Combustion_Ti 1444;
BA_ "SystemSignalLongSymbol" SG_ 2164161280 Engine_Cylinder__1_Combustion_Ti "Engine Cylinder #1 Combustion Time";
BA_ "SPN" SG_ 2164161280 Engine_Cylinder__2_Combustion_Ti 1445;
BA_ "SystemSignalLongSymbol" SG_ 2164161280 Engine_Cylinder__2_Combustion_Ti "Engine Cylinder #2 Combustion Time";
BA_ "SPN" SG_ 2164161280 Engine_Cylinder__3_Combustion_Ti 1446;
BA_ "SystemSignalLongSymbol" SG_ 2164161280 Engine_Cylinder__3_Combustion_Ti "Engine Cylinder #3 Combustion Time";
BA_ "SPN" SG_ 2164161280 Engine_Cylinder__4_Combustion_Ti 1447;
BA_ "SystemSignalLongSymbol" SG_ 2164161280 Engine_Cylinder__4_Combustion_Ti "Engine Cylinder #4 Combustion Time";
BA_ "SPN" SG_ 2164161536 Engine_Cylinder__5_Combustion_Ti 1448;
BA_ "SystemSignalLongSymbol" SG_ 2164161536 Engine_Cylinder__5_Combustion_Ti "Engine Cylinder #5 Combustion Time";
BA_ "SPN" SG_ 2164161536 Engine_Cylinder__6_Combustion_Ti 1449;
BA_ "SystemSignalLongSymbol" SG_ 2164161536 Engine_Cylinder__6_Combustion_Ti "Engine Cylinder #6 Combustion Time";
BA_ "SPN" SG_ 2164161536 Engine_Cylinder__7_Combustion_Ti 1450;
BA_ "SystemSignalLongSymbol" SG_ 2164161536 Engine_Cylinder__7_Combustion_Ti "Engine Cylinder #7 Combustion Time";
BA_ "SPN" SG_ 2164161536 Engine_Cylinder__8_Combustion_Ti 1451;
BA_ "SystemSignalLongSymbol" SG_ 2164161536 Engine_Cylinder__8_Combustion_Ti "Engine Cylinder #8 Combustion Time";
BA_ "SPN" SG_ 2164161792 Engine_Cylinder__9_Combustion_Ti 1452;
BA_ "SystemSignalLongSymbol" SG_ 2164161792 Engine_Cylinder__9_Combustion_Ti "Engine Cylinder #9 Combustion Time";
BA_ "SPN" SG_ 2164161792 Engine_Cylinder__10_Combustion_T 1453;
BA_ "SystemSignalLongSymbol" SG_ 2164161792 Engine_Cylinder__10_Combustion_T "Engine Cylinder #10 Combustion Time";
BA_ "SPN" SG_ 2164161792 Engine_Cylinder__11_Combustion_T 1454;
BA_ "SystemSignalLongSymbol" SG_ 2164161792 Engine_Cylinder__11_Combustion_T "Engine Cylinder #11 Combustion Time";
BA_ "SPN" SG_ 2164161792 Engine_Cylinder__12_Combustion_T 1455;
BA_ "SystemSignalLongSymbol" SG_ 2164161792 Engine_Cylinder__12_Combustion_T "Engine Cylinder #12 Combustion Time";
BA_ "SPN" SG_ 2164162048 Engine_Cylinder__13_Combustion_T 1456;
BA_ "SystemSignalLongSymbol" SG_ 2164162048 Engine_Cylinder__13_Combustion_T "Engine Cylinder #13 Combustion Time";
BA_ "SPN" SG_ 2164162048 Engine_Cylinder__14_Combustion_T 1457;
BA_ "SystemSignalLongSymbol" SG_ 2164162048 Engine_Cylinder__14_Combustion_T "Engine Cylinder #14 Combustion Time";
BA_ "SPN" SG_ 2164162048 Engine_Cylinder__15_Combustion_T 1458;
BA_ "SystemSignalLongSymbol" SG_ 2164162048 Engine_Cylinder__15_Combustion_T "Engine Cylinder #15 Combustion Time";
BA_ "SPN" SG_ 2164162048 Engine_Cylinder__16_Combustion_T 1459;
BA_ "SystemSignalLongSymbol" SG_ 2164162048 Engine_Cylinder__16_Combustion_T "Engine Cylinder #16 Combustion Time";
BA_ "SPN" SG_ 2164162304 Engine_Cylinder__17_Combustion_T 1460;
BA_ "SystemSignalLongSymbol" SG_ 2164162304 Engine_Cylinder__17_Combustion_T "Engine Cylinder #17 Combustion Time";
BA_ "SPN" SG_ 2164162304 Engine_Cylinder__18_Combustion_T 1461;
BA_ "SystemSignalLongSymbol" SG_ 2164162304 Engine_Cylinder__18_Combustion_T "Engine Cylinder #18 Combustion Time";
BA_ "SPN" SG_ 2164162304 Engine_Cylinder__19_Combustion_T 1462;
BA_ "SystemSignalLongSymbol" SG_ 2164162304 Engine_Cylinder__19_Combustion_T "Engine Cylinder #19 Combustion Time";
BA_ "SPN" SG_ 2164162304 Engine_Cylinder__20_Combustion_T 1463;
BA_ "SystemSignalLongSymbol" SG_ 2164162304 Engine_Cylinder__20_Combustion_T "Engine Cylinder #20 Combustion Time";
BA_ "SPN" SG_ 2164162560 Engine_Desired_Combustion_Time 1464;
BA_ "SPN" SG_ 2164162560 Engine_Average_Combustion_Time 1465;
BA_ "SPN" SG_ 2164162816 Engine_Fuel_Flow_Rate_1 1440;
BA_ "SPN" SG_ 2164162816 Engine_Fuel_Flow_Rate_2 1441;
BA_ "SPN" SG_ 2164162816 Engine_Fuel_Valve_1_Position 1442;
BA_ "SPN" SG_ 2164162816 Engine_Fuel_Valve_2_Position 1443;
BA_ "SPN" SG_ 2164162816 Engine_Requested_Fuel_Valve_1_Po 1765;
BA_ "SystemSignalLongSymbol" SG_ 2164162816 Engine_Requested_Fuel_Valve_1_Po "Engine Requested Fuel Valve 1 Position";
BA_ "SPN" SG_ 2164162816 Engine_Requested_Fuel_Valve_2_Po 1766;
BA_ "SystemSignalLongSymbol" SG_ 2164162816 Engine_Requested_Fuel_Valve_2_Po "Engine Requested Fuel Valve 2 Position";
BA_ "SPN" SG_ 2164163072 Engine_Cylinder__1_Ignition_Timi 1413;
BA_ "SystemSignalLongSymbol" SG_ 2164163072 Engine_Cylinder__1_Ignition_Timi "Engine Cylinder #1 Ignition Timing";
BA_ "SPN" SG_ 2164163072 Engine_Cylinder__2_Ignition_Timi 1414;
BA_ "SystemSignalLongSymbol" SG_ 2164163072 Engine_Cylinder__2_Ignition_Timi "Engine Cylinder #2 Ignition Timing";
BA_ "SPN" SG_ 2164163072 Engine_Cylinder__3_Ignition_Timi 1415;
BA_ "SystemSignalLongSymbol" SG_ 2164163072 Engine_Cylinder__3_Ignition_Timi "Engine Cylinder #3 Ignition Timing";
BA_ "SPN" SG_ 2164163072 Engine_Cylinder__4_Ignition_Timi 1416;
BA_ "SystemSignalLongSymbol" SG_ 2164163072 Engine_Cylinder__4_Ignition_Timi "Engine Cylinder #4 Ignition Timing";
BA_ "SPN" SG_ 2164163328 Engine_Cylinder__5_Ignition_Timi 1417;
BA_ "SystemSignalLongSymbol" SG_ 2164163328 Engine_Cylinder__5_Ignition_Timi "Engine Cylinder #5 Ignition Timing";
BA_ "SPN" SG_ 2164163328 Engine_Cylinder__6_Ignition_Timi 1418;
BA_ "SystemSignalLongSymbol" SG_ 2164163328 Engine_Cylinder__6_Ignition_Timi "Engine Cylinder #6 Ignition Timing";
BA_ "SPN" SG_ 2164163328 Engine_Cylinder__7_Ignition_Timi 1419;
BA_ "SystemSignalLongSymbol" SG_ 2164163328 Engine_Cylinder__7_Ignition_Timi "Engine Cylinder #7 Ignition Timing";
BA_ "SPN" SG_ 2164163328 Engine_Cylinder__8_Ignition_Timi 1420;
BA_ "SystemSignalLongSymbol" SG_ 2164163328 Engine_Cylinder__8_Ignition_Timi "Engine Cylinder #8 Ignition Timing";
BA_ "SPN" SG_ 2164163584 Engine_Cylinder__9_Ignition_Timi 1421;
BA_ "SystemSignalLongSymbol" SG_ 2164163584 Engine_Cylinder__9_Ignition_Timi "Engine Cylinder #9 Ignition Timing";
BA_ "SPN" SG_ 2164163584 Engine_Cylinder__10_Ignition_Tim 1422;
BA_ "SystemSignalLongSymbol" SG_ 2164163584 Engine_Cylinder__10_Ignition_Tim "Engine Cylinder #10 Ignition Timing";
BA_ "SPN" SG_ 2164163584 Engine_Cylinder__11_Ignition_Tim 1423;
BA_ "SystemSignalLongSymbol" SG_ 2164163584 Engine_Cylinder__11_Ignition_Tim "Engine Cylinder #11 Ignition Timing";
BA_ "SPN" SG_ 2164163584 Engine_Cylinder__12_Ignition_Tim 1424;
BA_ "SystemSignalLongSymbol" SG_ 2164163584 Engine_Cylinder__12_Ignition_Tim "Engine Cylinder #12 Ignition Timing";
BA_ "SPN" SG_ 2164163840 Engine_Cylinder__13_Ignition_Tim 1425;
BA_ "SystemSignalLongSymbol" SG_ 2164163840 Engine_Cylinder__13_Ignition_Tim "Engine Cylinder #13 Ignition Timing";
BA_ "SPN" SG_ 2164163840 Engine_Cylinder__14_Ignition_Tim 1426;
BA_ "SystemSignalLongSymbol" SG_ 2164163840 Engine_Cylinder__14_Ignition_Tim "Engine Cylinder #14 Ignition Timing";
BA_ "SPN" SG_ 2164163840 Engine_Cylinder__15_Ignition_Tim 1427;
BA_ "SystemSignalLongSymbol" SG_ 2164163840 Engine_Cylinder__15_Ignition_Tim "Engine Cylinder #15 Ignition Timing";
BA_ "SPN" SG_ 2164163840 Engine_Cylinder__16_Ignition_Tim 1428;
BA_ "SystemSignalLongSymbol" SG_ 2164163840 Engine_Cylinder__16_Ignition_Tim "Engine Cylinder #16 Ignition Timing";
BA_ "SPN" SG_ 2164164096 Engine_Cylinder__17_Ignition_Tim 1429;
BA_ "SystemSignalLongSymbol" SG_ 2164164096 Engine_Cylinder__17_Ignition_Tim "Engine Cylinder #17 Ignition Timing";
BA_ "SPN" SG_ 2164164096 Engine_Cylinder__18_Ignition_Tim 1430;
BA_ "SystemSignalLongSymbol" SG_ 2164164096 Engine_Cylinder__18_Ignition_Tim "Engine Cylinder #18 Ignition Timing";
BA_ "SPN" SG_ 2164164096 Engine_Cylinder__19_Ignition_Tim 1431;
BA_ "SystemSignalLongSymbol" SG_ 2164164096 Engine_Cylinder__19_Ignition_Tim "Engine Cylinder #19 Ignition Timing";
BA_ "SPN" SG_ 2164164096 Engine_Cylinder__20_Ignition_Tim 1432;
BA_ "SystemSignalLongSymbol" SG_ 2164164096 Engine_Cylinder__20_Ignition_Tim "Engine Cylinder #20 Ignition Timing";
BA_ "SPN" SG_ 2164164352 Engine_Desired_Ignition_Timing__0 1435;
BA_ "SystemSignalLongSymbol" SG_ 2164164352 Engine_Desired_Ignition_Timing__0 "Engine Desired Ignition Timing #3";
BA_ "SPN" SG_ 2164164352 Engine_Actual_Ignition_Timing 1436;
BA_ "SPN" SG_ 2164164608 Engine_Cylinder__1_Ignition_Tran 1393;
BA_ "SystemSignalLongSymbol" SG_ 2164164608 Engine_Cylinder__1_Ignition_Tran "Engine Cylinder #1 Ignition Transformer Secondary Output";
BA_ "SPN" SG_ 2164164608 Engine_Cylinder__2_Ignition_Tran 1394;
BA_ "SystemSignalLongSymbol" SG_ 2164164608 Engine_Cylinder__2_Ignition_Tran "Engine Cylinder #2 Ignition Transformer Secondary Output";
BA_ "SPN" SG_ 2164164608 Engine_Cylinder__3_Ignition_Tran 1395;
BA_ "SystemSignalLongSymbol" SG_ 2164164608 Engine_Cylinder__3_Ignition_Tran "Engine Cylinder #3 Ignition Transformer Secondary Output";
BA_ "SPN" SG_ 2164164608 Engine_Cylinder__4_Ignition_Tran 1396;
BA_ "SystemSignalLongSymbol" SG_ 2164164608 Engine_Cylinder__4_Ignition_Tran "Engine Cylinder #4 Ignition Transformer Secondary Output";
BA_ "SPN" SG_ 2164164608 Engine_Cylinder__5_Ignition_Tran 1397;
BA_ "SystemSignalLongSymbol" SG_ 2164164608 Engine_Cylinder__5_Ignition_Tran "Engine Cylinder #5 Ignition Transformer Secondary Output";
BA_ "SPN" SG_ 2164164608 Engine_Cylinder__6_Ignition_Tran 1398;
BA_ "SystemSignalLongSymbol" SG_ 2164164608 Engine_Cylinder__6_Ignition_Tran "Engine Cylinder #6 Ignition Transformer Secondary Output";
BA_ "SPN" SG_ 2164164608 Engine_Cylinder__7_Ignition_Tran 1399;
BA_ "SystemSignalLongSymbol" SG_ 2164164608 Engine_Cylinder__7_Ignition_Tran "Engine Cylinder #7 Ignition Transformer Secondary Output";
BA_ "SPN" SG_ 2164164608 Engine_Cylinder__8_Ignition_Tran 1400;
BA_ "SystemSignalLongSymbol" SG_ 2164164608 Engine_Cylinder__8_Ignition_Tran "Engine Cylinder #8 Ignition Transformer Secondary Output";
BA_ "SPN" SG_ 2164164864 Engine_Cylinder__9_Ignition_Tran 1401;
BA_ "SystemSignalLongSymbol" SG_ 2164164864 Engine_Cylinder__9_Ignition_Tran "Engine Cylinder #9 Ignition Transformer Secondary Output";
BA_ "SPN" SG_ 2164164864 Engine_Cylinder__10_Ignition_Tra 1402;
BA_ "SystemSignalLongSymbol" SG_ 2164164864 Engine_Cylinder__10_Ignition_Tra "Engine Cylinder #10 Ignition Transformer Secondary Output";
BA_ "SPN" SG_ 2164164864 Engine_Cylinder__11_Ignition_Tra 1403;
BA_ "SystemSignalLongSymbol" SG_ 2164164864 Engine_Cylinder__11_Ignition_Tra "Engine Cylinder #11 Ignition Transformer Secondary Output";
BA_ "SPN" SG_ 2164164864 Engine_Cylinder__12_Ignition_Tra 1404;
BA_ "SystemSignalLongSymbol" SG_ 2164164864 Engine_Cylinder__12_Ignition_Tra "Engine Cylinder #12 Ignition Transformer Secondary Output";
BA_ "SPN" SG_ 2164164864 Engine_Cylinder__13_Ignition_Tra 1405;
BA_ "SystemSignalLongSymbol" SG_ 2164164864 Engine_Cylinder__13_Ignition_Tra "Engine Cylinder #13 Ignition Transformer Secondary Output";
BA_ "SPN" SG_ 2164164864 Engine_Cylinder__14_Ignition_Tra 1406;
BA_ "SystemSignalLongSymbol" SG_ 2164164864 Engine_Cylinder__14_Ignition_Tra "Engine Cylinder #14 Ignition Transformer Secondary Output";
BA_ "SPN" SG_ 2164164864 Engine_Cylinder__15_Ignition_Tra 1407;
BA_ "SystemSignalLongSymbol" SG_ 2164164864 Engine_Cylinder__15_Ignition_Tra "Engine Cylinder #15 Ignition Transformer Secondary Output";
BA_ "SPN" SG_ 2164164864 Engine_Cylinder__16_Ignition_Tra 1408;
BA_ "SystemSignalLongSymbol" SG_ 2164164864 Engine_Cylinder__16_Ignition_Tra "Engine Cylinder #16 Ignition Transformer Secondary Output";
BA_ "SPN" SG_ 2164165120 Engine_Cylinder__17_Ignition_Tra 1409;
BA_ "SystemSignalLongSymbol" SG_ 2164165120 Engine_Cylinder__17_Ignition_Tra "Engine Cylinder #17 Ignition Transformer Secondary Output";
BA_ "SPN" SG_ 2164165120 Engine_Cylinder__18_Ignition_Tra 1410;
BA_ "SystemSignalLongSymbol" SG_ 2164165120 Engine_Cylinder__18_Ignition_Tra "Engine Cylinder #18 Ignition Transformer Secondary Output";
BA_ "SPN" SG_ 2164165120 Engine_Cylinder__19_Ignition_Tra 1411;
BA_ "SystemSignalLongSymbol" SG_ 2164165120 Engine_Cylinder__19_Ignition_Tra "Engine Cylinder #19 Ignition Transformer Secondary Output";
BA_ "SPN" SG_ 2164165120 Engine_Cylinder__20_Ignition_Tra 1412;
BA_ "SystemSignalLongSymbol" SG_ 2164165120 Engine_Cylinder__20_Ignition_Tra "Engine Cylinder #20 Ignition Transformer Secondary Output";
BA_ "SPN" SG_ 2164165376 Engine_Fuel_Valve_1_Inlet_Absolu 1390;
BA_ "SystemSignalLongSymbol" SG_ 2164165376 Engine_Fuel_Valve_1_Inlet_Absolu "Engine Fuel Valve 1 Inlet Absolute Pressure";
BA_ "SPN" SG_ 2164165376 Engine_Fuel_Valve_Differential_P 1391;
BA_ "SystemSignalLongSymbol" SG_ 2164165376 Engine_Fuel_Valve_Differential_P "Engine Fuel Valve Differential Pressure";
BA_ "SPN" SG_ 2164165376 Engine_Air_to_Fuel_Differential_ 1392;
BA_ "SystemSignalLongSymbol" SG_ 2164165376 Engine_Air_to_Fuel_Differential_ "Engine Air to Fuel Differential Pressure";
BA_ "SPN" SG_ 2164165376 Engine_Fuel_Valve_1_Outlet_Abso 2980;
BA_ "SystemSignalLongSymbol" SG_ 2164165376 Engine_Fuel_Valve_1_Outlet_Abso "Engine Fuel  Valve 1 Outlet Absolute Pressure";
BA_ "SPN" SG_ 2164165632 Auxiliary_Temperature_1 441;
BA_ "SPN" SG_ 2164165632 Auxiliary_Temperature_2 442;
BA_ "SPN" SG_ 2164165632 Auxiliary_Pressure__1 1387;
BA_ "SPN" SG_ 2164165632 Auxiliary_Pressure__2 1388;
BA_ "SPN" SG_ 2164165632 Auxiliary_Level 3087;
BA_ "SPN" SG_ 2164165632 Relative_Humidity 354;
BA_ "SPN" SG_ 2164165888 Battery_Potential___Power_Input_ 444;
BA_ "SystemSignalLongSymbol" SG_ 2164165888 Battery_Potential___Power_Input_ "Battery Potential / Power Input 2";
BA_ "SPN" SG_ 2164165888 ECU_Power_Output_Supply_Voltage_0 3597;
BA_ "SystemSignalLongSymbol" SG_ 2164165888 ECU_Power_Output_Supply_Voltage_0 "ECU Power Output Supply Voltage #1";
BA_ "SPN" SG_ 2164165888 ECU_Power_Output_Supply_Voltage_1 3598;
BA_ "SystemSignalLongSymbol" SG_ 2164165888 ECU_Power_Output_Supply_Voltage_1 "ECU Power Output Supply Voltage #2";
BA_ "SPN" SG_ 2164165888 ECU_Power_Output_Supply_Voltage_2 3599;
BA_ "SystemSignalLongSymbol" SG_ 2164165888 ECU_Power_Output_Supply_Voltage_2 "ECU Power Output Supply Voltage #3";
BA_ "SPN" SG_ 2164166144 Service_Component_Identification 1379;
BA_ "SPN" SG_ 2164166144 Time_Since_Last_Service 1350;
BA_ "SPN" SG_ 2164166400 Engine_External_Shutdown_Air_Sup 1320;
BA_ "SystemSignalLongSymbol" SG_ 2164166400 Engine_External_Shutdown_Air_Sup "Engine External Shutdown Air Supply Pressure";
BA_ "SPN" SG_ 2164166656 Number_of_Engine_Torque_History_ 1246;
BA_ "SystemSignalLongSymbol" SG_ 2164166656 Number_of_Engine_Torque_History_ "Number of Engine Torque History Records";
BA_ "SPN" SG_ 2164166656 Engine_Power 1247;
BA_ "SPN" SG_ 2164166656 Engine_Peak_Torque_1 1248;
BA_ "SPN" SG_ 2164166656 Engine_Peak_Torque_2 1249;
BA_ "SPN" SG_ 2164166656 Calibration_Record_Start_Month 1250;
BA_ "SPN" SG_ 2164166656 Calibration_Record_Start_Day 1251;
BA_ "SPN" SG_ 2164166656 Calibration_Record_Start_Year 1252;
BA_ "SPN" SG_ 2164166656 Calibration_Record_Duration_Time 1253;
BA_ "SPN" SG_ 2164166656 Torque_Limiting_Feature_Status 1254;
BA_ "SPN" SG_ 2164166656 Engine_Torque_Limit_Feature 1632;
BA_ "SPN" SG_ 2164166656 Transmission_Gear_Ratio_1 1255;
BA_ "SPN" SG_ 2164166656 Engine_Torque_Limit_1__Transmiss 1256;
BA_ "SystemSignalLongSymbol" SG_ 2164166656 Engine_Torque_Limit_1__Transmiss "Engine Torque Limit 1, Transmission";
BA_ "SPN" SG_ 2164166656 Transmission_Gear_Ratio_2 1257;
BA_ "SPN" SG_ 2164166656 Engine_Torque_Limit_2__Transmiss 1258;
BA_ "SystemSignalLongSymbol" SG_ 2164166656 Engine_Torque_Limit_2__Transmiss "Engine Torque Limit 2, Transmission";
BA_ "SPN" SG_ 2164166656 Transmission_Gear_Ratio_3 1259;
BA_ "SPN" SG_ 2164166656 Engine_Torque_Limit_3__Transmiss 1260;
BA_ "SystemSignalLongSymbol" SG_ 2164166656 Engine_Torque_Limit_3__Transmiss "Engine Torque Limit 3, Transmission";
BA_ "SPN" SG_ 2164166656 Engine_Torque_Limit_4__Transmiss 1261;
BA_ "SystemSignalLongSymbol" SG_ 2164166656 Engine_Torque_Limit_4__Transmiss "Engine Torque Limit 4, Transmission";
BA_ "SPN" SG_ 2164166656 Engine_Torque_Limit_5__Switch 1262;
BA_ "SPN" SG_ 2164166656 Engine_Torque_Limit_6__Axle_Inpu 1263;
BA_ "SystemSignalLongSymbol" SG_ 2164166656 Engine_Torque_Limit_6__Axle_Inpu "Engine Torque Limit 6, Axle Input";
BA_ "SPN" SG_ 2164166912 Engine_Fuel_Leakage_1 1239;
BA_ "SPN" SG_ 2164166912 Engine_Fuel_Leakage_2 1240;
BA_ "SPN" SG_ 2164167168 Engine_Pre_filter_Oil_Pressure 1208;
BA_ "SPN" SG_ 2164167168 Engine_Exhaust_Gas_Pressure 1209;
BA_ "SPN" SG_ 2164167168 Engine_Fuel_Rack_Position 1210;
BA_ "SPN" SG_ 2164167168 Engine_Gas_Mass_Flow_Rate_1 1241;
BA_ "SPN" SG_ 2164167168 Instantaneous_Estimated_Brake_Po 1242;
BA_ "SystemSignalLongSymbol" SG_ 2164167168 Instantaneous_Estimated_Brake_Po "Instantaneous Estimated Brake Power";
BA_ "SPN" SG_ 2164167424 Electrical_Load 1204;
BA_ "SPN" SG_ 2164167424 Safety_Wire_Status 1205;
BA_ "SPN" SG_ 2164167680 Engine_Auxiliary_Coolant_Pressur 1203;
BA_ "SystemSignalLongSymbol" SG_ 2164167680 Engine_Auxiliary_Coolant_Pressur "Engine Auxiliary Coolant Pressure";
BA_ "SPN" SG_ 2164167680 Engine_Auxiliary_Coolant_Tempera 1212;
BA_ "SystemSignalLongSymbol" SG_ 2164167680 Engine_Auxiliary_Coolant_Tempera "Engine Auxiliary Coolant Temperature";
BA_ "SPN" SG_ 2164167680 Sea_Water_Pump_Outlet_Pressure 2435;
BA_ "SPN" SG_ 2164167936 Engine_Operation_Time_Since_Rebu 1193;
BA_ "SystemSignalLongSymbol" SG_ 2164167936 Engine_Operation_Time_Since_Rebu "Engine Operation Time Since Rebuild";
BA_ "SPN" SG_ 2164168192 Engine_Turbocharger_1_Wastegate_ 1188;
BA_ "SystemSignalLongSymbol" SG_ 2164168192 Engine_Turbocharger_1_Wastegate_ "Engine Turbocharger 1 Wastegate Drive";
BA_ "SPN" SG_ 2164168192 Engine_Turbocharger_2_Wastegate_ 1189;
BA_ "SystemSignalLongSymbol" SG_ 2164168192 Engine_Turbocharger_2_Wastegate_ "Engine Turbocharger 2 Wastegate Drive";
BA_ "SPN" SG_ 2164168192 Engine_Turbocharger_3_Wastegate_ 1190;
BA_ "SystemSignalLongSymbol" SG_ 2164168192 Engine_Turbocharger_3_Wastegate_ "Engine Turbocharger 3 Wastegate Drive";
BA_ "SPN" SG_ 2164168192 Engine_Turbocharger_4_Wastegate_ 1191;
BA_ "SystemSignalLongSymbol" SG_ 2164168192 Engine_Turbocharger_4_Wastegate_ "Engine Turbocharger 4 Wastegate Drive";
BA_ "SPN" SG_ 2164168192 Engine_Turbocharger_Wastegate_Ac 1192;
BA_ "SystemSignalLongSymbol" SG_ 2164168192 Engine_Turbocharger_Wastegate_Ac "Engine Turbocharger Wastegate Actuator Control Air Pressure";
BA_ "SPN" SG_ 2164168448 Engine_Turbocharger_1_Turbine_Ou 1184;
BA_ "SystemSignalLongSymbol" SG_ 2164168448 Engine_Turbocharger_1_Turbine_Ou "Engine Turbocharger 1 Turbine Outlet Temperature";
BA_ "SPN" SG_ 2164168448 Engine_Turbocharger_2_Turbine_Ou 1185;
BA_ "SystemSignalLongSymbol" SG_ 2164168448 Engine_Turbocharger_2_Turbine_Ou "Engine Turbocharger 2 Turbine Outlet Temperature";
BA_ "SPN" SG_ 2164168448 Engine_Turbocharger_3_Turbine_Ou 1186;
BA_ "SystemSignalLongSymbol" SG_ 2164168448 Engine_Turbocharger_3_Turbine_Ou "Engine Turbocharger 3 Turbine Outlet Temperature";
BA_ "SPN" SG_ 2164168448 Engine_Turbocharger_4_Turbine_Ou 1187;
BA_ "SystemSignalLongSymbol" SG_ 2164168448 Engine_Turbocharger_4_Turbine_Ou "Engine Turbocharger 4 Turbine Outlet Temperature";
BA_ "SPN" SG_ 2164168704 Engine_Turbocharger_1_Turbine_In 1180;
BA_ "SystemSignalLongSymbol" SG_ 2164168704 Engine_Turbocharger_1_Turbine_In "Engine Turbocharger 1 Turbine Inlet Temperature";
BA_ "SPN" SG_ 2164168704 Engine_Turbocharger_2_Turbine_In 1181;
BA_ "SystemSignalLongSymbol" SG_ 2164168704 Engine_Turbocharger_2_Turbine_In "Engine Turbocharger 2 Turbine Inlet Temperature";
BA_ "SPN" SG_ 2164168704 Engine_Turbocharger_3_Turbine_In 1182;
BA_ "SystemSignalLongSymbol" SG_ 2164168704 Engine_Turbocharger_3_Turbine_In "Engine Turbocharger 3 Turbine Inlet Temperature";
BA_ "SPN" SG_ 2164168704 Engine_Turbocharger_4_Turbine_In 1183;
BA_ "SystemSignalLongSymbol" SG_ 2164168704 Engine_Turbocharger_4_Turbine_In "Engine Turbocharger 4 Turbine Inlet Temperature";
BA_ "SPN" SG_ 2164168960 Engine_Turbocharger_1_Compressor 1176;
BA_ "SystemSignalLongSymbol" SG_ 2164168960 Engine_Turbocharger_1_Compressor "Engine Turbocharger 1 Compressor Inlet Pressure";
BA_ "SPN" SG_ 2164168960 Engine_Turbocharger_2_Compressor 1177;
BA_ "SystemSignalLongSymbol" SG_ 2164168960 Engine_Turbocharger_2_Compressor "Engine Turbocharger 2 Compressor Inlet Pressure";
BA_ "SPN" SG_ 2164168960 Engine_Turbocharger_3_Compressor 1178;
BA_ "SystemSignalLongSymbol" SG_ 2164168960 Engine_Turbocharger_3_Compressor "Engine Turbocharger 3 Compressor Inlet Pressure";
BA_ "SPN" SG_ 2164168960 Engine_Turbocharger_4_Compressor 1179;
BA_ "SystemSignalLongSymbol" SG_ 2164168960 Engine_Turbocharger_4_Compressor "Engine Turbocharger 4 Compressor Inlet Pressure";
BA_ "SPN" SG_ 2164169216 Engine_Turbocharger_1_Compressor 1172;
BA_ "SystemSignalLongSymbol" SG_ 2164169216 Engine_Turbocharger_1_Compressor "Engine Turbocharger 1 Compressor Inlet Temperature";
BA_ "SPN" SG_ 2164169216 Engine_Turbocharger_2_Compressor 1173;
BA_ "SystemSignalLongSymbol" SG_ 2164169216 Engine_Turbocharger_2_Compressor "Engine Turbocharger 2 Compressor Inlet Temperature";
BA_ "SPN" SG_ 2164169216 Engine_Turbocharger_3_Compressor 1174;
BA_ "SystemSignalLongSymbol" SG_ 2164169216 Engine_Turbocharger_3_Compressor "Engine Turbocharger 3 Compressor Inlet Temperature";
BA_ "SPN" SG_ 2164169216 Engine_Turbocharger_4_Compressor 1175;
BA_ "SystemSignalLongSymbol" SG_ 2164169216 Engine_Turbocharger_4_Compressor "Engine Turbocharger 4 Compressor Inlet Temperature";
BA_ "SPN" SG_ 2164169472 Engine_Turbocharger_Lube_Oil_Pre 1168;
BA_ "SystemSignalLongSymbol" SG_ 2164169472 Engine_Turbocharger_Lube_Oil_Pre "Engine Turbocharger Lube Oil Pressure 2";
BA_ "SPN" SG_ 2164169472 Engine_Turbocharger_2_Speed 1169;
BA_ "SPN" SG_ 2164169472 Engine_Turbocharger_3_Speed 1170;
BA_ "SPN" SG_ 2164169472 Engine_Turbocharger_4_Speed 1171;
BA_ "SPN" SG_ 2164169728 Engine_Main_Bearing_9_Temperatur 1165;
BA_ "SystemSignalLongSymbol" SG_ 2164169728 Engine_Main_Bearing_9_Temperatur "Engine Main Bearing 9 Temperature";
BA_ "SPN" SG_ 2164169728 Engine_Main_Bearing_10_Temperatu 1166;
BA_ "SystemSignalLongSymbol" SG_ 2164169728 Engine_Main_Bearing_10_Temperatu "Engine Main Bearing 10 Temperature";
BA_ "SPN" SG_ 2164169728 Engine_Main_Bearing_11_Temperatu 1167;
BA_ "SystemSignalLongSymbol" SG_ 2164169728 Engine_Main_Bearing_11_Temperatu "Engine Main Bearing 11 Temperature";
BA_ "SPN" SG_ 2164169984 Engine_Main_Bearing_5_Temperatur 1161;
BA_ "SystemSignalLongSymbol" SG_ 2164169984 Engine_Main_Bearing_5_Temperatur "Engine Main Bearing 5 Temperature";
BA_ "SPN" SG_ 2164169984 Engine_Main_Bearing_6_Temperatur 1162;
BA_ "SystemSignalLongSymbol" SG_ 2164169984 Engine_Main_Bearing_6_Temperatur "Engine Main Bearing 6 Temperature";
BA_ "SPN" SG_ 2164169984 Engine_Main_Bearing_7_Temperatur 1163;
BA_ "SystemSignalLongSymbol" SG_ 2164169984 Engine_Main_Bearing_7_Temperatur "Engine Main Bearing 7 Temperature";
BA_ "SPN" SG_ 2164169984 Engine_Main_Bearing_8_Temperatur 1164;
BA_ "SystemSignalLongSymbol" SG_ 2164169984 Engine_Main_Bearing_8_Temperatur "Engine Main Bearing 8 Temperature";
BA_ "SPN" SG_ 2164170240 Engine_Main_Bearing_1_Temperatur 1157;
BA_ "SystemSignalLongSymbol" SG_ 2164170240 Engine_Main_Bearing_1_Temperatur "Engine Main Bearing 1 Temperature";
BA_ "SPN" SG_ 2164170240 Engine_Main_Bearing_2_Temperatur 1158;
BA_ "SystemSignalLongSymbol" SG_ 2164170240 Engine_Main_Bearing_2_Temperatur "Engine Main Bearing 2 Temperature";
BA_ "SPN" SG_ 2164170240 Engine_Main_Bearing_3_Temperatur 1159;
BA_ "SystemSignalLongSymbol" SG_ 2164170240 Engine_Main_Bearing_3_Temperatur "Engine Main Bearing 3 Temperature";
BA_ "SPN" SG_ 2164170240 Engine_Main_Bearing_4_Temperatur 1160;
BA_ "SystemSignalLongSymbol" SG_ 2164170240 Engine_Main_Bearing_4_Temperatur "Engine Main Bearing 4 Temperature";
BA_ "SPN" SG_ 2164170496 Engine_Exhaust_Gas_Port_17_Tempe 1153;
BA_ "SystemSignalLongSymbol" SG_ 2164170496 Engine_Exhaust_Gas_Port_17_Tempe "Engine Exhaust Gas Port 17 Temperature";
BA_ "SPN" SG_ 2164170496 Engine_Exhaust_Gas_Port_18_Tempe 1154;
BA_ "SystemSignalLongSymbol" SG_ 2164170496 Engine_Exhaust_Gas_Port_18_Tempe "Engine Exhaust Gas Port 18 Temperature";
BA_ "SPN" SG_ 2164170496 Engine_Exhaust_Gas_Port_19_Tempe 1155;
BA_ "SystemSignalLongSymbol" SG_ 2164170496 Engine_Exhaust_Gas_Port_19_Tempe "Engine Exhaust Gas Port 19 Temperature";
BA_ "SPN" SG_ 2164170496 Engine_Exhaust_Gas_Port_20_Tempe 1156;
BA_ "SystemSignalLongSymbol" SG_ 2164170496 Engine_Exhaust_Gas_Port_20_Tempe "Engine Exhaust Gas Port 20 Temperature";
BA_ "SPN" SG_ 2164170752 Engine_Exhaust_Gas_Port_13_Tempe 1149;
BA_ "SystemSignalLongSymbol" SG_ 2164170752 Engine_Exhaust_Gas_Port_13_Tempe "Engine Exhaust Gas Port 13 Temperature";
BA_ "SPN" SG_ 2164170752 Engine_Exhaust_Gas_Port_14_Tempe 1150;
BA_ "SystemSignalLongSymbol" SG_ 2164170752 Engine_Exhaust_Gas_Port_14_Tempe "Engine Exhaust Gas Port 14 Temperature";
BA_ "SPN" SG_ 2164170752 Engine_Exhaust_Gas_Port_15_Tempe 1151;
BA_ "SystemSignalLongSymbol" SG_ 2164170752 Engine_Exhaust_Gas_Port_15_Tempe "Engine Exhaust Gas Port 15 Temperature";
BA_ "SPN" SG_ 2164170752 Engine_Exhaust_Gas_Port_16_Tempe 1152;
BA_ "SystemSignalLongSymbol" SG_ 2164170752 Engine_Exhaust_Gas_Port_16_Tempe "Engine Exhaust Gas Port 16 Temperature";
BA_ "SPN" SG_ 2164171008 Engine_Exhaust_Gas_Port_9_Temper 1145;
BA_ "SystemSignalLongSymbol" SG_ 2164171008 Engine_Exhaust_Gas_Port_9_Temper "Engine Exhaust Gas Port 9 Temperature";
BA_ "SPN" SG_ 2164171008 Engine_Exhaust_Gas_Port_10_Tempe 1146;
BA_ "SystemSignalLongSymbol" SG_ 2164171008 Engine_Exhaust_Gas_Port_10_Tempe "Engine Exhaust Gas Port 10 Temperature";
BA_ "SPN" SG_ 2164171008 Engine_Exhaust_Gas_Port_11_Tempe 1147;
BA_ "SystemSignalLongSymbol" SG_ 2164171008 Engine_Exhaust_Gas_Port_11_Tempe "Engine Exhaust Gas Port 11 Temperature";
BA_ "SPN" SG_ 2164171008 Engine_Exhaust_Gas_Port_12_Tempe 1148;
BA_ "SystemSignalLongSymbol" SG_ 2164171008 Engine_Exhaust_Gas_Port_12_Tempe "Engine Exhaust Gas Port 12 Temperature";
BA_ "SPN" SG_ 2164171264 Engine_Exhaust_Gas_Port_5_Temper 1141;
BA_ "SystemSignalLongSymbol" SG_ 2164171264 Engine_Exhaust_Gas_Port_5_Temper "Engine Exhaust Gas Port 5 Temperature";
BA_ "SPN" SG_ 2164171264 Engine_Exhaust_Gas_Port_6_Temper 1142;
BA_ "SystemSignalLongSymbol" SG_ 2164171264 Engine_Exhaust_Gas_Port_6_Temper "Engine Exhaust Gas Port 6 Temperature";
BA_ "SPN" SG_ 2164171264 Engine_Exhaust_Gas_Port_7_Temper 1143;
BA_ "SystemSignalLongSymbol" SG_ 2164171264 Engine_Exhaust_Gas_Port_7_Temper "Engine Exhaust Gas Port 7 Temperature";
BA_ "SPN" SG_ 2164171264 Engine_Exhaust_Gas_Port_8_Temper 1144;
BA_ "SystemSignalLongSymbol" SG_ 2164171264 Engine_Exhaust_Gas_Port_8_Temper "Engine Exhaust Gas Port 8 Temperature";
BA_ "SPN" SG_ 2164171520 Engine_Exhaust_Gas_Port_1_Temper 1137;
BA_ "SystemSignalLongSymbol" SG_ 2164171520 Engine_Exhaust_Gas_Port_1_Temper "Engine Exhaust Gas Port 1 Temperature";
BA_ "SPN" SG_ 2164171520 Engine_Exhaust_Gas_Port_2_Temper 1138;
BA_ "SystemSignalLongSymbol" SG_ 2164171520 Engine_Exhaust_Gas_Port_2_Temper "Engine Exhaust Gas Port 2 Temperature";
BA_ "SPN" SG_ 2164171520 Engine_Exhaust_Gas_Port_3_Temper 1139;
BA_ "SystemSignalLongSymbol" SG_ 2164171520 Engine_Exhaust_Gas_Port_3_Temper "Engine Exhaust Gas Port 3 Temperature";
BA_ "SPN" SG_ 2164171520 Engine_Exhaust_Gas_Port_4_Temper 1140;
BA_ "SystemSignalLongSymbol" SG_ 2164171520 Engine_Exhaust_Gas_Port_4_Temper "Engine Exhaust Gas Port 4 Temperature";
BA_ "SPN" SG_ 2164171776 Engine_Oil_Temperature_2 1135;
BA_ "SPN" SG_ 2164171776 Engine_ECU_Temperature 1136;
BA_ "SPN" SG_ 2164171776 Engine_Exhaust_Gas_Recirculation0 411;
BA_ "SystemSignalLongSymbol" SG_ 2164171776 Engine_Exhaust_Gas_Recirculation0 "Engine Exhaust Gas Recirculation Differential Pressure";
BA_ "SPN" SG_ 2164171776 Engine_Exhaust_Gas_Recirculation1 412;
BA_ "SystemSignalLongSymbol" SG_ 2164171776 Engine_Exhaust_Gas_Recirculation1 "Engine Exhaust Gas Recirculation Temperature";
BA_ "SPN" SG_ 2164172032 Engine_Intake_Manifold_2_Tempera 1131;
BA_ "SystemSignalLongSymbol" SG_ 2164172032 Engine_Intake_Manifold_2_Tempera "Engine Intake Manifold 2 Temperature";
BA_ "SPN" SG_ 2164172032 Engine_Intake_Manifold_3_Tempera 1132;
BA_ "SystemSignalLongSymbol" SG_ 2164172032 Engine_Intake_Manifold_3_Tempera "Engine Intake Manifold 3 Temperature";
BA_ "SPN" SG_ 2164172032 Engine_Intake_Manifold_4_Tempera 1133;
BA_ "SystemSignalLongSymbol" SG_ 2164172032 Engine_Intake_Manifold_4_Tempera "Engine Intake Manifold 4 Temperature";
BA_ "SPN" SG_ 2164172032 Engine_Intake_Manifold_5_Tempera 1802;
BA_ "SystemSignalLongSymbol" SG_ 2164172032 Engine_Intake_Manifold_5_Tempera "Engine Intake Manifold 5 Temperature";
BA_ "SPN" SG_ 2164172032 Engine_Intake_Manifold_6_Tempera 1803;
BA_ "SystemSignalLongSymbol" SG_ 2164172032 Engine_Intake_Manifold_6_Tempera "Engine Intake Manifold 6 Temperature";
BA_ "SPN" SG_ 2164172288 Engine_Turbocharger_1_Boost_Pres 1127;
BA_ "SystemSignalLongSymbol" SG_ 2164172288 Engine_Turbocharger_1_Boost_Pres "Engine Turbocharger 1 Boost Pressure";
BA_ "SPN" SG_ 2164172288 Engine_Turbocharger_2_Boost_Pres 1128;
BA_ "SystemSignalLongSymbol" SG_ 2164172288 Engine_Turbocharger_2_Boost_Pres "Engine Turbocharger 2 Boost Pressure";
BA_ "SPN" SG_ 2164172288 Engine_Turbocharger_3_Boost_Pres 1129;
BA_ "SystemSignalLongSymbol" SG_ 2164172288 Engine_Turbocharger_3_Boost_Pres "Engine Turbocharger 3 Boost Pressure";
BA_ "SPN" SG_ 2164172288 Engine_Turbocharger_4_Boost_Pres 1130;
BA_ "SystemSignalLongSymbol" SG_ 2164172288 Engine_Turbocharger_4_Boost_Pres "Engine Turbocharger 4 Boost Pressure";
BA_ "SPN" SG_ 2164172544 Engine_Alternator_Bearing_1_Temp 1122;
BA_ "SystemSignalLongSymbol" SG_ 2164172544 Engine_Alternator_Bearing_1_Temp "Engine Alternator Bearing 1 Temperature";
BA_ "SPN" SG_ 2164172544 Engine_Alternator_Bearing_2_Temp 1123;
BA_ "SystemSignalLongSymbol" SG_ 2164172544 Engine_Alternator_Bearing_2_Temp "Engine Alternator Bearing 2 Temperature";
BA_ "SPN" SG_ 2164172544 Engine_Alternator_Winding_1_Temp 1124;
BA_ "SystemSignalLongSymbol" SG_ 2164172544 Engine_Alternator_Winding_1_Temp "Engine Alternator Winding 1 Temperature";
BA_ "SPN" SG_ 2164172544 Engine_Alternator_Winding_2_Temp 1125;
BA_ "SystemSignalLongSymbol" SG_ 2164172544 Engine_Alternator_Winding_2_Temp "Engine Alternator Winding 2 Temperature";
BA_ "SPN" SG_ 2164172544 Engine_Alternator_Winding_3_Temp 1126;
BA_ "SystemSignalLongSymbol" SG_ 2164172544 Engine_Alternator_Winding_3_Temp "Engine Alternator Winding 3 Temperature";
BA_ "SPN" SG_ 2164172800 Articulation_Angle 1120;
BA_ "SPN" SG_ 2164173056 Engine_Desired_Rated_Exhaust_Oxy 1117;
BA_ "SystemSignalLongSymbol" SG_ 2164173056 Engine_Desired_Rated_Exhaust_Oxy "Engine Desired Rated Exhaust Oxygen";
BA_ "SPN" SG_ 2164173056 Engine_Desired_Exhaust_Oxygen 1118;
BA_ "SPN" SG_ 2164173056 Engine_Actual_Exhaust_Oxygen 1119;
BA_ "SPN" SG_ 2164173056 Engine_Exhaust_Gas_Oxygen_Sensor0 1695;
BA_ "SystemSignalLongSymbol" SG_ 2164173056 Engine_Exhaust_Gas_Oxygen_Sensor0 "Engine Exhaust Gas Oxygen Sensor Fueling Correction";
BA_ "SPN" SG_ 2164173056 Engine_Exhaust_Gas_Oxygen_Sensor1 1696;
BA_ "SystemSignalLongSymbol" SG_ 2164173056 Engine_Exhaust_Gas_Oxygen_Sensor1 "Engine Exhaust Gas Oxygen Sensor Closed Loop Operation";
BA_ "SPN" SG_ 2164173312 Engine_Gaseous_Fuel_Correction_F 1116;
BA_ "SystemSignalLongSymbol" SG_ 2164173312 Engine_Gaseous_Fuel_Correction_F "Engine Gaseous Fuel Correction Factor";
BA_ "SPN" SG_ 2164173312 Engine_Desired_Absolute_Intake_M 1692;
BA_ "SystemSignalLongSymbol" SG_ 2164173312 Engine_Desired_Absolute_Intake_M "Engine Desired Absolute Intake Manifold Pressure (Turbo Boost Limit)";
BA_ "SPN" SG_ 2164173312 Engine_Turbocharger_Wastegate_Va 1693;
BA_ "SystemSignalLongSymbol" SG_ 2164173312 Engine_Turbocharger_Wastegate_Va "Engine Turbocharger Wastegate Valve Position";
BA_ "SPN" SG_ 2164173312 Engine_Gas_Mass_Flow_Sensor_Fuel 1694;
BA_ "SystemSignalLongSymbol" SG_ 2164173312 Engine_Gas_Mass_Flow_Sensor_Fuel "Engine Gas Mass Flow Sensor Fueling Correction";
BA_ "SPN" SG_ 2164173568 Recommended_Gear 1113;
BA_ "SPN" SG_ 2164173568 Highest_Possible_Gear 1115;
BA_ "SPN" SG_ 2164173568 Lowest_Possible_Gear 1114;
BA_ "SPN" SG_ 2164173568 Clutch_Life_Remaining 2983;
BA_ "SPN" SG_ 2164173824 Brake_Lining_Remaining__Front_Ax 1100;
BA_ "SystemSignalLongSymbol" SG_ 2164173824 Brake_Lining_Remaining__Front_Ax "Brake Lining Remaining, Front Axle, Right Wheel";
BA_ "SPN" SG_ 2164173824 Brake_Lining_Remaining__Rear_Axl0 1106;
BA_ "SystemSignalLongSymbol" SG_ 2164173824 Brake_Lining_Remaining__Rear_Axl0 "Brake Lining Remaining, Rear Axle #3, Right Wheel";
BA_ "SPN" SG_ 2164174080 Brake_Application_Pressure_High_0 1091;
BA_ "SystemSignalLongSymbol" SG_ 2164174080 Brake_Application_Pressure_High_0 "Brake Application Pressure High Range, Front Axle, Left Wheel";
BA_ "SPN" SG_ 2164174080 Brake_Application_Pressure_High_1 1092;
BA_ "SystemSignalLongSymbol" SG_ 2164174080 Brake_Application_Pressure_High_1 "Brake Application Pressure High Range, Front Axle, Right Wheel";
BA_ "SPN" SG_ 2164174080 Brake_Application_Pressure_High_2 1093;
BA_ "SystemSignalLongSymbol" SG_ 2164174080 Brake_Application_Pressure_High_2 "Brake Application Pressure High Range, Rear Axle #1, Left Wheel";
BA_ "SPN" SG_ 2164174080 Brake_Application_Pressure_High_3 1094;
BA_ "SystemSignalLongSymbol" SG_ 2164174080 Brake_Application_Pressure_High_3 "Brake Application Pressure High Range, Rear Axle #1, Right Wheel";
BA_ "SPN" SG_ 2164174080 Brake_Application_Pressure_High_4 1095;
BA_ "SystemSignalLongSymbol" SG_ 2164174080 Brake_Application_Pressure_High_4 "Brake Application Pressure High Range, Rear Axle #2, Left Wheel";
BA_ "SPN" SG_ 2164174080 Brake_Application_Pressure_High_5 1096;
BA_ "SystemSignalLongSymbol" SG_ 2164174080 Brake_Application_Pressure_High_5 "Brake Application Pressure High Range, Rear Axle #2, Right Wheel";
BA_ "SPN" SG_ 2164174080 Brake_Application_Pressure_High_6 1097;
BA_ "SystemSignalLongSymbol" SG_ 2164174080 Brake_Application_Pressure_High_6 "Brake Application Pressure High Range, Rear Axle #3, Left Wheel";
BA_ "SPN" SG_ 2164174080 Brake_Application_Pressure_High_7 1098;
BA_ "SystemSignalLongSymbol" SG_ 2164174080 Brake_Application_Pressure_High_7 "Brake Application Pressure High Range, Rear Axle #3, Right Wheel";
BA_ "SPN" SG_ 2164174336 Pneumatic_Supply_Pressure 46;
BA_ "SPN" SG_ 2164174336 Parking_and_or_Trailer_Air_Press 1086;
BA_ "SystemSignalLongSymbol" SG_ 2164174336 Parking_and_or_Trailer_Air_Press "Parking and/or Trailer Air Pressure";
BA_ "SPN" SG_ 2164174336 Service_Brake_Circuit_1_Air_Pres 1087;
BA_ "SystemSignalLongSymbol" SG_ 2164174336 Service_Brake_Circuit_1_Air_Pres "Service Brake Circuit 1 Air Pressure";
BA_ "SPN" SG_ 2164174336 Service_Brake_Circuit_2_Air_Pres 1088;
BA_ "SystemSignalLongSymbol" SG_ 2164174336 Service_Brake_Circuit_2_Air_Pres "Service Brake Circuit 2 Air Pressure";
BA_ "SPN" SG_ 2164174336 Auxiliary_Equipment_Supply_Press 1089;
BA_ "SystemSignalLongSymbol" SG_ 2164174336 Auxiliary_Equipment_Supply_Press "Auxiliary Equipment Supply Pressure";
BA_ "SPN" SG_ 2164174336 Air_Suspension_Supply_Pressure 1090;
BA_ "SPN" SG_ 2164174336 Air_Compressor_Status 1351;
BA_ "SPN" SG_ 2164174592 Trip_Fuel__Gaseous_ 1039;
BA_ "SPN" SG_ 2164174592 Total_Fuel_Used__Gaseous_ 1040;
BA_ "SPN" SG_ 2164174848 Trip_Cruise_Time 1034;
BA_ "SPN" SG_ 2164174848 Trip_PTO_Governor_Time 1035;
BA_ "SPN" SG_ 2164174848 Trip_Engine_Running_Time 1036;
BA_ "SPN" SG_ 2164174848 Trip_Idle_Time 1037;
BA_ "SPN" SG_ 2164174848 Trip_Air_Compressor_On_Time 1038;
BA_ "SPN" SG_ 2164175104 Total_ECU_Distance 1032;
BA_ "SPN" SG_ 2164175104 Total_ECU_Run_Time 1033;
BA_ "SPN" SG_ 2164175360 Total_Engine_PTO_Governor_Fuel_U 1030;
BA_ "SystemSignalLongSymbol" SG_ 2164175360 Total_Engine_PTO_Governor_Fuel_U "Total Engine PTO Governor Fuel Used (Gaseous)";
BA_ "SPN" SG_ 2164175360 Trip_Average_Fuel_Rate__Gaseous_ 1031;
BA_ "SPN" SG_ 2164175360 Engine_Fuel_Specific_Gravity 1389;
BA_ "SPN" SG_ 2164175616 Total_Engine_PTO_Governor_Fuel_U 1028;
BA_ "SystemSignalLongSymbol" SG_ 2164175616 Total_Engine_PTO_Governor_Fuel_U "Total Engine PTO Governor Fuel Used";
BA_ "SPN" SG_ 2164175616 Trip_Average_Fuel_Rate 1029;
BA_ "SPN" SG_ 2164175872 Trip_Time_in_VSL 1024;
BA_ "SPN" SG_ 2164175872 Trip_Time_in_Top_Gear 1025;
BA_ "SPN" SG_ 2164175872 Trip_Time_in_Gear_Down 1026;
BA_ "SPN" SG_ 2164175872 Trip_Time_in_Derate_by_Engine 1027;
BA_ "SPN" SG_ 2164176128 Trip_Number_of_Hot_Shutdowns 1020;
BA_ "SPN" SG_ 2164176128 Trip_Number_of_Idle_Shutdowns 1021;
BA_ "SPN" SG_ 2164176128 Trip_Number_of_Idle_Shutdown_Ove 1022;
BA_ "SystemSignalLongSymbol" SG_ 2164176128 Trip_Number_of_Idle_Shutdown_Ove "Trip Number of Idle Shutdown Overrides";
BA_ "SPN" SG_ 2164176128 Trip_Sudden_Decelerations 1023;
BA_ "SPN" SG_ 2164176384 Trip_Maximum_Vehicle_Speed 1018;
BA_ "SPN" SG_ 2164176384 Trip_Cruise_Distance 1019;
BA_ "SPN" SG_ 2164176640 Trip_Maximum_Engine_Speed 1013;
BA_ "SPN" SG_ 2164176640 Trip_Average_Engine_Speed 1014;
BA_ "SPN" SG_ 2164176640 Trip_Drive_Average_Load_Factor 1015;
BA_ "SPN" SG_ 2164176640 Total_Drive_Average_Load_Factor 1016;
BA_ "SPN" SG_ 2164176640 Total_Engine_Cruise_Time 1017;
BA_ "SPN" SG_ 2164176896 Trip_Drive_Fuel_Used__Gaseous_ 1007;
BA_ "SPN" SG_ 2164176896 Trip_PTO_Governor_Moving_Fuel_Us 1008;
BA_ "SystemSignalLongSymbol" SG_ 2164176896 Trip_PTO_Governor_Moving_Fuel_Us "Trip PTO Governor Moving Fuel Used (Gaseous)";
BA_ "SPN" SG_ 2164176896 Trip_PTO_Governor_Non_moving_Fue 1009;
BA_ "SystemSignalLongSymbol" SG_ 2164176896 Trip_PTO_Governor_Non_moving_Fue "Trip PTO Governor Non-moving Fuel Used (Gaseous)";
BA_ "SPN" SG_ 2164176896 Trip_Vehicle_Idle_Fuel_Used__Gas 1010;
BA_ "SystemSignalLongSymbol" SG_ 2164176896 Trip_Vehicle_Idle_Fuel_Used__Gas "Trip Vehicle Idle Fuel Used (Gaseous)";
BA_ "SPN" SG_ 2164176896 Trip_Cruise_Fuel_Used__Gaseous_ 1011;
BA_ "SPN" SG_ 2164176896 Trip_Drive_Fuel_Economy__Gaseous 1012;
BA_ "SystemSignalLongSymbol" SG_ 2164176896 Trip_Drive_Fuel_Economy__Gaseous "Trip Drive Fuel Economy (Gaseous)";
BA_ "SPN" SG_ 2164177152 Trip_Drive_Fuel_Used 1001;
BA_ "SPN" SG_ 2164177152 Trip_PTO_Governor_Moving_Fuel_Us 1002;
BA_ "SystemSignalLongSymbol" SG_ 2164177152 Trip_PTO_Governor_Moving_Fuel_Us "Trip PTO Governor Moving Fuel Used";
BA_ "SPN" SG_ 2164177152 Trip_PTO_Governor_Non_moving_Fue 1003;
BA_ "SystemSignalLongSymbol" SG_ 2164177152 Trip_PTO_Governor_Non_moving_Fue "Trip PTO Governor Non-moving Fuel Used";
BA_ "SPN" SG_ 2164177152 Trip_Vehicle_Idle_Fuel_Used 1004;
BA_ "SPN" SG_ 2164177152 Trip_Cruise_Fuel_Used 1005;
BA_ "SPN" SG_ 2164177152 Trip_Drive_Fuel_Economy 1006;
BA_ "SPN" SG_ 2164177408 Trip_Distance_on_VSL 998;
BA_ "SPN" SG_ 2164177408 Trip_Gear_Down_Distance 999;
BA_ "SPN" SG_ 2164177408 Trip_Distance_in_Top_Gear 1000;
BA_ "SPN" SG_ 2164177664 Trip_Fan_On_Time 994;
BA_ "SPN" SG_ 2164177664 Trip_Fan_On_Time_Due_to_the_Engi 995;
BA_ "SystemSignalLongSymbol" SG_ 2164177664 Trip_Fan_On_Time_Due_to_the_Engi "Trip Fan On Time Due to the Engine System";
BA_ "SPN" SG_ 2164177664 Trip_Fan_On_Time_Due_to_a_Manual 996;
BA_ "SystemSignalLongSymbol" SG_ 2164177664 Trip_Fan_On_Time_Due_to_a_Manual "Trip Fan On Time Due to a Manual Switch";
BA_ "SPN" SG_ 2164177664 Trip_Fan_On_Time_Due_to_the_A_C_ 997;
BA_ "SystemSignalLongSymbol" SG_ 2164177664 Trip_Fan_On_Time_Due_to_the_A_C_ "Trip Fan On Time Due to the A/C System";
BA_ "SPN" SG_ 2164177920 Total_Compression_Brake_Distance 990;
BA_ "SPN" SG_ 2164177920 Trip_Compression_Brake_Distance 991;
BA_ "SPN" SG_ 2164177920 Trip_Service_Brake_Distance 992;
BA_ "SPN" SG_ 2164177920 Trip_Service_Brake_Applications 993;
BA_ "SPN" SG_ 2164178176 Estimated_Percent_Fan_Speed 975;
BA_ "SPN" SG_ 2164178176 Fan_Drive_State 977;
BA_ "SPN" SG_ 2164178176 Fan_Speed 1639;
BA_ "SPN" SG_ 2164178176 Hydraulic_Fan_Motor_Pressure 4211;
BA_ "SPN" SG_ 2164178176 Fan_Drive_Bypass_Command_Status 4212;
BA_ "SPN" SG_ 2164178432 Engine_Rated_Power 166;
BA_ "SPN" SG_ 2164178432 Engine_Rated_Speed 189;
BA_ "SPN" SG_ 2164178432 Engine_Rotation_Direction 3669;
BA_ "SPN" SG_ 2164178432 Crank_Attempt_Count_on_Present_S 3671;
BA_ "SystemSignalLongSymbol" SG_ 2164178432 Crank_Attempt_Count_on_Present_S "Crank Attempt Count on Present Start Attempt";
BA_ "SPN" SG_ 2164178688 Front_Axle_Speed 904;
BA_ "SPN" SG_ 2164178688 Relative_Speed__Front_Axle__Left 905;
BA_ "SystemSignalLongSymbol" SG_ 2164178688 Relative_Speed__Front_Axle__Left "Relative Speed; Front Axle, Left Wheel";
BA_ "SPN" SG_ 2164178688 Relative_Speed__Front_Axle__Righ 906;
BA_ "SystemSignalLongSymbol" SG_ 2164178688 Relative_Speed__Front_Axle__Righ "Relative Speed; Front Axle, Right Wheel";
BA_ "SPN" SG_ 2164178688 Relative_Speed__Rear_Axle__1__Le 907;
BA_ "SystemSignalLongSymbol" SG_ 2164178688 Relative_Speed__Rear_Axle__1__Le "Relative Speed; Rear Axle #1, Left Wheel";
BA_ "SPN" SG_ 2164178688 Relative_Speed__Rear_Axle__1__Ri 908;
BA_ "SystemSignalLongSymbol" SG_ 2164178688 Relative_Speed__Rear_Axle__1__Ri "Relative Speed; Rear Axle #1, Right Wheel";
BA_ "SPN" SG_ 2164178688 Relative_Speed__Rear_Axle__2__Le 909;
BA_ "SystemSignalLongSymbol" SG_ 2164178688 Relative_Speed__Rear_Axle__2__Le "Relative Speed; Rear Axle #2, Left Wheel";
BA_ "SPN" SG_ 2164178688 Relative_Speed__Rear_Axle__2__Ri 910;
BA_ "SystemSignalLongSymbol" SG_ 2164178688 Relative_Speed__Rear_Axle__2__Ri "Relative Speed; Rear Axle #2, Right Wheel";
BA_ "SPN" SG_ 2164178944 Service_Component_Identification0 911;
BA_ "SystemSignalLongSymbol" SG_ 2164178944 Service_Component_Identification0 "Service_Component_Identification0";
BA_ "SPN" SG_ 2164178944 Service_Distance 914;
BA_ "SPN" SG_ 2164178944 Service_Component_Identification1 912;
BA_ "SystemSignalLongSymbol" SG_ 2164178944 Service_Component_Identification1 "Service_Component_Identification1";
BA_ "SPN" SG_ 2164178944 Service_Delay_Calendar_Time_Base 915;
BA_ "SystemSignalLongSymbol" SG_ 2164178944 Service_Delay_Calendar_Time_Base "Service Delay/Calendar Time Based";
BA_ "SPN" SG_ 2164178944 Service_Component_Identification2 913;
BA_ "SystemSignalLongSymbol" SG_ 2164178944 Service_Component_Identification2 "Service_Component_Identification2";
BA_ "SPN" SG_ 2164178944 Service_Delay_Operational_Time_B 916;
BA_ "SystemSignalLongSymbol" SG_ 2164178944 Service_Delay_Operational_Time_B "Service Delay/Operational Time Based";
BA_ "SPN" SG_ 2164179200 High_Resolution_Total_Vehicle_Di 917;
BA_ "SystemSignalLongSymbol" SG_ 2164179200 High_Resolution_Total_Vehicle_Di "High Resolution Total Vehicle Distance";
BA_ "SPN" SG_ 2164179200 High_Resolution_Trip_Distance 918;
BA_ "SPN" SG_ 2164179456 Transmission_Output_Retarder 748;
BA_ "SPN" SG_ 2164179712 Transmission_High_Range_Sense_Sw 778;
BA_ "SystemSignalLongSymbol" SG_ 2164179712 Transmission_High_Range_Sense_Sw "Transmission High Range Sense Switch";
BA_ "SPN" SG_ 2164179712 Transmission_Low_Range_Sense_Swi 779;
BA_ "SystemSignalLongSymbol" SG_ 2164179712 Transmission_Low_Range_Sense_Swi "Transmission Low Range Sense Switch";
BA_ "SPN" SG_ 2164179712 Transmission_Reverse_Direction_S 767;
BA_ "SystemSignalLongSymbol" SG_ 2164179712 Transmission_Reverse_Direction_S "Transmission Reverse Direction Switch";
BA_ "SPN" SG_ 2164179712 Transmission_Neutral_Switch 604;
BA_ "SPN" SG_ 2164179712 Transmission_Forward_Direction_S 903;
BA_ "SystemSignalLongSymbol" SG_ 2164179712 Transmission_Forward_Direction_S "Transmission Forward Direction Switch";
BA_ "SPN" SG_ 2164180224 Transmission_Synchronizer_Clutch 53;
BA_ "SystemSignalLongSymbol" SG_ 2164180224 Transmission_Synchronizer_Clutch "Transmission Synchronizer Clutch Value";
BA_ "SPN" SG_ 2164180224 Transmission_Synchronizer_Brake_ 54;
BA_ "SystemSignalLongSymbol" SG_ 2164180224 Transmission_Synchronizer_Brake_ "Transmission Synchronizer Brake Value";
BA_ "SPN" SG_ 2164180736 Transmission_Shift_Finger_Gear_P 59;
BA_ "SystemSignalLongSymbol" SG_ 2164180736 Transmission_Shift_Finger_Gear_P "Transmission Shift Finger Gear Position";
BA_ "SPN" SG_ 2164180736 Transmission_Shift_Finger_Rail_P 60;
BA_ "SystemSignalLongSymbol" SG_ 2164180736 Transmission_Shift_Finger_Rail_P "Transmission Shift Finger Rail Position";
BA_ "SPN" SG_ 2164180736 Transmission_Shift_Finger_Neutra 780;
BA_ "SystemSignalLongSymbol" SG_ 2164180736 Transmission_Shift_Finger_Neutra "Transmission Shift Finger Neutral Indicator";
BA_ "SPN" SG_ 2164180736 Transmission_Shift_Finger_Engage 781;
BA_ "SystemSignalLongSymbol" SG_ 2164180736 Transmission_Shift_Finger_Engage "Transmission Shift Finger Engagement Indicator";
BA_ "SPN" SG_ 2164180736 Transmission_Shift_Finger_Center 782;
BA_ "SystemSignalLongSymbol" SG_ 2164180736 Transmission_Shift_Finger_Center "Transmission Shift Finger Center Rail Indicator";
BA_ "SPN" SG_ 2164180736 Transmission_Shift_Finger_Rail_A0 772;
BA_ "SystemSignalLongSymbol" SG_ 2164180736 Transmission_Shift_Finger_Rail_A0 "Transmission Shift Finger Rail Actuator 1";
BA_ "SPN" SG_ 2164180736 Transmission_Shift_Finger_Gear_A0 773;
BA_ "SystemSignalLongSymbol" SG_ 2164180736 Transmission_Shift_Finger_Gear_A0 "Transmission Shift Finger Gear Actuator 1";
BA_ "SPN" SG_ 2164180736 Transmission_Shift_Finger_Rail_A1 783;
BA_ "SystemSignalLongSymbol" SG_ 2164180736 Transmission_Shift_Finger_Rail_A1 "Transmission Shift Finger Rail Actuator 2";
BA_ "SPN" SG_ 2164180736 Transmission_Shift_Finger_Gear_A1 784;
BA_ "SystemSignalLongSymbol" SG_ 2164180736 Transmission_Shift_Finger_Gear_A1 "Transmission Shift Finger Gear Actuator 2";
BA_ "SPN" SG_ 2164180736 Transmission_Range_High_Actuator 768;
BA_ "SPN" SG_ 2164180736 Transmission_Range_Low_Actuator 769;
BA_ "SPN" SG_ 2164180736 Transmission_Splitter_Direct_Act 770;
BA_ "SystemSignalLongSymbol" SG_ 2164180736 Transmission_Splitter_Direct_Act "Transmission Splitter Direct Actuator";
BA_ "SPN" SG_ 2164180736 Transmission_Splitter_Indirect_A 771;
BA_ "SystemSignalLongSymbol" SG_ 2164180736 Transmission_Splitter_Indirect_A "Transmission Splitter Indirect Actuator";
BA_ "SPN" SG_ 2164180736 Transmission_Clutch_Actuator 788;
BA_ "SPN" SG_ 2164180736 Transmission_Lockup_Clutch_Actua 740;
BA_ "SystemSignalLongSymbol" SG_ 2164180736 Transmission_Lockup_Clutch_Actua "Transmission Lockup Clutch Actuator";
BA_ "SPN" SG_ 2164180736 Transmission_Defuel_Actuator 786;
BA_ "SPN" SG_ 2164180736 Transmission_Inertia_Brake_Actua 787;
BA_ "SystemSignalLongSymbol" SG_ 2164180736 Transmission_Inertia_Brake_Actua "Transmission Inertia Brake Actuator";
BA_ "SPN" SG_ 2164184320 Alternator_Speed 589;
BA_ "SPN" SG_ 2164184320 Alternator_1_Status 3353;
BA_ "SPN" SG_ 2164184320 Alternator_2_Status 3354;
BA_ "SPN" SG_ 2164184320 Alternator_3_Status 3355;
BA_ "SPN" SG_ 2164184320 Alternator_4_Status 3356;
BA_ "SPN" SG_ 2164185344 Auxiliary_I_O__04 704;
BA_ "SPN" SG_ 2164185344 Auxiliary_I_O__03 703;
BA_ "SPN" SG_ 2164185344 Auxiliary_I_O__02 702;
BA_ "SPN" SG_ 2164185344 Auxiliary_I_O__01 701;
BA_ "SPN" SG_ 2164185344 Auxiliary_I_O__08 708;
BA_ "SPN" SG_ 2164185344 Auxiliary_I_O__07 707;
BA_ "SPN" SG_ 2164185344 Auxiliary_I_O__06 706;
BA_ "SPN" SG_ 2164185344 Auxiliary_I_O__05 705;
BA_ "SPN" SG_ 2164185344 Auxiliary_I_O__12 712;
BA_ "SPN" SG_ 2164185344 Auxiliary_I_O__11 711;
BA_ "SPN" SG_ 2164185344 Auxiliary_I_O__10 710;
BA_ "SPN" SG_ 2164185344 Auxiliary_I_O__09 709;
BA_ "SPN" SG_ 2164185344 Auxiliary_I_O__16 716;
BA_ "SPN" SG_ 2164185344 Auxiliary_I_O__15 715;
BA_ "SPN" SG_ 2164185344 Auxiliary_I_O__14 714;
BA_ "SPN" SG_ 2164185344 Auxiliary_I_O__13 713;
BA_ "SPN" SG_ 2164185344 Auxiliary_I_O_Channel__1 1083;
BA_ "SPN" SG_ 2164185344 Auxiliary_I_O_Channel__2 1084;
BA_ "SPN" SG_ 2164185600 Number_of_Software_Identificatio 965;
BA_ "SystemSignalLongSymbol" SG_ 2164185600 Number_of_Software_Identificatio "Number of Software Identification Fields";
BA_ "SPN" SG_ 2164185600 Software_Identification 234;
BA_ "SPN" SG_ 2164185856 Engine_Injection_Control_Pressur 164;
BA_ "SystemSignalLongSymbol" SG_ 2164185856 Engine_Injection_Control_Pressur "Engine Injection Control Pressure";
BA_ "SPN" SG_ 2164185856 Engine_Injector_Metering_Rail_1_ 157;
BA_ "SystemSignalLongSymbol" SG_ 2164185856 Engine_Injector_Metering_Rail_1_ "Engine Injector Metering Rail 1 Pressure";
BA_ "SPN" SG_ 2164185856 Engine_Injector_Timing_Rail_1_Pr 156;
BA_ "SystemSignalLongSymbol" SG_ 2164185856 Engine_Injector_Timing_Rail_1_Pr "Engine Injector Timing Rail 1 Pressure";
BA_ "SPN" SG_ 2164185856 Engine_Injector_Metering_Rail_2_ 1349;
BA_ "SystemSignalLongSymbol" SG_ 2164185856 Engine_Injector_Metering_Rail_2_ "Engine Injector Metering Rail 2 Pressure";
BA_ "SPN" SG_ 2164186112 Engine_Total_Idle_Fuel_Used 236;
BA_ "SPN" SG_ 2164186112 Engine_Total_Idle_Hours 235;
BA_ "SPN" SG_ 2164186368 Engine_Turbocharger_Lube_Oil_Pre 104;
BA_ "SystemSignalLongSymbol" SG_ 2164186368 Engine_Turbocharger_Lube_Oil_Pre "Engine Turbocharger Lube Oil Pressure 1";
BA_ "SPN" SG_ 2164186368 Engine_Turbocharger_1_Speed 103;
BA_ "SPN" SG_ 2164186368 Engine_Turbocharger_Oil_Level_Sw 1665;
BA_ "SystemSignalLongSymbol" SG_ 2164186368 Engine_Turbocharger_Oil_Level_Sw "Engine Turbocharger Oil Level Switch";
BA_ "SPN" SG_ 2164186624 Engine_Air_Start_Pressure 82;
BA_ "SPN" SG_ 2164186880 Nominal_Friction___Percent_Torqu 514;
BA_ "SystemSignalLongSymbol" SG_ 2164186880 Nominal_Friction___Percent_Torqu "Nominal Friction - Percent Torque";
BA_ "SPN" SG_ 2164186880 Engine_s_Desired_Operating_Speed 519;
BA_ "SystemSignalLongSymbol" SG_ 2164186880 Engine_s_Desired_Operating_Speed "Engine's Desired Operating Speed Asymmetry Adjustment";
BA_ "SPN" SG_ 2164186880 Estimated_Engine_Parasitic_Losse 2978;
BA_ "SystemSignalLongSymbol" SG_ 2164186880 Estimated_Engine_Parasitic_Losse "Estimated Engine Parasitic Losses - Percent Torque";
BA_ "SPN" SG_ 2164186880 Aftertreatment_1_Exhaust_Gas_Mas 3236;
BA_ "SystemSignalLongSymbol" SG_ 2164186880 Aftertreatment_1_Exhaust_Gas_Mas "Aftertreatment 1 Exhaust Gas Mass Flow";
BA_ "SPN" SG_ 2164186880 Aftertreatment_1_Intake_Dew_Poin 3237;
BA_ "SystemSignalLongSymbol" SG_ 2164186880 Aftertreatment_1_Intake_Dew_Poin "Aftertreatment 1 Intake Dew Point";
BA_ "SPN" SG_ 2164186880 Aftertreatment_1_Exhaust_Dew_Poi 3238;
BA_ "SystemSignalLongSymbol" SG_ 2164186880 Aftertreatment_1_Exhaust_Dew_Poi "Aftertreatment 1 Exhaust Dew Point";
BA_ "SPN" SG_ 2164186880 Aftertreatment_2_Intake_Dew_Poin 3239;
BA_ "SystemSignalLongSymbol" SG_ 2164186880 Aftertreatment_2_Intake_Dew_Poin "Aftertreatment 2 Intake Dew Point";
BA_ "SPN" SG_ 2164186880 Aftertreatment_2_Exhaust_Dew_Poi 3240;
BA_ "SystemSignalLongSymbol" SG_ 2164186880 Aftertreatment_2_Exhaust_Dew_Poi "Aftertreatment 2 Exhaust Dew Point";
BA_ "SPN" SG_ 2164187136 Trip_Distance 244;
BA_ "SPN" SG_ 2164187136 Total_Vehicle_Distance 245;
BA_ "SPN" SG_ 2164187392 Retarder_Type 901;
BA_ "SPN" SG_ 2164187392 Retarder_Location 902;
BA_ "SPN" SG_ 2164187392 Retarder_Control_Method__Retarde 557;
BA_ "SystemSignalLongSymbol" SG_ 2164187392 Retarder_Control_Method__Retarde "Retarder Control Method (Retarder Configuration)";
BA_ "SPN" SG_ 2164187392 Retarder_Speed_At_Idle__Point_1_ 546;
BA_ "SystemSignalLongSymbol" SG_ 2164187392 Retarder_Speed_At_Idle__Point_1_ "Retarder Speed At Idle, Point 1 (Retarder Configuration)";
BA_ "SPN" SG_ 2164187392 Percent_Torque_At_Idle__Point_1_ 551;
BA_ "SystemSignalLongSymbol" SG_ 2164187392 Percent_Torque_At_Idle__Point_1_ "Percent Torque At Idle, Point 1 (Retarder Configuration)";
BA_ "SPN" SG_ 2164187392 Maximum_Retarder_Speed__Point_2_ 548;
BA_ "SystemSignalLongSymbol" SG_ 2164187392 Maximum_Retarder_Speed__Point_2_ "Maximum Retarder Speed, Point 2 (Retarder Configuration)";
BA_ "SPN" SG_ 2164187392 Percent_Torque_At_Maximum_Speed_ 552;
BA_ "SystemSignalLongSymbol" SG_ 2164187392 Percent_Torque_At_Maximum_Speed_ "Percent Torque At Maximum Speed, Point 2 (Retarder Configuration)";
BA_ "SPN" SG_ 2164187392 Retarder_Speed_At_Point_3__Retar 549;
BA_ "SystemSignalLongSymbol" SG_ 2164187392 Retarder_Speed_At_Point_3__Retar "Retarder Speed At Point 3 (Retarder Configuration)";
BA_ "SPN" SG_ 2164187392 Percent_Torque_At_Point_3__Retar 553;
BA_ "SystemSignalLongSymbol" SG_ 2164187392 Percent_Torque_At_Point_3__Retar "Percent Torque At Point 3 (Retarder Configuration)";
BA_ "SPN" SG_ 2164187392 Retarder_Speed_At_Point_4__Retar 550;
BA_ "SystemSignalLongSymbol" SG_ 2164187392 Retarder_Speed_At_Point_4__Retar "Retarder Speed At Point 4 (Retarder Configuration)";
BA_ "SPN" SG_ 2164187392 Percent_Torque_At_Point_4__Retar 554;
BA_ "SystemSignalLongSymbol" SG_ 2164187392 Percent_Torque_At_Point_4__Retar "Percent Torque At Point 4 (Retarder Configuration)";
BA_ "SPN" SG_ 2164187392 Retarder_Speed_At_Peak_Torque__P 547;
BA_ "SystemSignalLongSymbol" SG_ 2164187392 Retarder_Speed_At_Peak_Torque__P "Retarder Speed At Peak Torque, Point 5 (Retarder Configuration)";
BA_ "SPN" SG_ 2164187392 Reference_Retarder_Torque__Retar 556;
BA_ "SystemSignalLongSymbol" SG_ 2164187392 Reference_Retarder_Torque__Retar "Reference Retarder Torque (Retarder Configuration)";
BA_ "SPN" SG_ 2164187392 Percent_Torque_At_Peak_Torque__P 555;
BA_ "SystemSignalLongSymbol" SG_ 2164187392 Percent_Torque_At_Peak_Torque__P "Percent Torque At Peak Torque, Point 5 (Retarder Configuration)";
BA_ "SPN" SG_ 2164187648 Number_of_Reverse_Gear_Ratios 958;
BA_ "SPN" SG_ 2164187648 Number_of_Forward_Gear_Ratios 957;
BA_ "SPN" SG_ 2164187648 Transmission_Gear_Ratio 581;
BA_ "SPN" SG_ 2164187904 Engine_Speed_At_Idle__Point_1__E 188;
BA_ "SystemSignalLongSymbol" SG_ 2164187904 Engine_Speed_At_Idle__Point_1__E "Engine Speed At Idle, Point 1 (Engine Configuration)";
BA_ "SPN" SG_ 2164187904 Engine_Percent_Torque_At_Idle__P 539;
BA_ "SystemSignalLongSymbol" SG_ 2164187904 Engine_Percent_Torque_At_Idle__P "Engine Percent Torque At Idle, Point 1 (Engine Configuration)";
BA_ "SPN" SG_ 2164187904 Engine_Speed_At_Point_2__Engine_ 528;
BA_ "SystemSignalLongSymbol" SG_ 2164187904 Engine_Speed_At_Point_2__Engine_ "Engine Speed At Point 2 (Engine Configuration)";
BA_ "SPN" SG_ 2164187904 Engine_Percent_Torque_At_Point_2 540;
BA_ "SystemSignalLongSymbol" SG_ 2164187904 Engine_Percent_Torque_At_Point_2 "Engine Percent Torque At Point 2 (Engine Configuration)";
BA_ "SPN" SG_ 2164187904 Engine_Speed_At_Point_3__Engine_ 529;
BA_ "SystemSignalLongSymbol" SG_ 2164187904 Engine_Speed_At_Point_3__Engine_ "Engine Speed At Point 3 (Engine Configuration)";
BA_ "SPN" SG_ 2164187904 Engine_Percent_Torque_At_Point_3 541;
BA_ "SystemSignalLongSymbol" SG_ 2164187904 Engine_Percent_Torque_At_Point_3 "Engine Percent Torque At Point 3 (Engine Configuration)";
BA_ "SPN" SG_ 2164187904 Engine_Speed_At_Point_4__Engine_ 530;
BA_ "SystemSignalLongSymbol" SG_ 2164187904 Engine_Speed_At_Point_4__Engine_ "Engine Speed At Point 4 (Engine Configuration)";
BA_ "SPN" SG_ 2164187904 Engine_Percent_Torque_At_Point_4 542;
BA_ "SystemSignalLongSymbol" SG_ 2164187904 Engine_Percent_Torque_At_Point_4 "Engine Percent Torque At Point 4 (Engine Configuration)";
BA_ "SPN" SG_ 2164187904 Engine_Speed_At_Point_5__Engine_ 531;
BA_ "SystemSignalLongSymbol" SG_ 2164187904 Engine_Speed_At_Point_5__Engine_ "Engine Speed At Point 5 (Engine Configuration)";
BA_ "SPN" SG_ 2164187904 Engine_Percent_Torque_At_Point_5 543;
BA_ "SystemSignalLongSymbol" SG_ 2164187904 Engine_Percent_Torque_At_Point_5 "Engine Percent Torque At Point 5 (Engine Configuration)";
BA_ "SPN" SG_ 2164187904 Engine_Speed_At_High_Idle__Point 532;
BA_ "SystemSignalLongSymbol" SG_ 2164187904 Engine_Speed_At_High_Idle__Point "Engine Speed At High Idle, Point 6 (Engine Configuration)";
BA_ "SPN" SG_ 2164187904 Engine_Gain__Kp__Of_The_Endspeed 545;
BA_ "SystemSignalLongSymbol" SG_ 2164187904 Engine_Gain__Kp__Of_The_Endspeed "Engine Gain (Kp) Of The Endspeed Governor (Engine Configuration)";
BA_ "SPN" SG_ 2164187904 Engine_Reference_Torque__Engine_ 544;
BA_ "SystemSignalLongSymbol" SG_ 2164187904 Engine_Reference_Torque__Engine_ "Engine Reference Torque (Engine Configuration)";
BA_ "SPN" SG_ 2164187904 Engine_Maximum_Momentary_Overrid0 533;
BA_ "SystemSignalLongSymbol" SG_ 2164187904 Engine_Maximum_Momentary_Overrid0 "Engine Maximum Momentary Override Speed, Point 7 (Engine Configuration)";
BA_ "SPN" SG_ 2164187904 Engine_Maximum_Momentary_Overrid1 534;
BA_ "SystemSignalLongSymbol" SG_ 2164187904 Engine_Maximum_Momentary_Overrid1 "Engine Maximum Momentary Override Time Limit (Engine Configuration)";
BA_ "SPN" SG_ 2164187904 Engine_Requested_Speed_Control_R0 535;
BA_ "SystemSignalLongSymbol" SG_ 2164187904 Engine_Requested_Speed_Control_R0 "Engine Requested Speed Control Range Lower Limit (Engine Configuration)";
BA_ "SPN" SG_ 2164187904 Engine_Requested_Speed_Control_R1 536;
BA_ "SystemSignalLongSymbol" SG_ 2164187904 Engine_Requested_Speed_Control_R1 "Engine Requested Speed Control Range Upper Limit (Engine Configuration)";
BA_ "SPN" SG_ 2164187904 Engine_Requested_Torque_Control_0 537;
BA_ "SystemSignalLongSymbol" SG_ 2164187904 Engine_Requested_Torque_Control_0 "Engine Requested Torque Control Range Lower Limit (Engine Configuration)";
BA_ "SPN" SG_ 2164187904 Engine_Requested_Torque_Control_1 538;
BA_ "SystemSignalLongSymbol" SG_ 2164187904 Engine_Requested_Torque_Control_1 "Engine Requested Torque Control Range Upper Limit (Engine Configuration)";
BA_ "SPN" SG_ 2164187904 Engine_Extended_Range_Requested_ 1712;
BA_ "SystemSignalLongSymbol" SG_ 2164187904 Engine_Extended_Range_Requested_ "Engine Extended Range Requested Speed Control Range Upper Limit (Engine configuration)";
BA_ "SPN" SG_ 2164187904 Engine_Moment_of_Inertia 1794;
BA_ "SPN" SG_ 2164187904 Engine_Default_Torque_Limit 1846;
BA_ "SPN" SG_ 2164187904 Support_Variable_Rate_TSC1_Messa 3344;
BA_ "SystemSignalLongSymbol" SG_ 2164187904 Support_Variable_Rate_TSC1_Messa "Support Variable Rate TSC1 Message";
BA_ "SPN" SG_ 2164187904 Support_TSC1_Control_Purpose_Gro0 3345;
BA_ "SystemSignalLongSymbol" SG_ 2164187904 Support_TSC1_Control_Purpose_Gro0 "Support TSC1 Control Purpose Group 1";
BA_ "SPN" SG_ 2164187904 Support_TSC1_Control_Purpose_Gro1 3346;
BA_ "SystemSignalLongSymbol" SG_ 2164187904 Support_TSC1_Control_Purpose_Gro1 "Support TSC1 Control Purpose Group 2";
BA_ "SPN" SG_ 2164187904 Support_TSC1_Control_Purpose_Gro2 3347;
BA_ "SystemSignalLongSymbol" SG_ 2164187904 Support_TSC1_Control_Purpose_Gro2 "Support TSC1 Control Purpose Group 3";
BA_ "SPN" SG_ 2164187904 Support_TSC1_Control_Purpose_Gro3 3348;
BA_ "SystemSignalLongSymbol" SG_ 2164187904 Support_TSC1_Control_Purpose_Gro3 "Support TSC1 Control Purpose Group 4";
BA_ "SPN" SG_ 2164188160 Engine_Idle_Shutdown_has_Shutdow 593;
BA_ "SystemSignalLongSymbol" SG_ 2164188160 Engine_Idle_Shutdown_has_Shutdow "Engine Idle Shutdown has Shutdown Engine";
BA_ "SPN" SG_ 2164188160 Engine_Idle_Shutdown_Driver_Aler 594;
BA_ "SystemSignalLongSymbol" SG_ 2164188160 Engine_Idle_Shutdown_Driver_Aler "Engine Idle Shutdown Driver Alert Mode";
BA_ "SPN" SG_ 2164188160 Engine_Idle_Shutdown_Timer_Overr 592;
BA_ "SystemSignalLongSymbol" SG_ 2164188160 Engine_Idle_Shutdown_Timer_Overr "Engine Idle Shutdown Timer Override";
BA_ "SPN" SG_ 2164188160 Engine_Idle_Shutdown_Timer_State 590;
BA_ "SPN" SG_ 2164188160 Engine_Idle_Shutdown_Timer_Funct 591;
BA_ "SystemSignalLongSymbol" SG_ 2164188160 Engine_Idle_Shutdown_Timer_Funct "Engine Idle Shutdown Timer Function";
BA_ "SPN" SG_ 2164188160 A_C_High_Pressure_Fan_Switch 985;
BA_ "SPN" SG_ 2164188160 Refrigerant_Low_Pressure_Switch 875;
BA_ "SPN" SG_ 2164188160 Refrigerant_High_Pressure_Switch 605;
BA_ "SPN" SG_ 2164188160 Engine_Wait_to_Start_Lamp 1081;
BA_ "SPN" SG_ 2164188160 Engine_Protection_System_has_Shu 1110;
BA_ "SystemSignalLongSymbol" SG_ 2164188160 Engine_Protection_System_has_Shu "Engine Protection System has Shutdown Engine";
BA_ "SPN" SG_ 2164188160 Engine_Protection_System_Approac 1109;
BA_ "SystemSignalLongSymbol" SG_ 2164188160 Engine_Protection_System_Approac "Engine Protection System Approaching Shutdown";
BA_ "SPN" SG_ 2164188160 Engine_Protection_System_Timer_O 1108;
BA_ "SystemSignalLongSymbol" SG_ 2164188160 Engine_Protection_System_Timer_O "Engine Protection System Timer Override";
BA_ "SPN" SG_ 2164188160 Engine_Protection_System_Timer_S 1107;
BA_ "SystemSignalLongSymbol" SG_ 2164188160 Engine_Protection_System_Timer_S "Engine Protection System Timer State";
BA_ "SPN" SG_ 2164188160 Engine_Protection_System_Configu 1111;
BA_ "SystemSignalLongSymbol" SG_ 2164188160 Engine_Protection_System_Configu "Engine Protection System Configuration";
BA_ "SPN" SG_ 2164188160 Engine_Alarm_Acknowledge 2815;
BA_ "SPN" SG_ 2164188160 Engine_Alarm_Output_Command_Stat 2814;
BA_ "SystemSignalLongSymbol" SG_ 2164188160 Engine_Alarm_Output_Command_Stat "Engine Alarm Output Command Status";
BA_ "SPN" SG_ 2164188160 Engine_Air_Shutoff_Command_Statu 2813;
BA_ "SystemSignalLongSymbol" SG_ 2164188160 Engine_Air_Shutoff_Command_Statu "Engine Air Shutoff Command Status";
BA_ "SPN" SG_ 2164188160 Engine_Overspeed_Test 2812;
BA_ "SPN" SG_ 2164188160 Engine_Air_Shutoff_Status 3667;
BA_ "SPN" SG_ 2164188416 Engine_Total_Hours_of_Operation 247;
BA_ "SPN" SG_ 2164188416 Engine_Total_Revolutions 249;
BA_ "SPN" SG_ 2164188672 Seconds 959;
BA_ "SPN" SG_ 2164188672 Minutes 960;
BA_ "SPN" SG_ 2164188672 Hours 961;
BA_ "SPN" SG_ 2164188672 Month 963;
BA_ "SPN" SG_ 2164188672 Day 962;
BA_ "SPN" SG_ 2164188672 Year 964;
BA_ "SPN" SG_ 2164188672 Local_minute_offset 1601;
BA_ "SPN" SG_ 2164188672 Local_hour_offset 1602;
BA_ "SPN" SG_ 2164188928 Total_Vehicle_Hours 246;
BA_ "SPN" SG_ 2164188928 Total_Power_Takeoff_Hours 248;
BA_ "SPN" SG_ 2164189184 Compass_Bearing 165;
BA_ "SPN" SG_ 2164189184 Navigation_Based_Vehicle_Speed 517;
BA_ "SPN" SG_ 2164189184 Pitch 583;
BA_ "SPN" SG_ 2164189184 Altitude 580;
BA_ "SPN" SG_ 2164189440 Engine_Trip_Fuel 182;
BA_ "SPN" SG_ 2164189440 Engine_Total_Fuel_Used 250;
BA_ "SPN" SG_ 2164189696 Axle_Location 928;
BA_ "SPN" SG_ 2164189696 Axle_Weight 582;
BA_ "SPN" SG_ 2164189696 Trailer_Weight 180;
BA_ "SPN" SG_ 2164189696 Cargo_Weight 181;
BA_ "SPN" SG_ 2164189952 Make 586;
BA_ "SPN" SG_ 2164189952 Model 587;
BA_ "SPN" SG_ 2164189952 Serial_Number 588;
BA_ "SPN" SG_ 2164189952 Unit_Number__Power_Unit_ 233;
BA_ "SPN" SG_ 2164190208 Vehicle_Identification_Number 237;
BA_ "SPN" SG_ 2164190464 Maximum_Vehicle_Speed_Limit 74;
BA_ "SPN" SG_ 2164190464 Cruise_Control_High_Set_Limit_Sp 87;
BA_ "SystemSignalLongSymbol" SG_ 2164190464 Cruise_Control_High_Set_Limit_Sp "Cruise Control High Set Limit Speed";
BA_ "SPN" SG_ 2164190464 Cruise_Control_Low_Set_Limit_Spe 88;
BA_ "SystemSignalLongSymbol" SG_ 2164190464 Cruise_Control_Low_Set_Limit_Spe "Cruise Control Low Set Limit Speed";
BA_ "SPN" SG_ 2164190720 Engine_Coolant_Temperature 110;
BA_ "SPN" SG_ 2164190720 Engine_Fuel_Temperature_1 174;
BA_ "SPN" SG_ 2164190720 Engine_Oil_Temperature_1 175;
BA_ "SPN" SG_ 2164190720 Engine_Turbocharger_Oil_Temperat 176;
BA_ "SystemSignalLongSymbol" SG_ 2164190720 Engine_Turbocharger_Oil_Temperat "Engine Turbocharger Oil Temperature";
BA_ "SPN" SG_ 2164190720 Engine_Intercooler_Temperature 52;
BA_ "SPN" SG_ 2164190720 Engine_Intercooler_Thermostat_Op 1134;
BA_ "SystemSignalLongSymbol" SG_ 2164190720 Engine_Intercooler_Thermostat_Op "Engine Intercooler Thermostat Opening";
BA_ "SPN" SG_ 2164190976 Engine_Fuel_Delivery_Pressure 94;
BA_ "SPN" SG_ 2164190976 Engine_Extended_Crankcase_Blow_b 22;
BA_ "SystemSignalLongSymbol" SG_ 2164190976 Engine_Extended_Crankcase_Blow_b "Engine Extended Crankcase Blow-by Pressure";
BA_ "SPN" SG_ 2164190976 Engine_Oil_Level 98;
BA_ "SPN" SG_ 2164190976 Engine_Oil_Pressure 100;
BA_ "SPN" SG_ 2164190976 Engine_Crankcase_Pressure 101;
BA_ "SPN" SG_ 2164190976 Engine_Coolant_Pressure 109;
BA_ "SPN" SG_ 2164190976 Engine_Coolant_Level 111;
BA_ "SPN" SG_ 2164191232 Power_Takeoff_Oil_Temperature 90;
BA_ "SPN" SG_ 2164191232 Power_Takeoff_Speed 186;
BA_ "SPN" SG_ 2164191232 Power_Takeoff_Set_Speed 187;
BA_ "SPN" SG_ 2164191232 Engine_PTO_Governor_Enable_Switc 980;
BA_ "SystemSignalLongSymbol" SG_ 2164191232 Engine_PTO_Governor_Enable_Switc "Engine PTO Governor Enable Switch";
BA_ "SPN" SG_ 2164191232 Engine_Remote_PTO_Governor_Prepr 979;
BA_ "SystemSignalLongSymbol" SG_ 2164191232 Engine_Remote_PTO_Governor_Prepr "Engine Remote PTO Governor Preprogrammed Speed Control Switch";
BA_ "SPN" SG_ 2164191232 Engine_Remote_PTO_Governor_Varia 978;
BA_ "SystemSignalLongSymbol" SG_ 2164191232 Engine_Remote_PTO_Governor_Varia "Engine Remote PTO Governor Variable Speed Control Switch";
BA_ "SPN" SG_ 2164191232 Engine_PTO_Governor_Set_Switch 984;
BA_ "SPN" SG_ 2164191232 Engine_PTO_Governor_Coast_Decele 983;
BA_ "SystemSignalLongSymbol" SG_ 2164191232 Engine_PTO_Governor_Coast_Decele "Engine PTO Governor Coast/Decelerate Switch";
BA_ "SPN" SG_ 2164191232 Engine_PTO_Governor_Resume_Switc 982;
BA_ "SystemSignalLongSymbol" SG_ 2164191232 Engine_PTO_Governor_Resume_Switc "Engine PTO Governor Resume Switch";
BA_ "SPN" SG_ 2164191232 Engine_PTO_Governor_Accelerate_S 981;
BA_ "SystemSignalLongSymbol" SG_ 2164191232 Engine_PTO_Governor_Accelerate_S "Engine PTO Governor Accelerate Switch";
BA_ "SPN" SG_ 2164191232 Operator_Engine_PTO_Governor_Mem 2897;
BA_ "SystemSignalLongSymbol" SG_ 2164191232 Operator_Engine_PTO_Governor_Mem "Operator Engine PTO Governor Memory Select Switch";
BA_ "SPN" SG_ 2164191232 Remote_PTO_Governor_Preprogramme 3447;
BA_ "SystemSignalLongSymbol" SG_ 2164191232 Remote_PTO_Governor_Preprogramme "Remote PTO Governor Preprogrammed Speed Control Switch #2";
BA_ "SPN" SG_ 2164191232 Auxiliary_Input_Ignore_Switch 3448;
BA_ "SPN" SG_ 2164191488 Two_Speed_Axle_Switch 69;
BA_ "SPN" SG_ 2164191488 Parking_Brake_Switch 70;
BA_ "SPN" SG_ 2164191488 Cruise_Control_Pause_Switch 1633;
BA_ "SPN" SG_ 2164191488 Park_Brake_Release_Inhibit_Reque 3807;
BA_ "SystemSignalLongSymbol" SG_ 2164191488 Park_Brake_Release_Inhibit_Reque "Park Brake Release Inhibit Request";
BA_ "SPN" SG_ 2164191488 Wheel_Based_Vehicle_Speed 84;
BA_ "SPN" SG_ 2164191488 Cruise_Control_Active 595;
BA_ "SPN" SG_ 2164191488 Cruise_Control_Enable_Switch 596;
BA_ "SPN" SG_ 2164191488 Brake_Switch 597;
BA_ "SPN" SG_ 2164191488 Clutch_Switch 598;
BA_ "SPN" SG_ 2164191488 Cruise_Control_Set_Switch 599;
BA_ "SPN" SG_ 2164191488 Cruise_Control_Coast__Decelerate 600;
BA_ "SystemSignalLongSymbol" SG_ 2164191488 Cruise_Control_Coast__Decelerate "Cruise Control Coast (Decelerate) Switch";
BA_ "SPN" SG_ 2164191488 Cruise_Control_Resume_Switch 601;
BA_ "SPN" SG_ 2164191488 Cruise_Control_Accelerate_Switch 602;
BA_ "SPN" SG_ 2164191488 Cruise_Control_Set_Speed 86;
BA_ "SPN" SG_ 2164191488 PTO_Governor_State 976;
BA_ "SPN" SG_ 2164191488 Cruise_Control_States 527;
BA_ "SPN" SG_ 2164191488 Engine_Idle_Increment_Switch 968;
BA_ "SPN" SG_ 2164191488 Engine_Idle_Decrement_Switch 967;
BA_ "SPN" SG_ 2164191488 Engine_Test_Mode_Switch 966;
BA_ "SPN" SG_ 2164191488 Engine_Shutdown_Override_Switch 1237;
BA_ "SPN" SG_ 2164191744 Engine_Fuel_Rate 183;
BA_ "SPN" SG_ 2164191744 Engine_Instantaneous_Fuel_Econom 184;
BA_ "SystemSignalLongSymbol" SG_ 2164191744 Engine_Instantaneous_Fuel_Econom "Engine Instantaneous Fuel Economy";
BA_ "SPN" SG_ 2164191744 Engine_Average_Fuel_Economy 185;
BA_ "SPN" SG_ 2164191744 Engine_Throttle_Position 51;
BA_ "SPN" SG_ 2164191744 Engine_Throttle_2_Position 3673;
BA_ "SPN" SG_ 2164192000 Latitude 584;
BA_ "SPN" SG_ 2164192000 Longitude 585;
BA_ "SPN" SG_ 2164192256 Tire_Location 929;
BA_ "SPN" SG_ 2164192256 Tire_Pressure 241;
BA_ "SPN" SG_ 2164192256 Tire_Temperature 242;
BA_ "SPN" SG_ 2164192256 CTI_Wheel_Sensor_Status 1699;
BA_ "SPN" SG_ 2164192256 CTI_Tire_Status 1698;
BA_ "SPN" SG_ 2164192256 CTI_Wheel_End_Electrical_Fault 1697;
BA_ "SPN" SG_ 2164192256 Tire_Air_Leakage_Rate 2586;
BA_ "SPN" SG_ 2164192256 Tire_Pressure_Threshold_Detectio 2587;
BA_ "SystemSignalLongSymbol" SG_ 2164192256 Tire_Pressure_Threshold_Detectio "Tire Pressure Threshold Detection";
BA_ "SPN" SG_ 2164192512 Barometric_Pressure 108;
BA_ "SPN" SG_ 2164192512 Cab_Interior_Temperature 170;
BA_ "SPN" SG_ 2164192512 Ambient_Air_Temperature 171;
BA_ "SPN" SG_ 2164192512 Engine_Air_Inlet_Temperature 172;
BA_ "SPN" SG_ 2164192512 Road_Surface_Temperature 79;
BA_ "SPN" SG_ 2164192768 Engine_Diesel_Particulate_Filter 81;
BA_ "SystemSignalLongSymbol" SG_ 2164192768 Engine_Diesel_Particulate_Filter "Engine Diesel Particulate Filter Inlet Pressure";
BA_ "SPN" SG_ 2164192768 Engine_Intake_Manifold__1_Pressu 102;
BA_ "SystemSignalLongSymbol" SG_ 2164192768 Engine_Intake_Manifold__1_Pressu "Engine Intake Manifold #1 Pressure";
BA_ "SPN" SG_ 2164192768 Engine_Intake_Manifold_1_Tempera 105;
BA_ "SystemSignalLongSymbol" SG_ 2164192768 Engine_Intake_Manifold_1_Tempera "Engine Intake Manifold 1 Temperature";
BA_ "SPN" SG_ 2164192768 Engine_Air_Inlet_Pressure 106;
BA_ "SPN" SG_ 2164192768 Engine_Air_Filter_1_Differential 107;
BA_ "SystemSignalLongSymbol" SG_ 2164192768 Engine_Air_Filter_1_Differential "Engine Air Filter 1 Differential Pressure";
BA_ "SPN" SG_ 2164192768 Engine_Exhaust_Gas_Temperature 173;
BA_ "SPN" SG_ 2164192768 Engine_Coolant_Filter_Differenti 112;
BA_ "SystemSignalLongSymbol" SG_ 2164192768 Engine_Coolant_Filter_Differenti "Engine Coolant Filter Differential Pressure";
BA_ "SPN" SG_ 2164193024 Net_Battery_Current 114;
BA_ "SPN" SG_ 2164193024 Alternator_Current 115;
BA_ "SPN" SG_ 2164193024 Charging_System_Potential__Volta 167;
BA_ "SystemSignalLongSymbol" SG_ 2164193024 Charging_System_Potential__Volta "Charging System Potential (Voltage)";
BA_ "SPN" SG_ 2164193024 Battery_Potential___Power_Input_ 168;
BA_ "SystemSignalLongSymbol" SG_ 2164193024 Battery_Potential___Power_Input_ "Battery Potential / Power Input 1";
BA_ "SPN" SG_ 2164193024 Keyswitch_Battery_Potential 158;
BA_ "SPN" SG_ 2164193280 Clutch_Pressure 123;
BA_ "SPN" SG_ 2164193280 Transmission_Oil_Level 124;
BA_ "SPN" SG_ 2164193280 Transmission_Filter_Differential 126;
BA_ "SystemSignalLongSymbol" SG_ 2164193280 Transmission_Filter_Differential "Transmission Filter Differential Pressure";
BA_ "SPN" SG_ 2164193280 Transmission_Oil_Pressure 127;
BA_ "SPN" SG_ 2164193280 Transmission_Oil_Temperature 177;
BA_ "SPN" SG_ 2164193280 Transmission_Oil_Level_High___Lo 3027;
BA_ "SystemSignalLongSymbol" SG_ 2164193280 Transmission_Oil_Level_High___Lo "Transmission Oil Level High / Low";
BA_ "SPN" SG_ 2164193280 Transmission_Oil_Level_Countdown 3028;
BA_ "SystemSignalLongSymbol" SG_ 2164193280 Transmission_Oil_Level_Countdown "Transmission Oil Level Countdown Timer";
BA_ "SPN" SG_ 2164193280 Transmission_Oil_Level_Measureme 3026;
BA_ "SystemSignalLongSymbol" SG_ 2164193280 Transmission_Oil_Level_Measureme "Transmission Oil Level Measurement Status";
BA_ "SPN" SG_ 2164193536 Steering_Axle_Temperature 75;
BA_ "SPN" SG_ 2164193536 Drive_Axle_Location 930;
BA_ "SPN" SG_ 2164193536 Drive_Axle_Lift_Air_Pressure 579;
BA_ "SPN" SG_ 2164193536 Drive_Axle_Temperature 578;
BA_ "SPN" SG_ 2164193536 Drive_Axle_Lube_Pressure 2613;
BA_ "SPN" SG_ 2164193536 Steering_Axle_Lube_Pressure 2614;
BA_ "SPN" SG_ 2164193792 Brake_Application_Pressure 116;
BA_ "SPN" SG_ 2164193792 Brake_Primary_Pressure 117;
BA_ "SPN" SG_ 2164193792 Brake_Secondary_Pressure 118;
BA_ "SPN" SG_ 2164193792 Parking_Brake_Actuator 619;
BA_ "SPN" SG_ 2164193792 Parking_Brake_Red_Warning_Signal 3557;
BA_ "SPN" SG_ 2164193792 Park_Brake_Release_Inhibit_Statu 3808;
BA_ "SystemSignalLongSymbol" SG_ 2164193792 Park_Brake_Release_Inhibit_Statu "Park Brake Release Inhibit Status";
BA_ "SPN" SG_ 2164194048 Hydraulic_Retarder_Pressure 119;
BA_ "SPN" SG_ 2164194048 Hydraulic_Retarder_Oil_Temperatu 120;
BA_ "SystemSignalLongSymbol" SG_ 2164194048 Hydraulic_Retarder_Oil_Temperatu "Hydraulic Retarder Oil Temperature";
BA_ "SPN" SG_ 2164194304 Washer_Fluid_Level 80;
BA_ "SPN" SG_ 2164194304 Fuel_Level_1 96;
BA_ "SPN" SG_ 2164194304 Engine_Fuel_Filter_Differential_ 95;
BA_ "SystemSignalLongSymbol" SG_ 2164194304 Engine_Fuel_Filter_Differential_ "Engine Fuel Filter Differential Pressure";
BA_ "SPN" SG_ 2164194304 Engine_Oil_Filter_Differential_P 99;
BA_ "SystemSignalLongSymbol" SG_ 2164194304 Engine_Oil_Filter_Differential_P "Engine Oil Filter Differential Pressure";
BA_ "SPN" SG_ 2164194304 Cargo_Ambient_Temperature 169;
BA_ "SPN" SG_ 2164194304 Fuel_Level_2 38;
BA_ "SPN" SG_ 2164194560 Engine_Blower_Bypass_Valve_Posit 72;
BA_ "SystemSignalLongSymbol" SG_ 2164194560 Engine_Blower_Bypass_Valve_Posit "Engine Blower Bypass Valve Position";
BA_ "SPN" SG_ 2164194560 Engine_Gas_Supply_Pressure 159;
BA_ "SPN" SG_ 2164194816 Auxiliary_Pump_Pressure 73;
BA_ "SPN" SG_ 2164195072 Water_In_Fuel_Indicator 97;
